VERSION "canboat-NMEA2000-curated"

NS_ :

BS_:

BU_: Vector__XXX
BO_ 2583631104 PGN_130837_maretronSwitchStatusTimer: 23 Vector__XXX
 SG_ Manufacturer_Code : 0|11@1+ (1.0,0) [0|2047] "" Vector__XXX
 SG_ Industry_Code : 13|3@1+ (1.0,0) [0|7] "" Vector__XXX
 SG_ Instance : 16|8@1+ (1.0,0) [0|255] "" Vector__XXX
 SG_ Indicator_Number : 24|8@1+ (1.0,0) [0|255] "" Vector__XXX
 SG_ Start_Date : 32|16@1+ (1.0,0) [0|65535] "" Vector__XXX
 SG_ Start_Time : 48|32@1+ (0.0001,0) [0.0|86401.0] "" Vector__XXX
 SG_ Accumulated_OFF_Period : 80|32@1+ (1.0,0) [0|4294967295] "" Vector__XXX
 SG_ Accumulated_ON_Period : 112|32@1+ (1.0,0) [0|4294967295] "" Vector__XXX
 SG_ Accumulated_ERROR_Period : 144|32@1+ (1.0,0) [0|4294967295] "" Vector__XXX
 SG_ Switch_Status : 176|2@1+ (1.0,0) [0|3] "" Vector__XXX

BO_ 2583631104 PGN_130837_simnetFuelFlowTurbineConfiguration: 8 Vector__XXX
 SG_ Manufacturer_Code : 0|11@1+ (1.0,0) [0|2047] "" Vector__XXX
 SG_ Industry_Code : 13|3@1+ (1.0,0) [0|7] "" Vector__XXX

BO_ 2583631104 PGN_130837_suzukiEngineSensorData: 8 Vector__XXX
 SG_ Manufacturer_Code : 0|11@1+ (1.0,0) [0|2047] "" Vector__XXX
 SG_ Industry_Code : 13|3@1+ (1.0,0) [0|7] "" Vector__XXX

BO_ 2583631360 PGN_130838_maretronBnwas: 223 Vector__XXX
 SG_ Manufacturer_Code : 0|11@1+ (1.0,0) [0|2047] "" Vector__XXX
 SG_ Industry_Code : 13|3@1+ (1.0,0) [0|7] "" Vector__XXX
 SG_ Data : 16|1768@1+ (1.0,0) [0|16635364987126134419907490844611231857889171561340108669757218330385068731224834608417815051548234195819468783937845710359164977421616154908223175941492902641772198991471137845920843845811776377869137773379678289214194183661112800944378464511794046030758602257005203964634516091405743061582849883160885255175229773660916874237270946647032424101972117051870087763059119895517977437771543686400460392041962138103436564399831189767740372774280024852942859855049773927338342604171805121253257539126169331943684033945189625789470637817855] "" Vector__XXX

BO_ 2583631360 PGN_130838_simnetFluidLevelWarning: 8 Vector__XXX
 SG_ Manufacturer_Code : 0|11@1+ (1.0,0) [0|2047] "" Vector__XXX
 SG_ Industry_Code : 13|3@1+ (1.0,0) [0|7] "" Vector__XXX

BO_ 2583631360 PGN_130838_suzukiFuelManagement: 8 Vector__XXX
 SG_ Manufacturer_Code : 0|11@1+ (1.0,0) [0|2047] "" Vector__XXX
 SG_ Industry_Code : 13|3@1+ (1.0,0) [0|7] "" Vector__XXX

BO_ 2583631616 PGN_130839_simnetPressureSensorConfiguration: 8 Vector__XXX
 SG_ Manufacturer_Code : 0|11@1+ (1.0,0) [0|2047] "" Vector__XXX
 SG_ Industry_Code : 13|3@1+ (1.0,0) [0|7] "" Vector__XXX

BO_ 2583631872 PGN_130840_maretronGenericSensor: 9 Vector__XXX
 SG_ Manufacturer_Code : 0|11@1+ (1.0,0) [0|2047] "" Vector__XXX
 SG_ Industry_Code : 13|3@1+ (1.0,0) [0|7] "" Vector__XXX
 SG_ Data_Instance : 16|8@1+ (1.0,0) [0|255] "" Vector__XXX
 SG_ Data_Format : 24|16@1+ (1.0,0) [0|65535] "" Vector__XXX
 SG_ Value : 40|32@1+ (1.0,0) [0|4294967295] "" Vector__XXX

BO_ 2382305280 PGN_130840_simnetDataSourceSelection: 17 Vector__XXX
 SG_ Manufacturer_Code : 0|11@1+ (1.0,0) [0|2047] "" Vector__XXX
 SG_ Industry_Code : 13|3@1+ (1.0,0) [0|7] "" Vector__XXX
 SG_ Data_Type : 24|8@1+ (1.0,0) [0|255] "" Vector__XXX
 SG_ Source_Class : 32|8@1+ (1.0,0) [0|255] "" Vector__XXX
 SG_ Source_Address : 40|8@1+ (1.0,0) [0|255] "" Vector__XXX
 SG_ Change_Counter : 56|8@1+ (1.0,0) [0|255] "" Vector__XXX
 SG_ Source : 64|64@1+ (1.0,0) [0|18446744073709551615] "" Vector__XXX

BO_ 2583632128 PGN_130841_maretronCanFrameForwarding: 223 Vector__XXX
 SG_ Manufacturer_Code : 0|11@1+ (1.0,0) [0|2047] "" Vector__XXX
 SG_ Industry_Code : 13|3@1+ (1.0,0) [0|7] "" Vector__XXX
 SG_ Data : 16|1768@1+ (1.0,0) [0|16635364987126134419907490844611231857889171561340108669757218330385068731224834608417815051548234195819468783937845710359164977421616154908223175941492902641772198991471137845920843845811776377869137773379678289214194183661112800944378464511794046030758602257005203964634516091405743061582849883160885255175229773660916874237270946647032424101972117051870087763059119895517977437771543686400460392041962138103436564399831189767740372774280024852942859855049773927338342604171805121253257539126169331943684033945189625789470637817855] "" Vector__XXX

BO_ 2583632384 PGN_130842_furunoSixDegreesOfFreedomMovement: 29 Vector__XXX
 SG_ Manufacturer_Code : 0|11@1+ (1.0,0) [0|2047] "" Vector__XXX
 SG_ Industry_Code : 13|3@1+ (1.0,0) [0|7] "" Vector__XXX
 SG_ A : 16|32@1- (1.0,0) [-2147483648|2147483647] "" Vector__XXX
 SG_ B : 48|32@1- (1.0,0) [-2147483648|2147483647] "" Vector__XXX
 SG_ C : 80|32@1- (1.0,0) [-2147483648|2147483647] "" Vector__XXX
 SG_ D : 112|8@1- (1.0,0) [-128|127] "" Vector__XXX
 SG_ Roll_Rate : 120|32@1- (1.7453292519943296e-05,0) [-37480.66029033894|37480.66027288565] "" Vector__XXX
 SG_ Pitch_Rate : 152|32@1- (1.7453292519943296e-05,0) [-37480.66029033894|37480.66027288565] "" Vector__XXX
 SG_ Yaw_Rate : 184|32@1- (1.7453292519943296e-05,0) [-37480.66029033894|37480.66027288565] "" Vector__XXX
 SG_ I : 216|16@1- (1.0,0) [-32768|32767] "" Vector__XXX

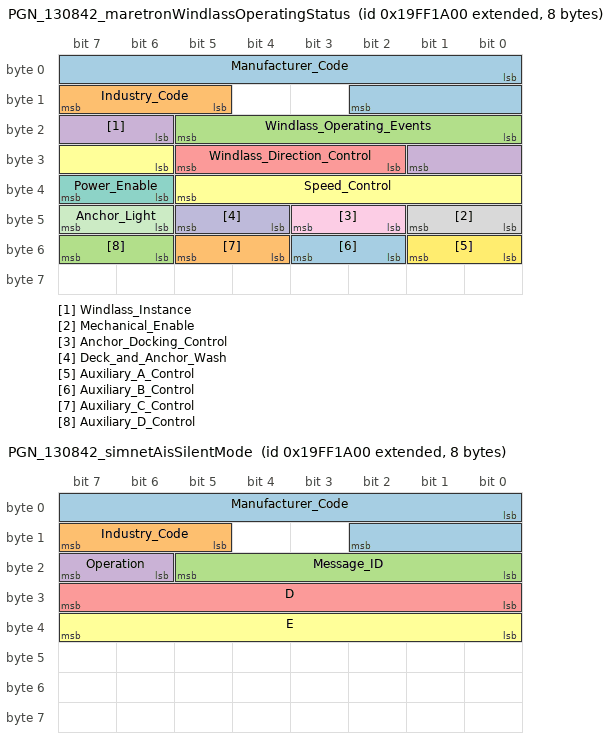
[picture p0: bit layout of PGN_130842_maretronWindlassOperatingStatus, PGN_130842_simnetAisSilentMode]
BO_ 2583632384 PGN_130842_maretronWindlassOperatingStatus: 8 Vector__XXX
 SG_ Manufacturer_Code : 0|11@1+ (1.0,0) [0|2047] "" Vector__XXX
 SG_ Industry_Code : 13|3@1+ (1.0,0) [0|7] "" Vector__XXX
 SG_ Windlass_Operating_Events : 16|6@1+ (1.0,0) [0|63] "" Vector__XXX
 SG_ Windlass_Instance : 22|4@1+ (1.0,0) [0|15] "" Vector__XXX
 SG_ Windlass_Direction_Control : 26|4@1+ (1.0,0) [0|15] "" Vector__XXX
 SG_ Speed_Control : 30|8@1+ (1.0,0) [0|255] "" Vector__XXX
 SG_ Power_Enable : 38|2@1+ (1.0,0) [0|3] "" Vector__XXX
 SG_ Mechanical_Enable : 40|2@1+ (1.0,0) [0|3] "" Vector__XXX
 SG_ Anchor_Docking_Control : 42|2@1+ (1.0,0) [0|3] "" Vector__XXX
 SG_ Deck_and_Anchor_Wash : 44|2@1+ (1.0,0) [0|3] "" Vector__XXX
 SG_ Anchor_Light : 46|2@1+ (1.0,0) [0|3] "" Vector__XXX
 SG_ Auxiliary_A_Control : 48|2@1+ (1.0,0) [0|3] "" Vector__XXX
 SG_ Auxiliary_B_Control : 50|2@1+ (1.0,0) [0|3] "" Vector__XXX
 SG_ Auxiliary_C_Control : 52|2@1+ (1.0,0) [0|3] "" Vector__XXX
 SG_ Auxiliary_D_Control : 54|2@1+ (1.0,0) [0|3] "" Vector__XXX

BO_ 2583632384 PGN_130842_simnetAisClassBStaticDataMsg24PartA: 29 Vector__XXX
 SG_ Manufacturer_Code : 0|11@1+ (1.0,0) [0|2047] "" Vector__XXX
 SG_ Industry_Code : 13|3@1+ (1.0,0) [0|7] "" Vector__XXX
 SG_ Message_ID : 16|6@1+ (1.0,0) [0|63] "" Vector__XXX
 SG_ Repeat_Indicator : 22|2@1+ (1.0,0) [0|3] "" Vector__XXX
 SG_ D : 24|8@1+ (1.0,0) [0|255] "" Vector__XXX
 SG_ E : 32|8@1+ (1.0,0) [0|255] "" Vector__XXX
 SG_ User_ID : 40|32@1+ (1.0,0) [2000000.0|999999999.0] "" Vector__XXX
 SG_ Name : 72|160@1+ (1.0,0) [0|1461501637330902918203684832716283019655932542975] "" Vector__XXX

BO_ 2583632384 PGN_130842_simnetAisClassBStaticDataMsg24PartB: 37 Vector__XXX
 SG_ Manufacturer_Code : 0|11@1+ (1.0,0) [0|2047] "" Vector__XXX
 SG_ Industry_Code : 13|3@1+ (1.0,0) [0|7] "" Vector__XXX
 SG_ Message_ID : 16|6@1+ (1.0,0) [0|63] "" Vector__XXX
 SG_ Repeat_Indicator : 22|2@1+ (1.0,0) [0|3] "" Vector__XXX
 SG_ D : 24|8@1+ (1.0,0) [0|255] "" Vector__XXX
 SG_ E : 32|8@1+ (1.0,0) [0|255] "" Vector__XXX
 SG_ User_ID : 40|32@1+ (1.0,0) [2000000.0|999999999.0] "" Vector__XXX
 SG_ Type_of_ship : 72|8@1+ (1.0,0) [0|255] "" Vector__XXX
 SG_ Vendor_ID : 80|56@1+ (1.0,0) [0|72057594037927935] "" Vector__XXX
 SG_ Callsign : 136|56@1+ (1.0,0) [0|72057594037927935] "" Vector__XXX
 SG_ Length : 192|16@1+ (0.1,0) [0.0|6553.5] "" Vector__XXX
 SG_ Beam : 208|16@1+ (0.1,0) [0.0|6553.5] "" Vector__XXX
 SG_ Position_reference_from_Starboard : 224|16@1+ (0.1,0) [0.0|6553.5] "" Vector__XXX
 SG_ Position_reference_from_Bow : 240|16@1+ (0.1,0) [0.0|6553.5] "" Vector__XXX
 SG_ Mothership_User_ID : 256|32@1+ (1.0,0) [2000000.0|999999999.0] "" Vector__XXX
 SG_ Spare : 288|6@1+ (1.0,0) [0|63] "" Vector__XXX

BO_ 2583632384 PGN_130842_simnetAisSilentMode: 8 Vector__XXX
 SG_ Manufacturer_Code : 0|11@1+ (1.0,0) [0|2047] "" Vector__XXX
 SG_ Industry_Code : 13|3@1+ (1.0,0) [0|7] "" Vector__XXX
 SG_ Message_ID : 16|6@1+ (1.0,0) [0|63] "" Vector__XXX
 SG_ Operation : 22|2@1+ (1.0,0) [0|3] "" Vector__XXX
 SG_ D : 24|8@1+ (1.0,0) [0|255] "" Vector__XXX
 SG_ E : 32|8@1+ (1.0,0) [0|255] "" Vector__XXX

BO_ 2583632640 PGN_130843_furunoHeelAngleRollInformation: 10 Vector__XXX
 SG_ Manufacturer_Code : 0|11@1+ (1.0,0) [0|2047] "" Vector__XXX
 SG_ Industry_Code : 13|3@1+ (1.0,0) [0|7] "" Vector__XXX
 SG_ Heel : 16|16@1- (0.0001,0) [-3.2768|3.2767] "" Vector__XXX
 SG_ Field_4 : 32|16@1- (0.0001,0) [-3.2768|3.2767] "" Vector__XXX
 SG_ Field_6 : 48|16@1- (0.0001,0) [-3.2768|3.2767] "" Vector__XXX
 SG_ Field_8 : 64|16@1- (0.0001,0) [-3.2768|3.2767] "" Vector__XXX

BO_ 2583632640 PGN_130843_maretronWindlassControlCommand: 223 Vector__XXX
 SG_ Manufacturer_Code : 0|11@1+ (1.0,0) [0|2047] "" Vector__XXX
 SG_ Industry_Code : 13|3@1+ (1.0,0) [0|7] "" Vector__XXX
 SG_ Data : 16|1768@1+ (1.0,0) [0|16635364987126134419907490844611231857889171561340108669757218330385068731224834608417815051548234195819468783937845710359164977421616154908223175941492902641772198991471137845920843845811776377869137773379678289214194183661112800944378464511794046030758602257005203964634516091405743061582849883160885255175229773660916874237270946647032424101972117051870087763059119895517977437771543686400460392041962138103436564399831189767740372774280024852942859855049773927338342604171805121253257539126169331943684033945189625789470637817855] "" Vector__XXX

BO_ 2583632640 PGN_130843_simnetSonarStatusFrequencyAndDspVoltage: 8 Vector__XXX
 SG_ Manufacturer_Code : 0|11@1+ (1.0,0) [0|2047] "" Vector__XXX
 SG_ Industry_Code : 13|3@1+ (1.0,0) [0|7] "" Vector__XXX

BO_ 2583632896 PGN_130844_carlingProprietary: 223 Vector__XXX
 SG_ Manufacturer_Code : 0|11@1+ (1.0,0) [0|2047] "" Vector__XXX
 SG_ Industry_Code : 13|3@1+ (1.0,0) [0|7] "" Vector__XXX
 SG_ Data : 16|1768@1+ (1.0,0) [0|16635364987126134419907490844611231857889171561340108669757218330385068731224834608417815051548234195819468783937845710359164977421616154908223175941492902641772198991471137845920843845811776377869137773379678289214194183661112800944378464511794046030758602257005203964634516091405743061582849883160885255175229773660916874237270946647032424101972117051870087763059119895517977437771543686400460392041962138103436564399831189767740372774280024852942859855049773927338342604171805121253257539126169331943684033945189625789470637817855] "" Vector__XXX

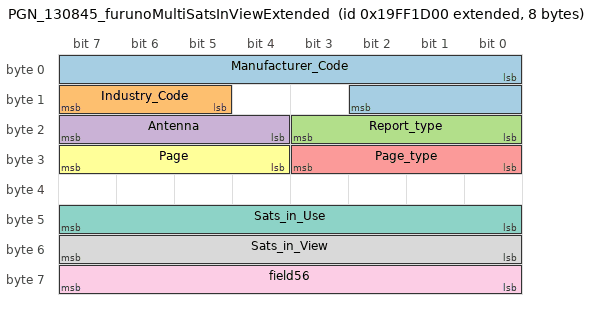
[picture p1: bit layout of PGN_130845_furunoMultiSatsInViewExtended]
BO_ 2583633152 PGN_130845_furunoMultiSatsInViewExtended: 8 Vector__XXX
 SG_ Manufacturer_Code : 0|11@1+ (1.0,0) [0|2047] "" Vector__XXX
 SG_ Industry_Code : 13|3@1+ (1.0,0) [0|7] "" Vector__XXX
 SG_ Report_type : 16|4@1+ (1.0,0) [0|15] "" Vector__XXX
 SG_ Antenna : 20|4@1+ (1.0,0) [0|15] "" Vector__XXX
 SG_ Page_type : 24|4@1+ (1.0,0) [0|15] "" Vector__XXX
 SG_ Page : 28|4@1+ (1.0,0) [0|15] "" Vector__XXX
 SG_ Sats_in_Use : 40|8@1+ (1.0,0) [0|255] "" Vector__XXX
 SG_ Sats_in_View : 48|8@1+ (1.0,0) [0|255] "" Vector__XXX
 SG_ field56 : 56|8@1+ (1.0,0) [0|255] "" Vector__XXX

BO_ 2583633152 PGN_130845_maretronDcEnergy: 223 Vector__XXX
 SG_ Manufacturer_Code : 0|11@1+ (1.0,0) [0|2047] "" Vector__XXX
 SG_ Industry_Code : 13|3@1+ (1.0,0) [0|7] "" Vector__XXX
 SG_ Data : 16|1768@1+ (1.0,0) [0|16635364987126134419907490844611231857889171561340108669757218330385068731224834608417815051548234195819468783937845710359164977421616154908223175941492902641772198991471137845920843845811776377869137773379678289214194183661112800944378464511794046030758602257005203964634516091405743061582849883160885255175229773660916874237270946647032424101972117051870087763059119895517977437771543686400460392041962138103436564399831189767740372774280024852942859855049773927338342604171805121253257539126169331943684033945189625789470637817855] "" Vector__XXX

BO_ 2583633152 PGN_130845_simnetKeyValue: 11 Vector__XXX
 SG_ Manufacturer_Code : 0|11@1+ (1.0,0) [0|2047] "" Vector__XXX
 SG_ Industry_Code : 13|3@1+ (1.0,0) [0|7] "" Vector__XXX
 SG_ Address : 16|8@1+ (1.0,0) [0|255] "" Vector__XXX
 SG_ Instance : 24|8@1+ (1.0,0) [0|255] "" Vector__XXX
 SG_ Network_Group : 32|8@1+ (1.0,0) [0|255] "" Vector__XXX
 SG_ Source : 40|8@1+ (1.0,0) [0|255] "" Vector__XXX
 SG_ Key : 48|24@1+ (1.0,0) [0|16777215] "" Vector__XXX
 SG_ Operation : 72|8@1+ (1.0,0) [0|255] "" Vector__XXX
 SG_ Value : 80|8@1+ (1.0,0) [0|255] "" Vector__XXX

CM_ BO_ 2583631104 "NMEA2000: PGN 130837 - Maretron: Switch Status Timer (type: Fast)";
CM_ BO_ 2583631104 "NMEA2000: PGN 130837 - Simnet: Fuel Flow Turbine Configuration (type: Fast)";
CM_ BO_ 2583631104 "NMEA2000: PGN 130837 - Suzuki: Engine Sensor Data (type: Fast)";
CM_ BO_ 2583631360 "NMEA2000: PGN 130838 - Maretron: BNWAS (type: Fast)";
CM_ BO_ 2583631360 "NMEA2000: PGN 130838 - Simnet: Fluid Level Warning (type: Fast)";
CM_ BO_ 2583631360 "NMEA2000: PGN 130838 - Suzuki: Fuel Management (type: Fast)";
CM_ BO_ 2583631616 "NMEA2000: PGN 130839 - Simnet: Pressure Sensor Configuration (type: Fast)";
CM_ BO_ 2583631872 "NMEA2000: PGN 130840 - Maretron: Generic Sensor (type: Fast)";
CM_ BO_ 2382305280 "NMEA2000: PGN 130840 - Simnet: Data Source Selection (type: Fast)";
CM_ BO_ 2583632128 "NMEA2000: PGN 130841 - Maretron: CAN Frame Forwarding (type: Fast)";
CM_ BO_ 2583632384 "NMEA2000: PGN 130842 - Furuno: Six Degrees Of Freedom Movement (type: Fast)";
CM_ BO_ 2583632384 "NMEA2000: PGN 130842 - Maretron: Windlass Operating Status (type: Fast)";
CM_ BO_ 2583632384 "NMEA2000: PGN 130842 - Simnet: AIS Class B static data (msg 24 Part A) (type: Fast)";
CM_ BO_ 2583632384 "NMEA2000: PGN 130842 - Simnet: AIS Class B static data (msg 24 Part B) (type: Fast)";
CM_ BO_ 2583632384 "NMEA2000: PGN 130842 - Simnet: AIS Silent Mode (type: Fast)";
CM_ BO_ 2583632640 "NMEA2000: PGN 130843 - Furuno: Heel Angle, Roll Information (type: Fast)";
CM_ BO_ 2583632640 "NMEA2000: PGN 130843 - Maretron: Windlass Control Command (type: Fast)";
CM_ BO_ 2583632640 "NMEA2000: PGN 130843 - Simnet: Sonar Status, Frequency and DSP Voltage (type: Fast)";
CM_ BO_ 2583632896 "NMEA2000: PGN 130844 - Carling: Proprietary (type: Fast)";
CM_ BO_ 2583633152 "NMEA2000: PGN 130845 - Furuno: Multi Sats In View Extended (type: Fast)";
CM_ BO_ 2583633152 "NMEA2000: PGN 130845 - Maretron: DC Energy (type: Fast)";
CM_ BO_ 2583633152 "NMEA2000: PGN 130845 - Simnet: Key Value (type: Fast)";
CM_ SG_ 2583631104 Manufacturer_Code "Maretron; canboat type: LOOKUP";
CM_ SG_ 2583631104 Industry_Code "Marine Industry; canboat type: LOOKUP";
CM_ SG_ 2583631104 Instance "canboat type: UINT8";
CM_ SG_ 2583631104 Indicator_Number "canboat type: UINT8";
CM_ SG_ 2583631104 Start_Date "canboat type: DATE";
CM_ SG_ 2583631104 Start_Time "Seconds since midnight; canboat type: TIME";
CM_ SG_ 2583631104 Accumulated_OFF_Period "canboat type: DURATION_UFIX32_S";
CM_ SG_ 2583631104 Accumulated_ON_Period "canboat type: DURATION_UFIX32_S";
CM_ SG_ 2583631104 Accumulated_ERROR_Period "canboat type: DURATION_UFIX32_S";
CM_ SG_ 2583631104 Switch_Status "canboat type: LOOKUP";
CM_ SG_ 2583631104 Manufacturer_Code "Simrad; canboat type: LOOKUP";
CM_ SG_ 2583631104 Industry_Code "Marine Industry; canboat type: LOOKUP";
CM_ SG_ 2583631104 Manufacturer_Code "Suzuki Motor Corporation; canboat type: LOOKUP";
CM_ SG_ 2583631104 Industry_Code "Marine Industry; canboat type: LOOKUP";
CM_ SG_ 2583631360 Manufacturer_Code "Maretron; canboat type: LOOKUP";
CM_ SG_ 2583631360 Industry_Code "Marine Industry; canboat type: LOOKUP";
CM_ SG_ 2583631360 Data "canboat type: BINARY";
CM_ SG_ 2583631360 Manufacturer_Code "Simrad; canboat type: LOOKUP";
CM_ SG_ 2583631360 Industry_Code "Marine Industry; canboat type: LOOKUP";
CM_ SG_ 2583631360 Manufacturer_Code "Suzuki Motor Corporation; canboat type: LOOKUP";
CM_ SG_ 2583631360 Industry_Code "Marine Industry; canboat type: LOOKUP";
CM_ SG_ 2583631616 Manufacturer_Code "Simrad; canboat type: LOOKUP";
CM_ SG_ 2583631616 Industry_Code "Marine Industry; canboat type: LOOKUP";
CM_ SG_ 2583631872 Manufacturer_Code "Maretron; canboat type: LOOKUP";
CM_ SG_ 2583631872 Industry_Code "Marine Industry; canboat type: LOOKUP";
CM_ SG_ 2583631872 Data_Instance "canboat type: UINT8";
CM_ SG_ 2583631872 Data_Format "canboat type: UINT16";
CM_ SG_ 2583631872 Value "canboat type: BINARY";
CM_ SG_ 2382305280 Manufacturer_Code "Simrad; canboat type: LOOKUP";
CM_ SG_ 2382305280 Industry_Code "Marine Industry; canboat type: LOOKUP";
CM_ SG_ 2382305280 Data_Type "canboat type: LOOKUP";
CM_ SG_ 2382305280 Source_Class "Class of source for this Data Type, constant per Data Type: observed as 1 for direct sensor/navigation sources and 100 for autopilot-provided sources; canboat type: UINT8";
CM_ SG_ 2382305280 Source_Address "canboat type: UINT8";
CM_ SG_ 2382305280 Change_Counter "canboat type: UINT8";
CM_ SG_ 2382305280 Source "canboat type: ISO_NAME";
CM_ SG_ 2583632128 Manufacturer_Code "Maretron; canboat type: LOOKUP";
CM_ SG_ 2583632128 Industry_Code "Marine Industry; canboat type: LOOKUP";
CM_ SG_ 2583632128 Data "canboat type: BINARY";
CM_ SG_ 2583632384 Manufacturer_Code "Furuno; canboat type: LOOKUP";
CM_ SG_ 2583632384 Industry_Code "Marine Industry; canboat type: LOOKUP";
CM_ SG_ 2583632384 A "canboat type: INT32";
CM_ SG_ 2583632384 B "canboat type: INT32";
CM_ SG_ 2583632384 C "canboat type: INT32";
CM_ SG_ 2583632384 D "canboat type: INT8";
CM_ SG_ 2583632384 Roll_Rate "canboat type: ROTATION_FIX32_MDEG_S";
CM_ SG_ 2583632384 Pitch_Rate "canboat type: ROTATION_FIX32_MDEG_S";
CM_ SG_ 2583632384 Yaw_Rate "canboat type: ROTATION_FIX32_MDEG_S";
CM_ SG_ 2583632384 I "canboat type: INT16";
CM_ SG_ 2583632384 Manufacturer_Code "Maretron; canboat type: LOOKUP";
CM_ SG_ 2583632384 Industry_Code "Marine Industry; canboat type: LOOKUP";
CM_ SG_ 2583632384 Windlass_Operating_Events "canboat type: UNSIGNED_INTEGER";
CM_ SG_ 2583632384 Windlass_Instance "canboat type: UNSIGNED_INTEGER";
CM_ SG_ 2583632384 Windlass_Direction_Control "canboat type: UNSIGNED_INTEGER";
CM_ SG_ 2583632384 Speed_Control "canboat type: UINT8";
CM_ SG_ 2583632384 Power_Enable "canboat type: LOOKUP";
CM_ SG_ 2583632384 Mechanical_Enable "canboat type: LOOKUP";
CM_ SG_ 2583632384 Anchor_Docking_Control "canboat type: LOOKUP";
CM_ SG_ 2583632384 Deck_and_Anchor_Wash "canboat type: LOOKUP";
CM_ SG_ 2583632384 Anchor_Light "canboat type: LOOKUP";
CM_ SG_ 2583632384 Auxiliary_A_Control "canboat type: LOOKUP";
CM_ SG_ 2583632384 Auxiliary_B_Control "canboat type: LOOKUP";
CM_ SG_ 2583632384 Auxiliary_C_Control "canboat type: LOOKUP";
CM_ SG_ 2583632384 Auxiliary_D_Control "canboat type: LOOKUP";
CM_ SG_ 2583632384 Manufacturer_Code "Simrad; canboat type: LOOKUP";
CM_ SG_ 2583632384 Industry_Code "Marine Industry; canboat type: LOOKUP";
CM_ SG_ 2583632384 Message_ID "Msg 24 Part A; canboat type: UNSIGNED_INTEGER";
CM_ SG_ 2583632384 Repeat_Indicator "canboat type: LOOKUP";
CM_ SG_ 2583632384 D "canboat type: UINT8";
CM_ SG_ 2583632384 E "canboat type: UINT8";
CM_ SG_ 2583632384 User_ID "canboat type: MMSI";
CM_ SG_ 2583632384 Name "canboat type: STRING_FIX";
CM_ SG_ 2583632384 Manufacturer_Code "Simrad; canboat type: LOOKUP";
CM_ SG_ 2583632384 Industry_Code "Marine Industry; canboat type: LOOKUP";
CM_ SG_ 2583632384 Message_ID "Msg 24 Part B; canboat type: UNSIGNED_INTEGER";
CM_ SG_ 2583632384 Repeat_Indicator "canboat type: LOOKUP";
CM_ SG_ 2583632384 D "canboat type: UINT8";
CM_ SG_ 2583632384 E "canboat type: UINT8";
CM_ SG_ 2583632384 User_ID "canboat type: MMSI";
CM_ SG_ 2583632384 Type_of_ship "canboat type: LOOKUP";
CM_ SG_ 2583632384 Vendor_ID "canboat type: STRING_FIX";
CM_ SG_ 2583632384 Callsign "canboat type: STRING_FIX";
CM_ SG_ 2583632384 Length "canboat type: LENGTH_UFIX16_DM";
CM_ SG_ 2583632384 Beam "canboat type: LENGTH_UFIX16_DM";
CM_ SG_ 2583632384 Position_reference_from_Starboard "canboat type: LENGTH_UFIX16_DM";
CM_ SG_ 2583632384 Position_reference_from_Bow "canboat type: LENGTH_UFIX16_DM";
CM_ SG_ 2583632384 Mothership_User_ID "canboat type: MMSI";
CM_ SG_ 2583632384 Spare "canboat type: SPARE";
CM_ SG_ 2583632384 Manufacturer_Code "Simrad; canboat type: LOOKUP";
CM_ SG_ 2583632384 Industry_Code "Marine Industry; canboat type: LOOKUP";
CM_ SG_ 2583632384 Message_ID "AIS Silent Mode; canboat type: UNSIGNED_INTEGER";
CM_ SG_ 2583632384 Operation "canboat type: LOOKUP";
CM_ SG_ 2583632384 D "canboat type: UINT8";
CM_ SG_ 2583632384 E "canboat type: UINT8";
CM_ SG_ 2583632640 Manufacturer_Code "Furuno; canboat type: LOOKUP";
CM_ SG_ 2583632640 Industry_Code "Marine Industry; canboat type: LOOKUP";
CM_ SG_ 2583632640 Heel "Live heel/roll; verified == PGN 127257 Roll; canboat type: ANGLE_FIX16";
CM_ SG_ 2583632640 Field_4 "canboat type: ANGLE_FIX16";
CM_ SG_ 2583632640 Field_6 "canboat type: ANGLE_FIX16";
CM_ SG_ 2583632640 Field_8 "canboat type: ANGLE_FIX16";
CM_ SG_ 2583632640 Manufacturer_Code "Maretron; canboat type: LOOKUP";
CM_ SG_ 2583632640 Industry_Code "Marine Industry; canboat type: LOOKUP";
CM_ SG_ 2583632640 Data "canboat type: BINARY";
CM_ SG_ 2583632640 Manufacturer_Code "Simrad; canboat type: LOOKUP";
CM_ SG_ 2583632640 Industry_Code "Marine Industry; canboat type: LOOKUP";
CM_ SG_ 2583632896 Manufacturer_Code "Carling Technologies Inc. (Moritz Aerospace); canboat type: LOOKUP";
CM_ SG_ 2583632896 Industry_Code "Marine Industry; canboat type: LOOKUP";
CM_ SG_ 2583632896 Data "canboat type: BINARY";
CM_ SG_ 2583633152 Manufacturer_Code "Furuno; canboat type: LOOKUP";
CM_ SG_ 2583633152 Industry_Code "Marine Industry; canboat type: LOOKUP";
CM_ SG_ 2583633152 Report_type "canboat type: UNSIGNED_INTEGER";
CM_ SG_ 2583633152 Antenna "canboat type: UNSIGNED_INTEGER";
CM_ SG_ 2583633152 Page_type "canboat type: UNSIGNED_INTEGER";
CM_ SG_ 2583633152 Page "canboat type: UNSIGNED_INTEGER";
CM_ SG_ 2583633152 Sats_in_Use "canboat type: UINT8";
CM_ SG_ 2583633152 Sats_in_View "canboat type: UINT8";
CM_ SG_ 2583633152 field56 "canboat type: NUMBER";
CM_ SG_ 2583633152 Manufacturer_Code "Maretron; canboat type: LOOKUP";
CM_ SG_ 2583633152 Industry_Code "Marine Industry; canboat type: LOOKUP";
CM_ SG_ 2583633152 Data "canboat type: BINARY";
CM_ SG_ 2583633152 Manufacturer_Code "Simrad; canboat type: LOOKUP";
CM_ SG_ 2583633152 Industry_Code "Marine Industry; canboat type: LOOKUP";
CM_ SG_ 2583633152 Address "NMEA 2000 address of commanded device; canboat type: UINT8";
CM_ SG_ 2583633152 Instance "Instance index when a Key has multiple sources/instances; 0xFF when not applicable. Caller-supplied and echoed back in replies.; canboat type: UINT8";
CM_ SG_ 2583633152 Network_Group "This can be either the Display Group, Units Group, Damping Group or Alarms Group, depending on which key is being set; canboat type: LOOKUP";
CM_ SG_ 2583633152 Source "Source/owner that provided the value; set by the responder when Operation = Reply, 0xFF in read/set requests. This is NOT an NMEA 2000 bus address.; canboat type: UINT8";
CM_ SG_ 2583633152 Key "Composite 24-bit little-endian key = command group (low byte) | parameter key (upper 16 bits) << 8. The two parts are NOT split into separate fields because the parameter key is only unique within a command group (e.g. key 1 is 'True wind high' in group 4 but 'Deep water' in group 8), so the value's data type can only be resolved from the group and key together. This key space is distinct from the PGN 130822 tDataType ids and from the B&G and Mercury key spaces.; canboat type: DYNAMIC_FIELD_KEY";
CM_ SG_ 2583633152 Operation "canboat type: LOOKUP";
CM_ SG_ 2583633152 Value "Always 4 bytes on the bus but actual width and datatype defined per key; canboat type: DYNAMIC_FIELD_VALUE";
VAL_ 2583631104 Manufacturer_Code 69 "ARKS Enterprises" 78 "FW Murphy/Enovation Controls" 80 "Twin Disc" 85 "Kohler Power Systems" 88 "Hemisphere GPS" 135 "Airmar" 137 "Maretron" 140 "Lowrance" 144 "Mercury Marine" 147 "Nautibus Electronic" 148 "Blue Water Data" 154 "Westerbeke" 157 "ISSPRO" 161 "Offshore Systems (UK)" 163 "Evinrude/BRP" 165 "CPAC Systems" 168 "Xantrex Technology" 169 "Marlin Technologies" 172 "Yanmar Marine" 174 "Volvo Penta" 176 "Carling Technologies Inc. (Moritz Aerospace)" 185 "Beede Instruments" 192 "Floscan Instrument" 193 "Nobeltec" 198 "Mystic Valley Communications" 199 "Actia" 201 "Disenos Y Technologia" 211 "Digital Switching Systems" 215 "Xintex/Atena" 224 "EMMI NETWORK" 228 "ZF" 229 "Garmin" 233 "Yacht Monitoring Solutions" 235 "Sailormade Marine Telemetry/Tetra Technology" 243 "Eride" 257 "Honda Motor" 272 "Groco" 273 "Actisense" 274 "Amphenol LTW Technology" 275 "Navico" 283 "Hamilton Jet" 285 "Sea Recovery" 286 "Coelmo SRL Italy" 295 "BEP Marine" 304 "Empir Bus" 305 "NovAtel" 306 "Sleipner Motor" 307 "MBW Technologies" 315 "ICOM" 328 "Qwerty" 329 "Dief" 341 "Boening Automationstechnologie" 345 "Korean Maritime University" 351 "Thrane and Thrane" 355 "Mastervolt" 356 "Fischer Panda Generators" 358 "Victron Energy" 370 "Rolls Royce Marine" 373 "Electronic Design" 374 "Northern Lights" 378 "Glendinning" 381 "B & G" 384 "Rose Point Navigation Systems" 385 "Johnson Outdoors Marine Electronics Inc Geonav" 394 "Capi 2" 396 "Beyond Measure" 400 "Livorsi Marine" 404 "ComNav" 409 "Chetco" 419 "Fusion Electronics" 421 "Standard Horizon" 422 "True Heading" 426 "Egersund Marine Electronics" 427 "em-trak Marine Electronics" 431 "Tohatsu Co, JP" 437 "Digital Yacht" 438 "Comar Systems Limited" 440 "Cummins" 443 "VDO (aka Continental-Corporation)" 451 "Parker Hannifin aka Village Marine Tech" 459 "Alltek Marine Electronics" 460 "SAN GIORGIO S.E.I.N" 466 "Veethree Electronics & Marine" 470 "SI-TEX Marine Electronics" 471 "Sea Cross Marine" 475 "GME aka Standard Communications" 476 "Humminbird Marine Electronics" 478 "Ocean Sat" 481 "Chetco Digital Instruments" 493 "Watcheye" 499 "Lcj Capteurs" 502 "Attwood Marine" 503 "Naviop S.R.L." 504 "Vesper Marine" 510 "Marinesoft" 513 "Simarine" 517 "NoLand Engineering" 518 "Transas USA" 529 "National Instruments Korea" 530 "National Marine Electronics Association" 532 "Onwa Marine" 540 "Webasto" 571 "Marinecraft (South Korea)" 573 "McMurdo Group aka Orolia" 578 "Advansea" 579 "KVH" 580 "San Jose Technology" 583 "Yacht Control" 586 "Suzuki Motor" 591 "US Coast Guard" 595 "Ship Module aka Customware" 600 "Aquatic AV" 605 "Aventics" 606 "Intellian" 612 "SamwonIT" 614 "Arlt Tecnologies" 637 "Bavaria Yachts" 641 "Diverse Yacht Services" 644 "Wema U.S.A dba KUS" 658 "Shenzhen Jiuzhou Himunication" 688 "Rockford" 699 "Harman International" 704 "JL Audio" 708 "Lars Thrane" 715 "Autonnic" 717 "Yacht Devices" 734 "REAP Systems" 735 "AEM Performance Electronics" 739 "LxNav" 741 "Littelfuse, Inc (formerly Carling Technologies)" 743 "DaeMyung" 744 "Woosung" 748 "ISOTTA IFRA srl" 773 "Clarion US" 776 "HMI Systems" 777 "Ocean Signal" 778 "Seakeeper" 781 "Poly Planar" 785 "Fischer Panda DE" 795 "Broyda Industries" 796 "Canadian Automotive" 797 "Tides Marine" 798 "Lumishore" 799 "Still Water Designs and Audio" 802 "BJ Technologies (Beneteau)" 803 "Gill Sensors" 811 "Blue Water Desalination" 815 "FLIR" 824 "Undheim Systems" 826 "Lewmar" 838 "TeamSurv" 844 "Fell Marine" 847 "Oceanvolt" 862 "Prospec" 868 "Data Panel" 890 "L3 Technologies" 894 "Rhodan Marine Systems" 896 "Nexfour Solutions" 905 "ASA Electronics" 909 "Marines Co (South Korea)" 911 "Nautic-on" 917 "Sentinel" 929 "JL Marine Systems" 930 "Ecotronix" 944 "Zontisa Marine" 951 "EXOR International" 962 "Timbolier Industries" 963 "TJC Micro" 968 "Cox Powertrain" 969 "Blue Seas" 981 "Kobelt Manufacturing" 992 "Blue Ocean IOT" 997 "Xenta Systems" 999 "Signal K" 1004 "Ultraflex" 1008 "Lintest SmartBoat" 1011 "Soundmax" 1020 "Team Italia Marine (Onyx Marine Automation s.r.l)" 1021 "Entratech" 1022 "ITC" 1029 "The Marine Guardian" 1047 "Sonic" 1051 "ProNav" 1053 "Vetus Maxwell INC." 1056 "Lithium Pros" 1059 "Boatrax" 1062 "Marol Co ltd" 1065 "CALYPSO Instruments" 1066 "Spot Zero Water" 1069 "Lithionics Battery" 1070 "Quick-teck Electronics" 1075 "Uniden America" 1083 "Nauticoncept" 1084 "Shadow-Caster LED lighting" 1085 "Wet Sounds" 1088 "E-T-A Circuit Breakers" 1092 "Scheiber" 1100 "Smart Yachts International Limited" 1109 "Dockmate" 1114 "Bobs Machine" 1118 "L3Harris ASV" 1119 "Balmar" 1120 "Elettromedia" 1127 "Electromaax" 1140 "Across Oceans Systems" 1145 "Kiwi Yachting" 1150 "BSB Artificial Intelligence" 1151 "Orca Technologies" 1154 "TBS Electronics" 1158 "Technoton Electroics" 1160 "MG Energy Systems" 1169 "Sea Machine Robotics" 1171 "Vista Manufacturing" 1183 "Zipwake" 1186 "Sailmon" 1192 "Airmoniq Pro Kft" 1194 "Sierra Marine" 1200 "Xinuo Information Technology (Xiamen)" 1218 "Septentrio" 1233 "NKE Marine Electronics" 1238 "SuperTrack Aps" 1239 "Honda Electronics" 1245 "Raritan Engineering" 1249 "Integrated Power Solutions AG" 1260 "Interactive Technologies" 1283 "LTG-Tech" 1299 "Energy Solutions (UK)" 1300 "WATT Fuel Cell" 1302 "Pro Mainer" 1305 "Dragonfly Energy" 1306 "Koden Electronics" 1311 "Humphree" 1316 "Hinkley Yachts" 1317 "Global Marine Management GmbH (GMM)" 1320 "Triskel Marine" 1330 "Warwick Control Technologies" 1331 "Dolphin Charger" 1337 "Barnacle Systems" 1348 "Radian IoT" 1353 "Ocean LED Marine" 1359 "BluNav" 1361 "OVA (Nantong Saiyang Electronics Co., Ltd)" 1368 "RAD Propulsion" 1369 "Electric Yacht" 1372 "Elco Motor Yachts" 1384 "Tecnoseal Foundry S.r.l" 1385 "Pro Charging Systems" 1389 "EVEX" 1398 "Gobius Sensor Technology" 1403 "Arco Marine" 1408 "Lenco Marine" 1413 "Naocontrol" 1417 "Revatek" 1438 "Aeolionics" 1439 "PredictWind" 1440 "Egis Mobile Electric" 1445 "Starboard Yacht Group" 1446 "Roswell Marine" 1451 "ePropulsion (Guangdong ePropulsion Technology Ltd.)" 1452 "Micro-Air" 1453 "Vital Battery" 1458 "Ride Controller" 1460 "Tocaro Blue" 1461 "Vanquish Yachts" 1471 "FT Technologies" 1478 "Alps Alpine" 1481 "E-Force Marine" 1482 "CMC Marine" 1483 "Nanjing Sandemarine Information Technology" 1850 "Teleflex Marine (SeaStar Solutions)" 1851 "Raymarine" 1852 "Navionics" 1853 "Japan Radio" 1854 "Northstar Technologies" 1855 "Furuno" 1856 "Trimble" 1857 "Simrad" 1858 "Litton" 1859 "Kvasar" 1860 "MMP" 1861 "Vector Cantech" 1862 "Yamaha Marine" 1863 "Faria Instruments" ;
VAL_ 2583631104 Industry_Code 0 "Global" 1 "Highway" 2 "Agriculture" 3 "Construction" 4 "Marine Industry" 5 "Industrial" ;
VAL_ 2583631104 Switch_Status 0 "Off" 1 "On" ;
VAL_ 2583631104 Manufacturer_Code 69 "ARKS Enterprises" 78 "FW Murphy/Enovation Controls" 80 "Twin Disc" 85 "Kohler Power Systems" 88 "Hemisphere GPS" 135 "Airmar" 137 "Maretron" 140 "Lowrance" 144 "Mercury Marine" 147 "Nautibus Electronic" 148 "Blue Water Data" 154 "Westerbeke" 157 "ISSPRO" 161 "Offshore Systems (UK)" 163 "Evinrude/BRP" 165 "CPAC Systems" 168 "Xantrex Technology" 169 "Marlin Technologies" 172 "Yanmar Marine" 174 "Volvo Penta" 176 "Carling Technologies Inc. (Moritz Aerospace)" 185 "Beede Instruments" 192 "Floscan Instrument" 193 "Nobeltec" 198 "Mystic Valley Communications" 199 "Actia" 201 "Disenos Y Technologia" 211 "Digital Switching Systems" 215 "Xintex/Atena" 224 "EMMI NETWORK" 228 "ZF" 229 "Garmin" 233 "Yacht Monitoring Solutions" 235 "Sailormade Marine Telemetry/Tetra Technology" 243 "Eride" 257 "Honda Motor" 272 "Groco" 273 "Actisense" 274 "Amphenol LTW Technology" 275 "Navico" 283 "Hamilton Jet" 285 "Sea Recovery" 286 "Coelmo SRL Italy" 295 "BEP Marine" 304 "Empir Bus" 305 "NovAtel" 306 "Sleipner Motor" 307 "MBW Technologies" 315 "ICOM" 328 "Qwerty" 329 "Dief" 341 "Boening Automationstechnologie" 345 "Korean Maritime University" 351 "Thrane and Thrane" 355 "Mastervolt" 356 "Fischer Panda Generators" 358 "Victron Energy" 370 "Rolls Royce Marine" 373 "Electronic Design" 374 "Northern Lights" 378 "Glendinning" 381 "B & G" 384 "Rose Point Navigation Systems" 385 "Johnson Outdoors Marine Electronics Inc Geonav" 394 "Capi 2" 396 "Beyond Measure" 400 "Livorsi Marine" 404 "ComNav" 409 "Chetco" 419 "Fusion Electronics" 421 "Standard Horizon" 422 "True Heading" 426 "Egersund Marine Electronics" 427 "em-trak Marine Electronics" 431 "Tohatsu Co, JP" 437 "Digital Yacht" 438 "Comar Systems Limited" 440 "Cummins" 443 "VDO (aka Continental-Corporation)" 451 "Parker Hannifin aka Village Marine Tech" 459 "Alltek Marine Electronics" 460 "SAN GIORGIO S.E.I.N" 466 "Veethree Electronics & Marine" 470 "SI-TEX Marine Electronics" 471 "Sea Cross Marine" 475 "GME aka Standard Communications" 476 "Humminbird Marine Electronics" 478 "Ocean Sat" 481 "Chetco Digital Instruments" 493 "Watcheye" 499 "Lcj Capteurs" 502 "Attwood Marine" 503 "Naviop S.R.L." 504 "Vesper Marine" 510 "Marinesoft" 513 "Simarine" 517 "NoLand Engineering" 518 "Transas USA" 529 "National Instruments Korea" 530 "National Marine Electronics Association" 532 "Onwa Marine" 540 "Webasto" 571 "Marinecraft (South Korea)" 573 "McMurdo Group aka Orolia" 578 "Advansea" 579 "KVH" 580 "San Jose Technology" 583 "Yacht Control" 586 "Suzuki Motor" 591 "US Coast Guard" 595 "Ship Module aka Customware" 600 "Aquatic AV" 605 "Aventics" 606 "Intellian" 612 "SamwonIT" 614 "Arlt Tecnologies" 637 "Bavaria Yachts" 641 "Diverse Yacht Services" 644 "Wema U.S.A dba KUS" 658 "Shenzhen Jiuzhou Himunication" 688 "Rockford" 699 "Harman International" 704 "JL Audio" 708 "Lars Thrane" 715 "Autonnic" 717 "Yacht Devices" 734 "REAP Systems" 735 "AEM Performance Electronics" 739 "LxNav" 741 "Littelfuse, Inc (formerly Carling Technologies)" 743 "DaeMyung" 744 "Woosung" 748 "ISOTTA IFRA srl" 773 "Clarion US" 776 "HMI Systems" 777 "Ocean Signal" 778 "Seakeeper" 781 "Poly Planar" 785 "Fischer Panda DE" 795 "Broyda Industries" 796 "Canadian Automotive" 797 "Tides Marine" 798 "Lumishore" 799 "Still Water Designs and Audio" 802 "BJ Technologies (Beneteau)" 803 "Gill Sensors" 811 "Blue Water Desalination" 815 "FLIR" 824 "Undheim Systems" 826 "Lewmar" 838 "TeamSurv" 844 "Fell Marine" 847 "Oceanvolt" 862 "Prospec" 868 "Data Panel" 890 "L3 Technologies" 894 "Rhodan Marine Systems" 896 "Nexfour Solutions" 905 "ASA Electronics" 909 "Marines Co (South Korea)" 911 "Nautic-on" 917 "Sentinel" 929 "JL Marine Systems" 930 "Ecotronix" 944 "Zontisa Marine" 951 "EXOR International" 962 "Timbolier Industries" 963 "TJC Micro" 968 "Cox Powertrain" 969 "Blue Seas" 981 "Kobelt Manufacturing" 992 "Blue Ocean IOT" 997 "Xenta Systems" 999 "Signal K" 1004 "Ultraflex" 1008 "Lintest SmartBoat" 1011 "Soundmax" 1020 "Team Italia Marine (Onyx Marine Automation s.r.l)" 1021 "Entratech" 1022 "ITC" 1029 "The Marine Guardian" 1047 "Sonic" 1051 "ProNav" 1053 "Vetus Maxwell INC." 1056 "Lithium Pros" 1059 "Boatrax" 1062 "Marol Co ltd" 1065 "CALYPSO Instruments" 1066 "Spot Zero Water" 1069 "Lithionics Battery" 1070 "Quick-teck Electronics" 1075 "Uniden America" 1083 "Nauticoncept" 1084 "Shadow-Caster LED lighting" 1085 "Wet Sounds" 1088 "E-T-A Circuit Breakers" 1092 "Scheiber" 1100 "Smart Yachts International Limited" 1109 "Dockmate" 1114 "Bobs Machine" 1118 "L3Harris ASV" 1119 "Balmar" 1120 "Elettromedia" 1127 "Electromaax" 1140 "Across Oceans Systems" 1145 "Kiwi Yachting" 1150 "BSB Artificial Intelligence" 1151 "Orca Technologies" 1154 "TBS Electronics" 1158 "Technoton Electroics" 1160 "MG Energy Systems" 1169 "Sea Machine Robotics" 1171 "Vista Manufacturing" 1183 "Zipwake" 1186 "Sailmon" 1192 "Airmoniq Pro Kft" 1194 "Sierra Marine" 1200 "Xinuo Information Technology (Xiamen)" 1218 "Septentrio" 1233 "NKE Marine Electronics" 1238 "SuperTrack Aps" 1239 "Honda Electronics" 1245 "Raritan Engineering" 1249 "Integrated Power Solutions AG" 1260 "Interactive Technologies" 1283 "LTG-Tech" 1299 "Energy Solutions (UK)" 1300 "WATT Fuel Cell" 1302 "Pro Mainer" 1305 "Dragonfly Energy" 1306 "Koden Electronics" 1311 "Humphree" 1316 "Hinkley Yachts" 1317 "Global Marine Management GmbH (GMM)" 1320 "Triskel Marine" 1330 "Warwick Control Technologies" 1331 "Dolphin Charger" 1337 "Barnacle Systems" 1348 "Radian IoT" 1353 "Ocean LED Marine" 1359 "BluNav" 1361 "OVA (Nantong Saiyang Electronics Co., Ltd)" 1368 "RAD Propulsion" 1369 "Electric Yacht" 1372 "Elco Motor Yachts" 1384 "Tecnoseal Foundry S.r.l" 1385 "Pro Charging Systems" 1389 "EVEX" 1398 "Gobius Sensor Technology" 1403 "Arco Marine" 1408 "Lenco Marine" 1413 "Naocontrol" 1417 "Revatek" 1438 "Aeolionics" 1439 "PredictWind" 1440 "Egis Mobile Electric" 1445 "Starboard Yacht Group" 1446 "Roswell Marine" 1451 "ePropulsion (Guangdong ePropulsion Technology Ltd.)" 1452 "Micro-Air" 1453 "Vital Battery" 1458 "Ride Controller" 1460 "Tocaro Blue" 1461 "Vanquish Yachts" 1471 "FT Technologies" 1478 "Alps Alpine" 1481 "E-Force Marine" 1482 "CMC Marine" 1483 "Nanjing Sandemarine Information Technology" 1850 "Teleflex Marine (SeaStar Solutions)" 1851 "Raymarine" 1852 "Navionics" 1853 "Japan Radio" 1854 "Northstar Technologies" 1855 "Furuno" 1856 "Trimble" 1857 "Simrad" 1858 "Litton" 1859 "Kvasar" 1860 "MMP" 1861 "Vector Cantech" 1862 "Yamaha Marine" 1863 "Faria Instruments" ;
VAL_ 2583631104 Industry_Code 0 "Global" 1 "Highway" 2 "Agriculture" 3 "Construction" 4 "Marine Industry" 5 "Industrial" ;
VAL_ 2583631104 Manufacturer_Code 69 "ARKS Enterprises" 78 "FW Murphy/Enovation Controls" 80 "Twin Disc" 85 "Kohler Power Systems" 88 "Hemisphere GPS" 135 "Airmar" 137 "Maretron" 140 "Lowrance" 144 "Mercury Marine" 147 "Nautibus Electronic" 148 "Blue Water Data" 154 "Westerbeke" 157 "ISSPRO" 161 "Offshore Systems (UK)" 163 "Evinrude/BRP" 165 "CPAC Systems" 168 "Xantrex Technology" 169 "Marlin Technologies" 172 "Yanmar Marine" 174 "Volvo Penta" 176 "Carling Technologies Inc. (Moritz Aerospace)" 185 "Beede Instruments" 192 "Floscan Instrument" 193 "Nobeltec" 198 "Mystic Valley Communications" 199 "Actia" 201 "Disenos Y Technologia" 211 "Digital Switching Systems" 215 "Xintex/Atena" 224 "EMMI NETWORK" 228 "ZF" 229 "Garmin" 233 "Yacht Monitoring Solutions" 235 "Sailormade Marine Telemetry/Tetra Technology" 243 "Eride" 257 "Honda Motor" 272 "Groco" 273 "Actisense" 274 "Amphenol LTW Technology" 275 "Navico" 283 "Hamilton Jet" 285 "Sea Recovery" 286 "Coelmo SRL Italy" 295 "BEP Marine" 304 "Empir Bus" 305 "NovAtel" 306 "Sleipner Motor" 307 "MBW Technologies" 315 "ICOM" 328 "Qwerty" 329 "Dief" 341 "Boening Automationstechnologie" 345 "Korean Maritime University" 351 "Thrane and Thrane" 355 "Mastervolt" 356 "Fischer Panda Generators" 358 "Victron Energy" 370 "Rolls Royce Marine" 373 "Electronic Design" 374 "Northern Lights" 378 "Glendinning" 381 "B & G" 384 "Rose Point Navigation Systems" 385 "Johnson Outdoors Marine Electronics Inc Geonav" 394 "Capi 2" 396 "Beyond Measure" 400 "Livorsi Marine" 404 "ComNav" 409 "Chetco" 419 "Fusion Electronics" 421 "Standard Horizon" 422 "True Heading" 426 "Egersund Marine Electronics" 427 "em-trak Marine Electronics" 431 "Tohatsu Co, JP" 437 "Digital Yacht" 438 "Comar Systems Limited" 440 "Cummins" 443 "VDO (aka Continental-Corporation)" 451 "Parker Hannifin aka Village Marine Tech" 459 "Alltek Marine Electronics" 460 "SAN GIORGIO S.E.I.N" 466 "Veethree Electronics & Marine" 470 "SI-TEX Marine Electronics" 471 "Sea Cross Marine" 475 "GME aka Standard Communications" 476 "Humminbird Marine Electronics" 478 "Ocean Sat" 481 "Chetco Digital Instruments" 493 "Watcheye" 499 "Lcj Capteurs" 502 "Attwood Marine" 503 "Naviop S.R.L." 504 "Vesper Marine" 510 "Marinesoft" 513 "Simarine" 517 "NoLand Engineering" 518 "Transas USA" 529 "National Instruments Korea" 530 "National Marine Electronics Association" 532 "Onwa Marine" 540 "Webasto" 571 "Marinecraft (South Korea)" 573 "McMurdo Group aka Orolia" 578 "Advansea" 579 "KVH" 580 "San Jose Technology" 583 "Yacht Control" 586 "Suzuki Motor" 591 "US Coast Guard" 595 "Ship Module aka Customware" 600 "Aquatic AV" 605 "Aventics" 606 "Intellian" 612 "SamwonIT" 614 "Arlt Tecnologies" 637 "Bavaria Yachts" 641 "Diverse Yacht Services" 644 "Wema U.S.A dba KUS" 658 "Shenzhen Jiuzhou Himunication" 688 "Rockford" 699 "Harman International" 704 "JL Audio" 708 "Lars Thrane" 715 "Autonnic" 717 "Yacht Devices" 734 "REAP Systems" 735 "AEM Performance Electronics" 739 "LxNav" 741 "Littelfuse, Inc (formerly Carling Technologies)" 743 "DaeMyung" 744 "Woosung" 748 "ISOTTA IFRA srl" 773 "Clarion US" 776 "HMI Systems" 777 "Ocean Signal" 778 "Seakeeper" 781 "Poly Planar" 785 "Fischer Panda DE" 795 "Broyda Industries" 796 "Canadian Automotive" 797 "Tides Marine" 798 "Lumishore" 799 "Still Water Designs and Audio" 802 "BJ Technologies (Beneteau)" 803 "Gill Sensors" 811 "Blue Water Desalination" 815 "FLIR" 824 "Undheim Systems" 826 "Lewmar" 838 "TeamSurv" 844 "Fell Marine" 847 "Oceanvolt" 862 "Prospec" 868 "Data Panel" 890 "L3 Technologies" 894 "Rhodan Marine Systems" 896 "Nexfour Solutions" 905 "ASA Electronics" 909 "Marines Co (South Korea)" 911 "Nautic-on" 917 "Sentinel" 929 "JL Marine Systems" 930 "Ecotronix" 944 "Zontisa Marine" 951 "EXOR International" 962 "Timbolier Industries" 963 "TJC Micro" 968 "Cox Powertrain" 969 "Blue Seas" 981 "Kobelt Manufacturing" 992 "Blue Ocean IOT" 997 "Xenta Systems" 999 "Signal K" 1004 "Ultraflex" 1008 "Lintest SmartBoat" 1011 "Soundmax" 1020 "Team Italia Marine (Onyx Marine Automation s.r.l)" 1021 "Entratech" 1022 "ITC" 1029 "The Marine Guardian" 1047 "Sonic" 1051 "ProNav" 1053 "Vetus Maxwell INC." 1056 "Lithium Pros" 1059 "Boatrax" 1062 "Marol Co ltd" 1065 "CALYPSO Instruments" 1066 "Spot Zero Water" 1069 "Lithionics Battery" 1070 "Quick-teck Electronics" 1075 "Uniden America" 1083 "Nauticoncept" 1084 "Shadow-Caster LED lighting" 1085 "Wet Sounds" 1088 "E-T-A Circuit Breakers" 1092 "Scheiber" 1100 "Smart Yachts International Limited" 1109 "Dockmate" 1114 "Bobs Machine" 1118 "L3Harris ASV" 1119 "Balmar" 1120 "Elettromedia" 1127 "Electromaax" 1140 "Across Oceans Systems" 1145 "Kiwi Yachting" 1150 "BSB Artificial Intelligence" 1151 "Orca Technologies" 1154 "TBS Electronics" 1158 "Technoton Electroics" 1160 "MG Energy Systems" 1169 "Sea Machine Robotics" 1171 "Vista Manufacturing" 1183 "Zipwake" 1186 "Sailmon" 1192 "Airmoniq Pro Kft" 1194 "Sierra Marine" 1200 "Xinuo Information Technology (Xiamen)" 1218 "Septentrio" 1233 "NKE Marine Electronics" 1238 "SuperTrack Aps" 1239 "Honda Electronics" 1245 "Raritan Engineering" 1249 "Integrated Power Solutions AG" 1260 "Interactive Technologies" 1283 "LTG-Tech" 1299 "Energy Solutions (UK)" 1300 "WATT Fuel Cell" 1302 "Pro Mainer" 1305 "Dragonfly Energy" 1306 "Koden Electronics" 1311 "Humphree" 1316 "Hinkley Yachts" 1317 "Global Marine Management GmbH (GMM)" 1320 "Triskel Marine" 1330 "Warwick Control Technologies" 1331 "Dolphin Charger" 1337 "Barnacle Systems" 1348 "Radian IoT" 1353 "Ocean LED Marine" 1359 "BluNav" 1361 "OVA (Nantong Saiyang Electronics Co., Ltd)" 1368 "RAD Propulsion" 1369 "Electric Yacht" 1372 "Elco Motor Yachts" 1384 "Tecnoseal Foundry S.r.l" 1385 "Pro Charging Systems" 1389 "EVEX" 1398 "Gobius Sensor Technology" 1403 "Arco Marine" 1408 "Lenco Marine" 1413 "Naocontrol" 1417 "Revatek" 1438 "Aeolionics" 1439 "PredictWind" 1440 "Egis Mobile Electric" 1445 "Starboard Yacht Group" 1446 "Roswell Marine" 1451 "ePropulsion (Guangdong ePropulsion Technology Ltd.)" 1452 "Micro-Air" 1453 "Vital Battery" 1458 "Ride Controller" 1460 "Tocaro Blue" 1461 "Vanquish Yachts" 1471 "FT Technologies" 1478 "Alps Alpine" 1481 "E-Force Marine" 1482 "CMC Marine" 1483 "Nanjing Sandemarine Information Technology" 1850 "Teleflex Marine (SeaStar Solutions)" 1851 "Raymarine" 1852 "Navionics" 1853 "Japan Radio" 1854 "Northstar Technologies" 1855 "Furuno" 1856 "Trimble" 1857 "Simrad" 1858 "Litton" 1859 "Kvasar" 1860 "MMP" 1861 "Vector Cantech" 1862 "Yamaha Marine" 1863 "Faria Instruments" ;
VAL_ 2583631104 Industry_Code 0 "Global" 1 "Highway" 2 "Agriculture" 3 "Construction" 4 "Marine Industry" 5 "Industrial" ;
VAL_ 2583631360 Manufacturer_Code 69 "ARKS Enterprises" 78 "FW Murphy/Enovation Controls" 80 "Twin Disc" 85 "Kohler Power Systems" 88 "Hemisphere GPS" 135 "Airmar" 137 "Maretron" 140 "Lowrance" 144 "Mercury Marine" 147 "Nautibus Electronic" 148 "Blue Water Data" 154 "Westerbeke" 157 "ISSPRO" 161 "Offshore Systems (UK)" 163 "Evinrude/BRP" 165 "CPAC Systems" 168 "Xantrex Technology" 169 "Marlin Technologies" 172 "Yanmar Marine" 174 "Volvo Penta" 176 "Carling Technologies Inc. (Moritz Aerospace)" 185 "Beede Instruments" 192 "Floscan Instrument" 193 "Nobeltec" 198 "Mystic Valley Communications" 199 "Actia" 201 "Disenos Y Technologia" 211 "Digital Switching Systems" 215 "Xintex/Atena" 224 "EMMI NETWORK" 228 "ZF" 229 "Garmin" 233 "Yacht Monitoring Solutions" 235 "Sailormade Marine Telemetry/Tetra Technology" 243 "Eride" 257 "Honda Motor" 272 "Groco" 273 "Actisense" 274 "Amphenol LTW Technology" 275 "Navico" 283 "Hamilton Jet" 285 "Sea Recovery" 286 "Coelmo SRL Italy" 295 "BEP Marine" 304 "Empir Bus" 305 "NovAtel" 306 "Sleipner Motor" 307 "MBW Technologies" 315 "ICOM" 328 "Qwerty" 329 "Dief" 341 "Boening Automationstechnologie" 345 "Korean Maritime University" 351 "Thrane and Thrane" 355 "Mastervolt" 356 "Fischer Panda Generators" 358 "Victron Energy" 370 "Rolls Royce Marine" 373 "Electronic Design" 374 "Northern Lights" 378 "Glendinning" 381 "B & G" 384 "Rose Point Navigation Systems" 385 "Johnson Outdoors Marine Electronics Inc Geonav" 394 "Capi 2" 396 "Beyond Measure" 400 "Livorsi Marine" 404 "ComNav" 409 "Chetco" 419 "Fusion Electronics" 421 "Standard Horizon" 422 "True Heading" 426 "Egersund Marine Electronics" 427 "em-trak Marine Electronics" 431 "Tohatsu Co, JP" 437 "Digital Yacht" 438 "Comar Systems Limited" 440 "Cummins" 443 "VDO (aka Continental-Corporation)" 451 "Parker Hannifin aka Village Marine Tech" 459 "Alltek Marine Electronics" 460 "SAN GIORGIO S.E.I.N" 466 "Veethree Electronics & Marine" 470 "SI-TEX Marine Electronics" 471 "Sea Cross Marine" 475 "GME aka Standard Communications" 476 "Humminbird Marine Electronics" 478 "Ocean Sat" 481 "Chetco Digital Instruments" 493 "Watcheye" 499 "Lcj Capteurs" 502 "Attwood Marine" 503 "Naviop S.R.L." 504 "Vesper Marine" 510 "Marinesoft" 513 "Simarine" 517 "NoLand Engineering" 518 "Transas USA" 529 "National Instruments Korea" 530 "National Marine Electronics Association" 532 "Onwa Marine" 540 "Webasto" 571 "Marinecraft (South Korea)" 573 "McMurdo Group aka Orolia" 578 "Advansea" 579 "KVH" 580 "San Jose Technology" 583 "Yacht Control" 586 "Suzuki Motor" 591 "US Coast Guard" 595 "Ship Module aka Customware" 600 "Aquatic AV" 605 "Aventics" 606 "Intellian" 612 "SamwonIT" 614 "Arlt Tecnologies" 637 "Bavaria Yachts" 641 "Diverse Yacht Services" 644 "Wema U.S.A dba KUS" 658 "Shenzhen Jiuzhou Himunication" 688 "Rockford" 699 "Harman International" 704 "JL Audio" 708 "Lars Thrane" 715 "Autonnic" 717 "Yacht Devices" 734 "REAP Systems" 735 "AEM Performance Electronics" 739 "LxNav" 741 "Littelfuse, Inc (formerly Carling Technologies)" 743 "DaeMyung" 744 "Woosung" 748 "ISOTTA IFRA srl" 773 "Clarion US" 776 "HMI Systems" 777 "Ocean Signal" 778 "Seakeeper" 781 "Poly Planar" 785 "Fischer Panda DE" 795 "Broyda Industries" 796 "Canadian Automotive" 797 "Tides Marine" 798 "Lumishore" 799 "Still Water Designs and Audio" 802 "BJ Technologies (Beneteau)" 803 "Gill Sensors" 811 "Blue Water Desalination" 815 "FLIR" 824 "Undheim Systems" 826 "Lewmar" 838 "TeamSurv" 844 "Fell Marine" 847 "Oceanvolt" 862 "Prospec" 868 "Data Panel" 890 "L3 Technologies" 894 "Rhodan Marine Systems" 896 "Nexfour Solutions" 905 "ASA Electronics" 909 "Marines Co (South Korea)" 911 "Nautic-on" 917 "Sentinel" 929 "JL Marine Systems" 930 "Ecotronix" 944 "Zontisa Marine" 951 "EXOR International" 962 "Timbolier Industries" 963 "TJC Micro" 968 "Cox Powertrain" 969 "Blue Seas" 981 "Kobelt Manufacturing" 992 "Blue Ocean IOT" 997 "Xenta Systems" 999 "Signal K" 1004 "Ultraflex" 1008 "Lintest SmartBoat" 1011 "Soundmax" 1020 "Team Italia Marine (Onyx Marine Automation s.r.l)" 1021 "Entratech" 1022 "ITC" 1029 "The Marine Guardian" 1047 "Sonic" 1051 "ProNav" 1053 "Vetus Maxwell INC." 1056 "Lithium Pros" 1059 "Boatrax" 1062 "Marol Co ltd" 1065 "CALYPSO Instruments" 1066 "Spot Zero Water" 1069 "Lithionics Battery" 1070 "Quick-teck Electronics" 1075 "Uniden America" 1083 "Nauticoncept" 1084 "Shadow-Caster LED lighting" 1085 "Wet Sounds" 1088 "E-T-A Circuit Breakers" 1092 "Scheiber" 1100 "Smart Yachts International Limited" 1109 "Dockmate" 1114 "Bobs Machine" 1118 "L3Harris ASV" 1119 "Balmar" 1120 "Elettromedia" 1127 "Electromaax" 1140 "Across Oceans Systems" 1145 "Kiwi Yachting" 1150 "BSB Artificial Intelligence" 1151 "Orca Technologies" 1154 "TBS Electronics" 1158 "Technoton Electroics" 1160 "MG Energy Systems" 1169 "Sea Machine Robotics" 1171 "Vista Manufacturing" 1183 "Zipwake" 1186 "Sailmon" 1192 "Airmoniq Pro Kft" 1194 "Sierra Marine" 1200 "Xinuo Information Technology (Xiamen)" 1218 "Septentrio" 1233 "NKE Marine Electronics" 1238 "SuperTrack Aps" 1239 "Honda Electronics" 1245 "Raritan Engineering" 1249 "Integrated Power Solutions AG" 1260 "Interactive Technologies" 1283 "LTG-Tech" 1299 "Energy Solutions (UK)" 1300 "WATT Fuel Cell" 1302 "Pro Mainer" 1305 "Dragonfly Energy" 1306 "Koden Electronics" 1311 "Humphree" 1316 "Hinkley Yachts" 1317 "Global Marine Management GmbH (GMM)" 1320 "Triskel Marine" 1330 "Warwick Control Technologies" 1331 "Dolphin Charger" 1337 "Barnacle Systems" 1348 "Radian IoT" 1353 "Ocean LED Marine" 1359 "BluNav" 1361 "OVA (Nantong Saiyang Electronics Co., Ltd)" 1368 "RAD Propulsion" 1369 "Electric Yacht" 1372 "Elco Motor Yachts" 1384 "Tecnoseal Foundry S.r.l" 1385 "Pro Charging Systems" 1389 "EVEX" 1398 "Gobius Sensor Technology" 1403 "Arco Marine" 1408 "Lenco Marine" 1413 "Naocontrol" 1417 "Revatek" 1438 "Aeolionics" 1439 "PredictWind" 1440 "Egis Mobile Electric" 1445 "Starboard Yacht Group" 1446 "Roswell Marine" 1451 "ePropulsion (Guangdong ePropulsion Technology Ltd.)" 1452 "Micro-Air" 1453 "Vital Battery" 1458 "Ride Controller" 1460 "Tocaro Blue" 1461 "Vanquish Yachts" 1471 "FT Technologies" 1478 "Alps Alpine" 1481 "E-Force Marine" 1482 "CMC Marine" 1483 "Nanjing Sandemarine Information Technology" 1850 "Teleflex Marine (SeaStar Solutions)" 1851 "Raymarine" 1852 "Navionics" 1853 "Japan Radio" 1854 "Northstar Technologies" 1855 "Furuno" 1856 "Trimble" 1857 "Simrad" 1858 "Litton" 1859 "Kvasar" 1860 "MMP" 1861 "Vector Cantech" 1862 "Yamaha Marine" 1863 "Faria Instruments" ;
VAL_ 2583631360 Industry_Code 0 "Global" 1 "Highway" 2 "Agriculture" 3 "Construction" 4 "Marine Industry" 5 "Industrial" ;
VAL_ 2583631360 Manufacturer_Code 69 "ARKS Enterprises" 78 "FW Murphy/Enovation Controls" 80 "Twin Disc" 85 "Kohler Power Systems" 88 "Hemisphere GPS" 135 "Airmar" 137 "Maretron" 140 "Lowrance" 144 "Mercury Marine" 147 "Nautibus Electronic" 148 "Blue Water Data" 154 "Westerbeke" 157 "ISSPRO" 161 "Offshore Systems (UK)" 163 "Evinrude/BRP" 165 "CPAC Systems" 168 "Xantrex Technology" 169 "Marlin Technologies" 172 "Yanmar Marine" 174 "Volvo Penta" 176 "Carling Technologies Inc. (Moritz Aerospace)" 185 "Beede Instruments" 192 "Floscan Instrument" 193 "Nobeltec" 198 "Mystic Valley Communications" 199 "Actia" 201 "Disenos Y Technologia" 211 "Digital Switching Systems" 215 "Xintex/Atena" 224 "EMMI NETWORK" 228 "ZF" 229 "Garmin" 233 "Yacht Monitoring Solutions" 235 "Sailormade Marine Telemetry/Tetra Technology" 243 "Eride" 257 "Honda Motor" 272 "Groco" 273 "Actisense" 274 "Amphenol LTW Technology" 275 "Navico" 283 "Hamilton Jet" 285 "Sea Recovery" 286 "Coelmo SRL Italy" 295 "BEP Marine" 304 "Empir Bus" 305 "NovAtel" 306 "Sleipner Motor" 307 "MBW Technologies" 315 "ICOM" 328 "Qwerty" 329 "Dief" 341 "Boening Automationstechnologie" 345 "Korean Maritime University" 351 "Thrane and Thrane" 355 "Mastervolt" 356 "Fischer Panda Generators" 358 "Victron Energy" 370 "Rolls Royce Marine" 373 "Electronic Design" 374 "Northern Lights" 378 "Glendinning" 381 "B & G" 384 "Rose Point Navigation Systems" 385 "Johnson Outdoors Marine Electronics Inc Geonav" 394 "Capi 2" 396 "Beyond Measure" 400 "Livorsi Marine" 404 "ComNav" 409 "Chetco" 419 "Fusion Electronics" 421 "Standard Horizon" 422 "True Heading" 426 "Egersund Marine Electronics" 427 "em-trak Marine Electronics" 431 "Tohatsu Co, JP" 437 "Digital Yacht" 438 "Comar Systems Limited" 440 "Cummins" 443 "VDO (aka Continental-Corporation)" 451 "Parker Hannifin aka Village Marine Tech" 459 "Alltek Marine Electronics" 460 "SAN GIORGIO S.E.I.N" 466 "Veethree Electronics & Marine" 470 "SI-TEX Marine Electronics" 471 "Sea Cross Marine" 475 "GME aka Standard Communications" 476 "Humminbird Marine Electronics" 478 "Ocean Sat" 481 "Chetco Digital Instruments" 493 "Watcheye" 499 "Lcj Capteurs" 502 "Attwood Marine" 503 "Naviop S.R.L." 504 "Vesper Marine" 510 "Marinesoft" 513 "Simarine" 517 "NoLand Engineering" 518 "Transas USA" 529 "National Instruments Korea" 530 "National Marine Electronics Association" 532 "Onwa Marine" 540 "Webasto" 571 "Marinecraft (South Korea)" 573 "McMurdo Group aka Orolia" 578 "Advansea" 579 "KVH" 580 "San Jose Technology" 583 "Yacht Control" 586 "Suzuki Motor" 591 "US Coast Guard" 595 "Ship Module aka Customware" 600 "Aquatic AV" 605 "Aventics" 606 "Intellian" 612 "SamwonIT" 614 "Arlt Tecnologies" 637 "Bavaria Yachts" 641 "Diverse Yacht Services" 644 "Wema U.S.A dba KUS" 658 "Shenzhen Jiuzhou Himunication" 688 "Rockford" 699 "Harman International" 704 "JL Audio" 708 "Lars Thrane" 715 "Autonnic" 717 "Yacht Devices" 734 "REAP Systems" 735 "AEM Performance Electronics" 739 "LxNav" 741 "Littelfuse, Inc (formerly Carling Technologies)" 743 "DaeMyung" 744 "Woosung" 748 "ISOTTA IFRA srl" 773 "Clarion US" 776 "HMI Systems" 777 "Ocean Signal" 778 "Seakeeper" 781 "Poly Planar" 785 "Fischer Panda DE" 795 "Broyda Industries" 796 "Canadian Automotive" 797 "Tides Marine" 798 "Lumishore" 799 "Still Water Designs and Audio" 802 "BJ Technologies (Beneteau)" 803 "Gill Sensors" 811 "Blue Water Desalination" 815 "FLIR" 824 "Undheim Systems" 826 "Lewmar" 838 "TeamSurv" 844 "Fell Marine" 847 "Oceanvolt" 862 "Prospec" 868 "Data Panel" 890 "L3 Technologies" 894 "Rhodan Marine Systems" 896 "Nexfour Solutions" 905 "ASA Electronics" 909 "Marines Co (South Korea)" 911 "Nautic-on" 917 "Sentinel" 929 "JL Marine Systems" 930 "Ecotronix" 944 "Zontisa Marine" 951 "EXOR International" 962 "Timbolier Industries" 963 "TJC Micro" 968 "Cox Powertrain" 969 "Blue Seas" 981 "Kobelt Manufacturing" 992 "Blue Ocean IOT" 997 "Xenta Systems" 999 "Signal K" 1004 "Ultraflex" 1008 "Lintest SmartBoat" 1011 "Soundmax" 1020 "Team Italia Marine (Onyx Marine Automation s.r.l)" 1021 "Entratech" 1022 "ITC" 1029 "The Marine Guardian" 1047 "Sonic" 1051 "ProNav" 1053 "Vetus Maxwell INC." 1056 "Lithium Pros" 1059 "Boatrax" 1062 "Marol Co ltd" 1065 "CALYPSO Instruments" 1066 "Spot Zero Water" 1069 "Lithionics Battery" 1070 "Quick-teck Electronics" 1075 "Uniden America" 1083 "Nauticoncept" 1084 "Shadow-Caster LED lighting" 1085 "Wet Sounds" 1088 "E-T-A Circuit Breakers" 1092 "Scheiber" 1100 "Smart Yachts International Limited" 1109 "Dockmate" 1114 "Bobs Machine" 1118 "L3Harris ASV" 1119 "Balmar" 1120 "Elettromedia" 1127 "Electromaax" 1140 "Across Oceans Systems" 1145 "Kiwi Yachting" 1150 "BSB Artificial Intelligence" 1151 "Orca Technologies" 1154 "TBS Electronics" 1158 "Technoton Electroics" 1160 "MG Energy Systems" 1169 "Sea Machine Robotics" 1171 "Vista Manufacturing" 1183 "Zipwake" 1186 "Sailmon" 1192 "Airmoniq Pro Kft" 1194 "Sierra Marine" 1200 "Xinuo Information Technology (Xiamen)" 1218 "Septentrio" 1233 "NKE Marine Electronics" 1238 "SuperTrack Aps" 1239 "Honda Electronics" 1245 "Raritan Engineering" 1249 "Integrated Power Solutions AG" 1260 "Interactive Technologies" 1283 "LTG-Tech" 1299 "Energy Solutions (UK)" 1300 "WATT Fuel Cell" 1302 "Pro Mainer" 1305 "Dragonfly Energy" 1306 "Koden Electronics" 1311 "Humphree" 1316 "Hinkley Yachts" 1317 "Global Marine Management GmbH (GMM)" 1320 "Triskel Marine" 1330 "Warwick Control Technologies" 1331 "Dolphin Charger" 1337 "Barnacle Systems" 1348 "Radian IoT" 1353 "Ocean LED Marine" 1359 "BluNav" 1361 "OVA (Nantong Saiyang Electronics Co., Ltd)" 1368 "RAD Propulsion" 1369 "Electric Yacht" 1372 "Elco Motor Yachts" 1384 "Tecnoseal Foundry S.r.l" 1385 "Pro Charging Systems" 1389 "EVEX" 1398 "Gobius Sensor Technology" 1403 "Arco Marine" 1408 "Lenco Marine" 1413 "Naocontrol" 1417 "Revatek" 1438 "Aeolionics" 1439 "PredictWind" 1440 "Egis Mobile Electric" 1445 "Starboard Yacht Group" 1446 "Roswell Marine" 1451 "ePropulsion (Guangdong ePropulsion Technology Ltd.)" 1452 "Micro-Air" 1453 "Vital Battery" 1458 "Ride Controller" 1460 "Tocaro Blue" 1461 "Vanquish Yachts" 1471 "FT Technologies" 1478 "Alps Alpine" 1481 "E-Force Marine" 1482 "CMC Marine" 1483 "Nanjing Sandemarine Information Technology" 1850 "Teleflex Marine (SeaStar Solutions)" 1851 "Raymarine" 1852 "Navionics" 1853 "Japan Radio" 1854 "Northstar Technologies" 1855 "Furuno" 1856 "Trimble" 1857 "Simrad" 1858 "Litton" 1859 "Kvasar" 1860 "MMP" 1861 "Vector Cantech" 1862 "Yamaha Marine" 1863 "Faria Instruments" ;
VAL_ 2583631360 Industry_Code 0 "Global" 1 "Highway" 2 "Agriculture" 3 "Construction" 4 "Marine Industry" 5 "Industrial" ;
VAL_ 2583631360 Manufacturer_Code 69 "ARKS Enterprises" 78 "FW Murphy/Enovation Controls" 80 "Twin Disc" 85 "Kohler Power Systems" 88 "Hemisphere GPS" 135 "Airmar" 137 "Maretron" 140 "Lowrance" 144 "Mercury Marine" 147 "Nautibus Electronic" 148 "Blue Water Data" 154 "Westerbeke" 157 "ISSPRO" 161 "Offshore Systems (UK)" 163 "Evinrude/BRP" 165 "CPAC Systems" 168 "Xantrex Technology" 169 "Marlin Technologies" 172 "Yanmar Marine" 174 "Volvo Penta" 176 "Carling Technologies Inc. (Moritz Aerospace)" 185 "Beede Instruments" 192 "Floscan Instrument" 193 "Nobeltec" 198 "Mystic Valley Communications" 199 "Actia" 201 "Disenos Y Technologia" 211 "Digital Switching Systems" 215 "Xintex/Atena" 224 "EMMI NETWORK" 228 "ZF" 229 "Garmin" 233 "Yacht Monitoring Solutions" 235 "Sailormade Marine Telemetry/Tetra Technology" 243 "Eride" 257 "Honda Motor" 272 "Groco" 273 "Actisense" 274 "Amphenol LTW Technology" 275 "Navico" 283 "Hamilton Jet" 285 "Sea Recovery" 286 "Coelmo SRL Italy" 295 "BEP Marine" 304 "Empir Bus" 305 "NovAtel" 306 "Sleipner Motor" 307 "MBW Technologies" 315 "ICOM" 328 "Qwerty" 329 "Dief" 341 "Boening Automationstechnologie" 345 "Korean Maritime University" 351 "Thrane and Thrane" 355 "Mastervolt" 356 "Fischer Panda Generators" 358 "Victron Energy" 370 "Rolls Royce Marine" 373 "Electronic Design" 374 "Northern Lights" 378 "Glendinning" 381 "B & G" 384 "Rose Point Navigation Systems" 385 "Johnson Outdoors Marine Electronics Inc Geonav" 394 "Capi 2" 396 "Beyond Measure" 400 "Livorsi Marine" 404 "ComNav" 409 "Chetco" 419 "Fusion Electronics" 421 "Standard Horizon" 422 "True Heading" 426 "Egersund Marine Electronics" 427 "em-trak Marine Electronics" 431 "Tohatsu Co, JP" 437 "Digital Yacht" 438 "Comar Systems Limited" 440 "Cummins" 443 "VDO (aka Continental-Corporation)" 451 "Parker Hannifin aka Village Marine Tech" 459 "Alltek Marine Electronics" 460 "SAN GIORGIO S.E.I.N" 466 "Veethree Electronics & Marine" 470 "SI-TEX Marine Electronics" 471 "Sea Cross Marine" 475 "GME aka Standard Communications" 476 "Humminbird Marine Electronics" 478 "Ocean Sat" 481 "Chetco Digital Instruments" 493 "Watcheye" 499 "Lcj Capteurs" 502 "Attwood Marine" 503 "Naviop S.R.L." 504 "Vesper Marine" 510 "Marinesoft" 513 "Simarine" 517 "NoLand Engineering" 518 "Transas USA" 529 "National Instruments Korea" 530 "National Marine Electronics Association" 532 "Onwa Marine" 540 "Webasto" 571 "Marinecraft (South Korea)" 573 "McMurdo Group aka Orolia" 578 "Advansea" 579 "KVH" 580 "San Jose Technology" 583 "Yacht Control" 586 "Suzuki Motor" 591 "US Coast Guard" 595 "Ship Module aka Customware" 600 "Aquatic AV" 605 "Aventics" 606 "Intellian" 612 "SamwonIT" 614 "Arlt Tecnologies" 637 "Bavaria Yachts" 641 "Diverse Yacht Services" 644 "Wema U.S.A dba KUS" 658 "Shenzhen Jiuzhou Himunication" 688 "Rockford" 699 "Harman International" 704 "JL Audio" 708 "Lars Thrane" 715 "Autonnic" 717 "Yacht Devices" 734 "REAP Systems" 735 "AEM Performance Electronics" 739 "LxNav" 741 "Littelfuse, Inc (formerly Carling Technologies)" 743 "DaeMyung" 744 "Woosung" 748 "ISOTTA IFRA srl" 773 "Clarion US" 776 "HMI Systems" 777 "Ocean Signal" 778 "Seakeeper" 781 "Poly Planar" 785 "Fischer Panda DE" 795 "Broyda Industries" 796 "Canadian Automotive" 797 "Tides Marine" 798 "Lumishore" 799 "Still Water Designs and Audio" 802 "BJ Technologies (Beneteau)" 803 "Gill Sensors" 811 "Blue Water Desalination" 815 "FLIR" 824 "Undheim Systems" 826 "Lewmar" 838 "TeamSurv" 844 "Fell Marine" 847 "Oceanvolt" 862 "Prospec" 868 "Data Panel" 890 "L3 Technologies" 894 "Rhodan Marine Systems" 896 "Nexfour Solutions" 905 "ASA Electronics" 909 "Marines Co (South Korea)" 911 "Nautic-on" 917 "Sentinel" 929 "JL Marine Systems" 930 "Ecotronix" 944 "Zontisa Marine" 951 "EXOR International" 962 "Timbolier Industries" 963 "TJC Micro" 968 "Cox Powertrain" 969 "Blue Seas" 981 "Kobelt Manufacturing" 992 "Blue Ocean IOT" 997 "Xenta Systems" 999 "Signal K" 1004 "Ultraflex" 1008 "Lintest SmartBoat" 1011 "Soundmax" 1020 "Team Italia Marine (Onyx Marine Automation s.r.l)" 1021 "Entratech" 1022 "ITC" 1029 "The Marine Guardian" 1047 "Sonic" 1051 "ProNav" 1053 "Vetus Maxwell INC." 1056 "Lithium Pros" 1059 "Boatrax" 1062 "Marol Co ltd" 1065 "CALYPSO Instruments" 1066 "Spot Zero Water" 1069 "Lithionics Battery" 1070 "Quick-teck Electronics" 1075 "Uniden America" 1083 "Nauticoncept" 1084 "Shadow-Caster LED lighting" 1085 "Wet Sounds" 1088 "E-T-A Circuit Breakers" 1092 "Scheiber" 1100 "Smart Yachts International Limited" 1109 "Dockmate" 1114 "Bobs Machine" 1118 "L3Harris ASV" 1119 "Balmar" 1120 "Elettromedia" 1127 "Electromaax" 1140 "Across Oceans Systems" 1145 "Kiwi Yachting" 1150 "BSB Artificial Intelligence" 1151 "Orca Technologies" 1154 "TBS Electronics" 1158 "Technoton Electroics" 1160 "MG Energy Systems" 1169 "Sea Machine Robotics" 1171 "Vista Manufacturing" 1183 "Zipwake" 1186 "Sailmon" 1192 "Airmoniq Pro Kft" 1194 "Sierra Marine" 1200 "Xinuo Information Technology (Xiamen)" 1218 "Septentrio" 1233 "NKE Marine Electronics" 1238 "SuperTrack Aps" 1239 "Honda Electronics" 1245 "Raritan Engineering" 1249 "Integrated Power Solutions AG" 1260 "Interactive Technologies" 1283 "LTG-Tech" 1299 "Energy Solutions (UK)" 1300 "WATT Fuel Cell" 1302 "Pro Mainer" 1305 "Dragonfly Energy" 1306 "Koden Electronics" 1311 "Humphree" 1316 "Hinkley Yachts" 1317 "Global Marine Management GmbH (GMM)" 1320 "Triskel Marine" 1330 "Warwick Control Technologies" 1331 "Dolphin Charger" 1337 "Barnacle Systems" 1348 "Radian IoT" 1353 "Ocean LED Marine" 1359 "BluNav" 1361 "OVA (Nantong Saiyang Electronics Co., Ltd)" 1368 "RAD Propulsion" 1369 "Electric Yacht" 1372 "Elco Motor Yachts" 1384 "Tecnoseal Foundry S.r.l" 1385 "Pro Charging Systems" 1389 "EVEX" 1398 "Gobius Sensor Technology" 1403 "Arco Marine" 1408 "Lenco Marine" 1413 "Naocontrol" 1417 "Revatek" 1438 "Aeolionics" 1439 "PredictWind" 1440 "Egis Mobile Electric" 1445 "Starboard Yacht Group" 1446 "Roswell Marine" 1451 "ePropulsion (Guangdong ePropulsion Technology Ltd.)" 1452 "Micro-Air" 1453 "Vital Battery" 1458 "Ride Controller" 1460 "Tocaro Blue" 1461 "Vanquish Yachts" 1471 "FT Technologies" 1478 "Alps Alpine" 1481 "E-Force Marine" 1482 "CMC Marine" 1483 "Nanjing Sandemarine Information Technology" 1850 "Teleflex Marine (SeaStar Solutions)" 1851 "Raymarine" 1852 "Navionics" 1853 "Japan Radio" 1854 "Northstar Technologies" 1855 "Furuno" 1856 "Trimble" 1857 "Simrad" 1858 "Litton" 1859 "Kvasar" 1860 "MMP" 1861 "Vector Cantech" 1862 "Yamaha Marine" 1863 "Faria Instruments" ;
VAL_ 2583631360 Industry_Code 0 "Global" 1 "Highway" 2 "Agriculture" 3 "Construction" 4 "Marine Industry" 5 "Industrial" ;
VAL_ 2583631616 Manufacturer_Code 69 "ARKS Enterprises" 78 "FW Murphy/Enovation Controls" 80 "Twin Disc" 85 "Kohler Power Systems" 88 "Hemisphere GPS" 135 "Airmar" 137 "Maretron" 140 "Lowrance" 144 "Mercury Marine" 147 "Nautibus Electronic" 148 "Blue Water Data" 154 "Westerbeke" 157 "ISSPRO" 161 "Offshore Systems (UK)" 163 "Evinrude/BRP" 165 "CPAC Systems" 168 "Xantrex Technology" 169 "Marlin Technologies" 172 "Yanmar Marine" 174 "Volvo Penta" 176 "Carling Technologies Inc. (Moritz Aerospace)" 185 "Beede Instruments" 192 "Floscan Instrument" 193 "Nobeltec" 198 "Mystic Valley Communications" 199 "Actia" 201 "Disenos Y Technologia" 211 "Digital Switching Systems" 215 "Xintex/Atena" 224 "EMMI NETWORK" 228 "ZF" 229 "Garmin" 233 "Yacht Monitoring Solutions" 235 "Sailormade Marine Telemetry/Tetra Technology" 243 "Eride" 257 "Honda Motor" 272 "Groco" 273 "Actisense" 274 "Amphenol LTW Technology" 275 "Navico" 283 "Hamilton Jet" 285 "Sea Recovery" 286 "Coelmo SRL Italy" 295 "BEP Marine" 304 "Empir Bus" 305 "NovAtel" 306 "Sleipner Motor" 307 "MBW Technologies" 315 "ICOM" 328 "Qwerty" 329 "Dief" 341 "Boening Automationstechnologie" 345 "Korean Maritime University" 351 "Thrane and Thrane" 355 "Mastervolt" 356 "Fischer Panda Generators" 358 "Victron Energy" 370 "Rolls Royce Marine" 373 "Electronic Design" 374 "Northern Lights" 378 "Glendinning" 381 "B & G" 384 "Rose Point Navigation Systems" 385 "Johnson Outdoors Marine Electronics Inc Geonav" 394 "Capi 2" 396 "Beyond Measure" 400 "Livorsi Marine" 404 "ComNav" 409 "Chetco" 419 "Fusion Electronics" 421 "Standard Horizon" 422 "True Heading" 426 "Egersund Marine Electronics" 427 "em-trak Marine Electronics" 431 "Tohatsu Co, JP" 437 "Digital Yacht" 438 "Comar Systems Limited" 440 "Cummins" 443 "VDO (aka Continental-Corporation)" 451 "Parker Hannifin aka Village Marine Tech" 459 "Alltek Marine Electronics" 460 "SAN GIORGIO S.E.I.N" 466 "Veethree Electronics & Marine" 470 "SI-TEX Marine Electronics" 471 "Sea Cross Marine" 475 "GME aka Standard Communications" 476 "Humminbird Marine Electronics" 478 "Ocean Sat" 481 "Chetco Digital Instruments" 493 "Watcheye" 499 "Lcj Capteurs" 502 "Attwood Marine" 503 "Naviop S.R.L." 504 "Vesper Marine" 510 "Marinesoft" 513 "Simarine" 517 "NoLand Engineering" 518 "Transas USA" 529 "National Instruments Korea" 530 "National Marine Electronics Association" 532 "Onwa Marine" 540 "Webasto" 571 "Marinecraft (South Korea)" 573 "McMurdo Group aka Orolia" 578 "Advansea" 579 "KVH" 580 "San Jose Technology" 583 "Yacht Control" 586 "Suzuki Motor" 591 "US Coast Guard" 595 "Ship Module aka Customware" 600 "Aquatic AV" 605 "Aventics" 606 "Intellian" 612 "SamwonIT" 614 "Arlt Tecnologies" 637 "Bavaria Yachts" 641 "Diverse Yacht Services" 644 "Wema U.S.A dba KUS" 658 "Shenzhen Jiuzhou Himunication" 688 "Rockford" 699 "Harman International" 704 "JL Audio" 708 "Lars Thrane" 715 "Autonnic" 717 "Yacht Devices" 734 "REAP Systems" 735 "AEM Performance Electronics" 739 "LxNav" 741 "Littelfuse, Inc (formerly Carling Technologies)" 743 "DaeMyung" 744 "Woosung" 748 "ISOTTA IFRA srl" 773 "Clarion US" 776 "HMI Systems" 777 "Ocean Signal" 778 "Seakeeper" 781 "Poly Planar" 785 "Fischer Panda DE" 795 "Broyda Industries" 796 "Canadian Automotive" 797 "Tides Marine" 798 "Lumishore" 799 "Still Water Designs and Audio" 802 "BJ Technologies (Beneteau)" 803 "Gill Sensors" 811 "Blue Water Desalination" 815 "FLIR" 824 "Undheim Systems" 826 "Lewmar" 838 "TeamSurv" 844 "Fell Marine" 847 "Oceanvolt" 862 "Prospec" 868 "Data Panel" 890 "L3 Technologies" 894 "Rhodan Marine Systems" 896 "Nexfour Solutions" 905 "ASA Electronics" 909 "Marines Co (South Korea)" 911 "Nautic-on" 917 "Sentinel" 929 "JL Marine Systems" 930 "Ecotronix" 944 "Zontisa Marine" 951 "EXOR International" 962 "Timbolier Industries" 963 "TJC Micro" 968 "Cox Powertrain" 969 "Blue Seas" 981 "Kobelt Manufacturing" 992 "Blue Ocean IOT" 997 "Xenta Systems" 999 "Signal K" 1004 "Ultraflex" 1008 "Lintest SmartBoat" 1011 "Soundmax" 1020 "Team Italia Marine (Onyx Marine Automation s.r.l)" 1021 "Entratech" 1022 "ITC" 1029 "The Marine Guardian" 1047 "Sonic" 1051 "ProNav" 1053 "Vetus Maxwell INC." 1056 "Lithium Pros" 1059 "Boatrax" 1062 "Marol Co ltd" 1065 "CALYPSO Instruments" 1066 "Spot Zero Water" 1069 "Lithionics Battery" 1070 "Quick-teck Electronics" 1075 "Uniden America" 1083 "Nauticoncept" 1084 "Shadow-Caster LED lighting" 1085 "Wet Sounds" 1088 "E-T-A Circuit Breakers" 1092 "Scheiber" 1100 "Smart Yachts International Limited" 1109 "Dockmate" 1114 "Bobs Machine" 1118 "L3Harris ASV" 1119 "Balmar" 1120 "Elettromedia" 1127 "Electromaax" 1140 "Across Oceans Systems" 1145 "Kiwi Yachting" 1150 "BSB Artificial Intelligence" 1151 "Orca Technologies" 1154 "TBS Electronics" 1158 "Technoton Electroics" 1160 "MG Energy Systems" 1169 "Sea Machine Robotics" 1171 "Vista Manufacturing" 1183 "Zipwake" 1186 "Sailmon" 1192 "Airmoniq Pro Kft" 1194 "Sierra Marine" 1200 "Xinuo Information Technology (Xiamen)" 1218 "Septentrio" 1233 "NKE Marine Electronics" 1238 "SuperTrack Aps" 1239 "Honda Electronics" 1245 "Raritan Engineering" 1249 "Integrated Power Solutions AG" 1260 "Interactive Technologies" 1283 "LTG-Tech" 1299 "Energy Solutions (UK)" 1300 "WATT Fuel Cell" 1302 "Pro Mainer" 1305 "Dragonfly Energy" 1306 "Koden Electronics" 1311 "Humphree" 1316 "Hinkley Yachts" 1317 "Global Marine Management GmbH (GMM)" 1320 "Triskel Marine" 1330 "Warwick Control Technologies" 1331 "Dolphin Charger" 1337 "Barnacle Systems" 1348 "Radian IoT" 1353 "Ocean LED Marine" 1359 "BluNav" 1361 "OVA (Nantong Saiyang Electronics Co., Ltd)" 1368 "RAD Propulsion" 1369 "Electric Yacht" 1372 "Elco Motor Yachts" 1384 "Tecnoseal Foundry S.r.l" 1385 "Pro Charging Systems" 1389 "EVEX" 1398 "Gobius Sensor Technology" 1403 "Arco Marine" 1408 "Lenco Marine" 1413 "Naocontrol" 1417 "Revatek" 1438 "Aeolionics" 1439 "PredictWind" 1440 "Egis Mobile Electric" 1445 "Starboard Yacht Group" 1446 "Roswell Marine" 1451 "ePropulsion (Guangdong ePropulsion Technology Ltd.)" 1452 "Micro-Air" 1453 "Vital Battery" 1458 "Ride Controller" 1460 "Tocaro Blue" 1461 "Vanquish Yachts" 1471 "FT Technologies" 1478 "Alps Alpine" 1481 "E-Force Marine" 1482 "CMC Marine" 1483 "Nanjing Sandemarine Information Technology" 1850 "Teleflex Marine (SeaStar Solutions)" 1851 "Raymarine" 1852 "Navionics" 1853 "Japan Radio" 1854 "Northstar Technologies" 1855 "Furuno" 1856 "Trimble" 1857 "Simrad" 1858 "Litton" 1859 "Kvasar" 1860 "MMP" 1861 "Vector Cantech" 1862 "Yamaha Marine" 1863 "Faria Instruments" ;
VAL_ 2583631616 Industry_Code 0 "Global" 1 "Highway" 2 "Agriculture" 3 "Construction" 4 "Marine Industry" 5 "Industrial" ;
VAL_ 2583631872 Manufacturer_Code 69 "ARKS Enterprises" 78 "FW Murphy/Enovation Controls" 80 "Twin Disc" 85 "Kohler Power Systems" 88 "Hemisphere GPS" 135 "Airmar" 137 "Maretron" 140 "Lowrance" 144 "Mercury Marine" 147 "Nautibus Electronic" 148 "Blue Water Data" 154 "Westerbeke" 157 "ISSPRO" 161 "Offshore Systems (UK)" 163 "Evinrude/BRP" 165 "CPAC Systems" 168 "Xantrex Technology" 169 "Marlin Technologies" 172 "Yanmar Marine" 174 "Volvo Penta" 176 "Carling Technologies Inc. (Moritz Aerospace)" 185 "Beede Instruments" 192 "Floscan Instrument" 193 "Nobeltec" 198 "Mystic Valley Communications" 199 "Actia" 201 "Disenos Y Technologia" 211 "Digital Switching Systems" 215 "Xintex/Atena" 224 "EMMI NETWORK" 228 "ZF" 229 "Garmin" 233 "Yacht Monitoring Solutions" 235 "Sailormade Marine Telemetry/Tetra Technology" 243 "Eride" 257 "Honda Motor" 272 "Groco" 273 "Actisense" 274 "Amphenol LTW Technology" 275 "Navico" 283 "Hamilton Jet" 285 "Sea Recovery" 286 "Coelmo SRL Italy" 295 "BEP Marine" 304 "Empir Bus" 305 "NovAtel" 306 "Sleipner Motor" 307 "MBW Technologies" 315 "ICOM" 328 "Qwerty" 329 "Dief" 341 "Boening Automationstechnologie" 345 "Korean Maritime University" 351 "Thrane and Thrane" 355 "Mastervolt" 356 "Fischer Panda Generators" 358 "Victron Energy" 370 "Rolls Royce Marine" 373 "Electronic Design" 374 "Northern Lights" 378 "Glendinning" 381 "B & G" 384 "Rose Point Navigation Systems" 385 "Johnson Outdoors Marine Electronics Inc Geonav" 394 "Capi 2" 396 "Beyond Measure" 400 "Livorsi Marine" 404 "ComNav" 409 "Chetco" 419 "Fusion Electronics" 421 "Standard Horizon" 422 "True Heading" 426 "Egersund Marine Electronics" 427 "em-trak Marine Electronics" 431 "Tohatsu Co, JP" 437 "Digital Yacht" 438 "Comar Systems Limited" 440 "Cummins" 443 "VDO (aka Continental-Corporation)" 451 "Parker Hannifin aka Village Marine Tech" 459 "Alltek Marine Electronics" 460 "SAN GIORGIO S.E.I.N" 466 "Veethree Electronics & Marine" 470 "SI-TEX Marine Electronics" 471 "Sea Cross Marine" 475 "GME aka Standard Communications" 476 "Humminbird Marine Electronics" 478 "Ocean Sat" 481 "Chetco Digital Instruments" 493 "Watcheye" 499 "Lcj Capteurs" 502 "Attwood Marine" 503 "Naviop S.R.L." 504 "Vesper Marine" 510 "Marinesoft" 513 "Simarine" 517 "NoLand Engineering" 518 "Transas USA" 529 "National Instruments Korea" 530 "National Marine Electronics Association" 532 "Onwa Marine" 540 "Webasto" 571 "Marinecraft (South Korea)" 573 "McMurdo Group aka Orolia" 578 "Advansea" 579 "KVH" 580 "San Jose Technology" 583 "Yacht Control" 586 "Suzuki Motor" 591 "US Coast Guard" 595 "Ship Module aka Customware" 600 "Aquatic AV" 605 "Aventics" 606 "Intellian" 612 "SamwonIT" 614 "Arlt Tecnologies" 637 "Bavaria Yachts" 641 "Diverse Yacht Services" 644 "Wema U.S.A dba KUS" 658 "Shenzhen Jiuzhou Himunication" 688 "Rockford" 699 "Harman International" 704 "JL Audio" 708 "Lars Thrane" 715 "Autonnic" 717 "Yacht Devices" 734 "REAP Systems" 735 "AEM Performance Electronics" 739 "LxNav" 741 "Littelfuse, Inc (formerly Carling Technologies)" 743 "DaeMyung" 744 "Woosung" 748 "ISOTTA IFRA srl" 773 "Clarion US" 776 "HMI Systems" 777 "Ocean Signal" 778 "Seakeeper" 781 "Poly Planar" 785 "Fischer Panda DE" 795 "Broyda Industries" 796 "Canadian Automotive" 797 "Tides Marine" 798 "Lumishore" 799 "Still Water Designs and Audio" 802 "BJ Technologies (Beneteau)" 803 "Gill Sensors" 811 "Blue Water Desalination" 815 "FLIR" 824 "Undheim Systems" 826 "Lewmar" 838 "TeamSurv" 844 "Fell Marine" 847 "Oceanvolt" 862 "Prospec" 868 "Data Panel" 890 "L3 Technologies" 894 "Rhodan Marine Systems" 896 "Nexfour Solutions" 905 "ASA Electronics" 909 "Marines Co (South Korea)" 911 "Nautic-on" 917 "Sentinel" 929 "JL Marine Systems" 930 "Ecotronix" 944 "Zontisa Marine" 951 "EXOR International" 962 "Timbolier Industries" 963 "TJC Micro" 968 "Cox Powertrain" 969 "Blue Seas" 981 "Kobelt Manufacturing" 992 "Blue Ocean IOT" 997 "Xenta Systems" 999 "Signal K" 1004 "Ultraflex" 1008 "Lintest SmartBoat" 1011 "Soundmax" 1020 "Team Italia Marine (Onyx Marine Automation s.r.l)" 1021 "Entratech" 1022 "ITC" 1029 "The Marine Guardian" 1047 "Sonic" 1051 "ProNav" 1053 "Vetus Maxwell INC." 1056 "Lithium Pros" 1059 "Boatrax" 1062 "Marol Co ltd" 1065 "CALYPSO Instruments" 1066 "Spot Zero Water" 1069 "Lithionics Battery" 1070 "Quick-teck Electronics" 1075 "Uniden America" 1083 "Nauticoncept" 1084 "Shadow-Caster LED lighting" 1085 "Wet Sounds" 1088 "E-T-A Circuit Breakers" 1092 "Scheiber" 1100 "Smart Yachts International Limited" 1109 "Dockmate" 1114 "Bobs Machine" 1118 "L3Harris ASV" 1119 "Balmar" 1120 "Elettromedia" 1127 "Electromaax" 1140 "Across Oceans Systems" 1145 "Kiwi Yachting" 1150 "BSB Artificial Intelligence" 1151 "Orca Technologies" 1154 "TBS Electronics" 1158 "Technoton Electroics" 1160 "MG Energy Systems" 1169 "Sea Machine Robotics" 1171 "Vista Manufacturing" 1183 "Zipwake" 1186 "Sailmon" 1192 "Airmoniq Pro Kft" 1194 "Sierra Marine" 1200 "Xinuo Information Technology (Xiamen)" 1218 "Septentrio" 1233 "NKE Marine Electronics" 1238 "SuperTrack Aps" 1239 "Honda Electronics" 1245 "Raritan Engineering" 1249 "Integrated Power Solutions AG" 1260 "Interactive Technologies" 1283 "LTG-Tech" 1299 "Energy Solutions (UK)" 1300 "WATT Fuel Cell" 1302 "Pro Mainer" 1305 "Dragonfly Energy" 1306 "Koden Electronics" 1311 "Humphree" 1316 "Hinkley Yachts" 1317 "Global Marine Management GmbH (GMM)" 1320 "Triskel Marine" 1330 "Warwick Control Technologies" 1331 "Dolphin Charger" 1337 "Barnacle Systems" 1348 "Radian IoT" 1353 "Ocean LED Marine" 1359 "BluNav" 1361 "OVA (Nantong Saiyang Electronics Co., Ltd)" 1368 "RAD Propulsion" 1369 "Electric Yacht" 1372 "Elco Motor Yachts" 1384 "Tecnoseal Foundry S.r.l" 1385 "Pro Charging Systems" 1389 "EVEX" 1398 "Gobius Sensor Technology" 1403 "Arco Marine" 1408 "Lenco Marine" 1413 "Naocontrol" 1417 "Revatek" 1438 "Aeolionics" 1439 "PredictWind" 1440 "Egis Mobile Electric" 1445 "Starboard Yacht Group" 1446 "Roswell Marine" 1451 "ePropulsion (Guangdong ePropulsion Technology Ltd.)" 1452 "Micro-Air" 1453 "Vital Battery" 1458 "Ride Controller" 1460 "Tocaro Blue" 1461 "Vanquish Yachts" 1471 "FT Technologies" 1478 "Alps Alpine" 1481 "E-Force Marine" 1482 "CMC Marine" 1483 "Nanjing Sandemarine Information Technology" 1850 "Teleflex Marine (SeaStar Solutions)" 1851 "Raymarine" 1852 "Navionics" 1853 "Japan Radio" 1854 "Northstar Technologies" 1855 "Furuno" 1856 "Trimble" 1857 "Simrad" 1858 "Litton" 1859 "Kvasar" 1860 "MMP" 1861 "Vector Cantech" 1862 "Yamaha Marine" 1863 "Faria Instruments" ;
VAL_ 2583631872 Industry_Code 0 "Global" 1 "Highway" 2 "Agriculture" 3 "Construction" 4 "Marine Industry" 5 "Industrial" ;
VAL_ 2382305280 Manufacturer_Code 69 "ARKS Enterprises" 78 "FW Murphy/Enovation Controls" 80 "Twin Disc" 85 "Kohler Power Systems" 88 "Hemisphere GPS" 135 "Airmar" 137 "Maretron" 140 "Lowrance" 144 "Mercury Marine" 147 "Nautibus Electronic" 148 "Blue Water Data" 154 "Westerbeke" 157 "ISSPRO" 161 "Offshore Systems (UK)" 163 "Evinrude/BRP" 165 "CPAC Systems" 168 "Xantrex Technology" 169 "Marlin Technologies" 172 "Yanmar Marine" 174 "Volvo Penta" 176 "Carling Technologies Inc. (Moritz Aerospace)" 185 "Beede Instruments" 192 "Floscan Instrument" 193 "Nobeltec" 198 "Mystic Valley Communications" 199 "Actia" 201 "Disenos Y Technologia" 211 "Digital Switching Systems" 215 "Xintex/Atena" 224 "EMMI NETWORK" 228 "ZF" 229 "Garmin" 233 "Yacht Monitoring Solutions" 235 "Sailormade Marine Telemetry/Tetra Technology" 243 "Eride" 257 "Honda Motor" 272 "Groco" 273 "Actisense" 274 "Amphenol LTW Technology" 275 "Navico" 283 "Hamilton Jet" 285 "Sea Recovery" 286 "Coelmo SRL Italy" 295 "BEP Marine" 304 "Empir Bus" 305 "NovAtel" 306 "Sleipner Motor" 307 "MBW Technologies" 315 "ICOM" 328 "Qwerty" 329 "Dief" 341 "Boening Automationstechnologie" 345 "Korean Maritime University" 351 "Thrane and Thrane" 355 "Mastervolt" 356 "Fischer Panda Generators" 358 "Victron Energy" 370 "Rolls Royce Marine" 373 "Electronic Design" 374 "Northern Lights" 378 "Glendinning" 381 "B & G" 384 "Rose Point Navigation Systems" 385 "Johnson Outdoors Marine Electronics Inc Geonav" 394 "Capi 2" 396 "Beyond Measure" 400 "Livorsi Marine" 404 "ComNav" 409 "Chetco" 419 "Fusion Electronics" 421 "Standard Horizon" 422 "True Heading" 426 "Egersund Marine Electronics" 427 "em-trak Marine Electronics" 431 "Tohatsu Co, JP" 437 "Digital Yacht" 438 "Comar Systems Limited" 440 "Cummins" 443 "VDO (aka Continental-Corporation)" 451 "Parker Hannifin aka Village Marine Tech" 459 "Alltek Marine Electronics" 460 "SAN GIORGIO S.E.I.N" 466 "Veethree Electronics & Marine" 470 "SI-TEX Marine Electronics" 471 "Sea Cross Marine" 475 "GME aka Standard Communications" 476 "Humminbird Marine Electronics" 478 "Ocean Sat" 481 "Chetco Digital Instruments" 493 "Watcheye" 499 "Lcj Capteurs" 502 "Attwood Marine" 503 "Naviop S.R.L." 504 "Vesper Marine" 510 "Marinesoft" 513 "Simarine" 517 "NoLand Engineering" 518 "Transas USA" 529 "National Instruments Korea" 530 "National Marine Electronics Association" 532 "Onwa Marine" 540 "Webasto" 571 "Marinecraft (South Korea)" 573 "McMurdo Group aka Orolia" 578 "Advansea" 579 "KVH" 580 "San Jose Technology" 583 "Yacht Control" 586 "Suzuki Motor" 591 "US Coast Guard" 595 "Ship Module aka Customware" 600 "Aquatic AV" 605 "Aventics" 606 "Intellian" 612 "SamwonIT" 614 "Arlt Tecnologies" 637 "Bavaria Yachts" 641 "Diverse Yacht Services" 644 "Wema U.S.A dba KUS" 658 "Shenzhen Jiuzhou Himunication" 688 "Rockford" 699 "Harman International" 704 "JL Audio" 708 "Lars Thrane" 715 "Autonnic" 717 "Yacht Devices" 734 "REAP Systems" 735 "AEM Performance Electronics" 739 "LxNav" 741 "Littelfuse, Inc (formerly Carling Technologies)" 743 "DaeMyung" 744 "Woosung" 748 "ISOTTA IFRA srl" 773 "Clarion US" 776 "HMI Systems" 777 "Ocean Signal" 778 "Seakeeper" 781 "Poly Planar" 785 "Fischer Panda DE" 795 "Broyda Industries" 796 "Canadian Automotive" 797 "Tides Marine" 798 "Lumishore" 799 "Still Water Designs and Audio" 802 "BJ Technologies (Beneteau)" 803 "Gill Sensors" 811 "Blue Water Desalination" 815 "FLIR" 824 "Undheim Systems" 826 "Lewmar" 838 "TeamSurv" 844 "Fell Marine" 847 "Oceanvolt" 862 "Prospec" 868 "Data Panel" 890 "L3 Technologies" 894 "Rhodan Marine Systems" 896 "Nexfour Solutions" 905 "ASA Electronics" 909 "Marines Co (South Korea)" 911 "Nautic-on" 917 "Sentinel" 929 "JL Marine Systems" 930 "Ecotronix" 944 "Zontisa Marine" 951 "EXOR International" 962 "Timbolier Industries" 963 "TJC Micro" 968 "Cox Powertrain" 969 "Blue Seas" 981 "Kobelt Manufacturing" 992 "Blue Ocean IOT" 997 "Xenta Systems" 999 "Signal K" 1004 "Ultraflex" 1008 "Lintest SmartBoat" 1011 "Soundmax" 1020 "Team Italia Marine (Onyx Marine Automation s.r.l)" 1021 "Entratech" 1022 "ITC" 1029 "The Marine Guardian" 1047 "Sonic" 1051 "ProNav" 1053 "Vetus Maxwell INC." 1056 "Lithium Pros" 1059 "Boatrax" 1062 "Marol Co ltd" 1065 "CALYPSO Instruments" 1066 "Spot Zero Water" 1069 "Lithionics Battery" 1070 "Quick-teck Electronics" 1075 "Uniden America" 1083 "Nauticoncept" 1084 "Shadow-Caster LED lighting" 1085 "Wet Sounds" 1088 "E-T-A Circuit Breakers" 1092 "Scheiber" 1100 "Smart Yachts International Limited" 1109 "Dockmate" 1114 "Bobs Machine" 1118 "L3Harris ASV" 1119 "Balmar" 1120 "Elettromedia" 1127 "Electromaax" 1140 "Across Oceans Systems" 1145 "Kiwi Yachting" 1150 "BSB Artificial Intelligence" 1151 "Orca Technologies" 1154 "TBS Electronics" 1158 "Technoton Electroics" 1160 "MG Energy Systems" 1169 "Sea Machine Robotics" 1171 "Vista Manufacturing" 1183 "Zipwake" 1186 "Sailmon" 1192 "Airmoniq Pro Kft" 1194 "Sierra Marine" 1200 "Xinuo Information Technology (Xiamen)" 1218 "Septentrio" 1233 "NKE Marine Electronics" 1238 "SuperTrack Aps" 1239 "Honda Electronics" 1245 "Raritan Engineering" 1249 "Integrated Power Solutions AG" 1260 "Interactive Technologies" 1283 "LTG-Tech" 1299 "Energy Solutions (UK)" 1300 "WATT Fuel Cell" 1302 "Pro Mainer" 1305 "Dragonfly Energy" 1306 "Koden Electronics" 1311 "Humphree" 1316 "Hinkley Yachts" 1317 "Global Marine Management GmbH (GMM)" 1320 "Triskel Marine" 1330 "Warwick Control Technologies" 1331 "Dolphin Charger" 1337 "Barnacle Systems" 1348 "Radian IoT" 1353 "Ocean LED Marine" 1359 "BluNav" 1361 "OVA (Nantong Saiyang Electronics Co., Ltd)" 1368 "RAD Propulsion" 1369 "Electric Yacht" 1372 "Elco Motor Yachts" 1384 "Tecnoseal Foundry S.r.l" 1385 "Pro Charging Systems" 1389 "EVEX" 1398 "Gobius Sensor Technology" 1403 "Arco Marine" 1408 "Lenco Marine" 1413 "Naocontrol" 1417 "Revatek" 1438 "Aeolionics" 1439 "PredictWind" 1440 "Egis Mobile Electric" 1445 "Starboard Yacht Group" 1446 "Roswell Marine" 1451 "ePropulsion (Guangdong ePropulsion Technology Ltd.)" 1452 "Micro-Air" 1453 "Vital Battery" 1458 "Ride Controller" 1460 "Tocaro Blue" 1461 "Vanquish Yachts" 1471 "FT Technologies" 1478 "Alps Alpine" 1481 "E-Force Marine" 1482 "CMC Marine" 1483 "Nanjing Sandemarine Information Technology" 1850 "Teleflex Marine (SeaStar Solutions)" 1851 "Raymarine" 1852 "Navionics" 1853 "Japan Radio" 1854 "Northstar Technologies" 1855 "Furuno" 1856 "Trimble" 1857 "Simrad" 1858 "Litton" 1859 "Kvasar" 1860 "MMP" 1861 "Vector Cantech" 1862 "Yamaha Marine" 1863 "Faria Instruments" ;
VAL_ 2382305280 Industry_Code 0 "Global" 1 "Highway" 2 "Agriculture" 3 "Construction" 4 "Marine Industry" 5 "Industrial" ;
VAL_ 2382305280 Data_Type 0 "Heading" 1 "Navigation" 2 "Position" 3 "Apparent Wind" 4 "True Wind" 5 "Speed Through Water" 6 "Sea Temperature" 7 "Distance Log" 8 "Depth" 9 "Rudder Feedback" 19 "Monitor Compass" 20 "Position Backup" 21 "Boat Speed Backup" 22 "Air Temperature" 28 "Barometric Pressure" 30 "Heel Angle" 34 "Sailing Navigation" 35 "Trim Angle" 36 "Sailing" 37 "Aft Depth" 38 "Speed Log" 39 "RTCM Signal" 40 "RTCM Corrections" 54 "Autopilot" 59 "Autopilot Function Backup" 104 "Autopilot Control" ;
VAL_ 2583632128 Manufacturer_Code 69 "ARKS Enterprises" 78 "FW Murphy/Enovation Controls" 80 "Twin Disc" 85 "Kohler Power Systems" 88 "Hemisphere GPS" 135 "Airmar" 137 "Maretron" 140 "Lowrance" 144 "Mercury Marine" 147 "Nautibus Electronic" 148 "Blue Water Data" 154 "Westerbeke" 157 "ISSPRO" 161 "Offshore Systems (UK)" 163 "Evinrude/BRP" 165 "CPAC Systems" 168 "Xantrex Technology" 169 "Marlin Technologies" 172 "Yanmar Marine" 174 "Volvo Penta" 176 "Carling Technologies Inc. (Moritz Aerospace)" 185 "Beede Instruments" 192 "Floscan Instrument" 193 "Nobeltec" 198 "Mystic Valley Communications" 199 "Actia" 201 "Disenos Y Technologia" 211 "Digital Switching Systems" 215 "Xintex/Atena" 224 "EMMI NETWORK" 228 "ZF" 229 "Garmin" 233 "Yacht Monitoring Solutions" 235 "Sailormade Marine Telemetry/Tetra Technology" 243 "Eride" 257 "Honda Motor" 272 "Groco" 273 "Actisense" 274 "Amphenol LTW Technology" 275 "Navico" 283 "Hamilton Jet" 285 "Sea Recovery" 286 "Coelmo SRL Italy" 295 "BEP Marine" 304 "Empir Bus" 305 "NovAtel" 306 "Sleipner Motor" 307 "MBW Technologies" 315 "ICOM" 328 "Qwerty" 329 "Dief" 341 "Boening Automationstechnologie" 345 "Korean Maritime University" 351 "Thrane and Thrane" 355 "Mastervolt" 356 "Fischer Panda Generators" 358 "Victron Energy" 370 "Rolls Royce Marine" 373 "Electronic Design" 374 "Northern Lights" 378 "Glendinning" 381 "B & G" 384 "Rose Point Navigation Systems" 385 "Johnson Outdoors Marine Electronics Inc Geonav" 394 "Capi 2" 396 "Beyond Measure" 400 "Livorsi Marine" 404 "ComNav" 409 "Chetco" 419 "Fusion Electronics" 421 "Standard Horizon" 422 "True Heading" 426 "Egersund Marine Electronics" 427 "em-trak Marine Electronics" 431 "Tohatsu Co, JP" 437 "Digital Yacht" 438 "Comar Systems Limited" 440 "Cummins" 443 "VDO (aka Continental-Corporation)" 451 "Parker Hannifin aka Village Marine Tech" 459 "Alltek Marine Electronics" 460 "SAN GIORGIO S.E.I.N" 466 "Veethree Electronics & Marine" 470 "SI-TEX Marine Electronics" 471 "Sea Cross Marine" 475 "GME aka Standard Communications" 476 "Humminbird Marine Electronics" 478 "Ocean Sat" 481 "Chetco Digital Instruments" 493 "Watcheye" 499 "Lcj Capteurs" 502 "Attwood Marine" 503 "Naviop S.R.L." 504 "Vesper Marine" 510 "Marinesoft" 513 "Simarine" 517 "NoLand Engineering" 518 "Transas USA" 529 "National Instruments Korea" 530 "National Marine Electronics Association" 532 "Onwa Marine" 540 "Webasto" 571 "Marinecraft (South Korea)" 573 "McMurdo Group aka Orolia" 578 "Advansea" 579 "KVH" 580 "San Jose Technology" 583 "Yacht Control" 586 "Suzuki Motor" 591 "US Coast Guard" 595 "Ship Module aka Customware" 600 "Aquatic AV" 605 "Aventics" 606 "Intellian" 612 "SamwonIT" 614 "Arlt Tecnologies" 637 "Bavaria Yachts" 641 "Diverse Yacht Services" 644 "Wema U.S.A dba KUS" 658 "Shenzhen Jiuzhou Himunication" 688 "Rockford" 699 "Harman International" 704 "JL Audio" 708 "Lars Thrane" 715 "Autonnic" 717 "Yacht Devices" 734 "REAP Systems" 735 "AEM Performance Electronics" 739 "LxNav" 741 "Littelfuse, Inc (formerly Carling Technologies)" 743 "DaeMyung" 744 "Woosung" 748 "ISOTTA IFRA srl" 773 "Clarion US" 776 "HMI Systems" 777 "Ocean Signal" 778 "Seakeeper" 781 "Poly Planar" 785 "Fischer Panda DE" 795 "Broyda Industries" 796 "Canadian Automotive" 797 "Tides Marine" 798 "Lumishore" 799 "Still Water Designs and Audio" 802 "BJ Technologies (Beneteau)" 803 "Gill Sensors" 811 "Blue Water Desalination" 815 "FLIR" 824 "Undheim Systems" 826 "Lewmar" 838 "TeamSurv" 844 "Fell Marine" 847 "Oceanvolt" 862 "Prospec" 868 "Data Panel" 890 "L3 Technologies" 894 "Rhodan Marine Systems" 896 "Nexfour Solutions" 905 "ASA Electronics" 909 "Marines Co (South Korea)" 911 "Nautic-on" 917 "Sentinel" 929 "JL Marine Systems" 930 "Ecotronix" 944 "Zontisa Marine" 951 "EXOR International" 962 "Timbolier Industries" 963 "TJC Micro" 968 "Cox Powertrain" 969 "Blue Seas" 981 "Kobelt Manufacturing" 992 "Blue Ocean IOT" 997 "Xenta Systems" 999 "Signal K" 1004 "Ultraflex" 1008 "Lintest SmartBoat" 1011 "Soundmax" 1020 "Team Italia Marine (Onyx Marine Automation s.r.l)" 1021 "Entratech" 1022 "ITC" 1029 "The Marine Guardian" 1047 "Sonic" 1051 "ProNav" 1053 "Vetus Maxwell INC." 1056 "Lithium Pros" 1059 "Boatrax" 1062 "Marol Co ltd" 1065 "CALYPSO Instruments" 1066 "Spot Zero Water" 1069 "Lithionics Battery" 1070 "Quick-teck Electronics" 1075 "Uniden America" 1083 "Nauticoncept" 1084 "Shadow-Caster LED lighting" 1085 "Wet Sounds" 1088 "E-T-A Circuit Breakers" 1092 "Scheiber" 1100 "Smart Yachts International Limited" 1109 "Dockmate" 1114 "Bobs Machine" 1118 "L3Harris ASV" 1119 "Balmar" 1120 "Elettromedia" 1127 "Electromaax" 1140 "Across Oceans Systems" 1145 "Kiwi Yachting" 1150 "BSB Artificial Intelligence" 1151 "Orca Technologies" 1154 "TBS Electronics" 1158 "Technoton Electroics" 1160 "MG Energy Systems" 1169 "Sea Machine Robotics" 1171 "Vista Manufacturing" 1183 "Zipwake" 1186 "Sailmon" 1192 "Airmoniq Pro Kft" 1194 "Sierra Marine" 1200 "Xinuo Information Technology (Xiamen)" 1218 "Septentrio" 1233 "NKE Marine Electronics" 1238 "SuperTrack Aps" 1239 "Honda Electronics" 1245 "Raritan Engineering" 1249 "Integrated Power Solutions AG" 1260 "Interactive Technologies" 1283 "LTG-Tech" 1299 "Energy Solutions (UK)" 1300 "WATT Fuel Cell" 1302 "Pro Mainer" 1305 "Dragonfly Energy" 1306 "Koden Electronics" 1311 "Humphree" 1316 "Hinkley Yachts" 1317 "Global Marine Management GmbH (GMM)" 1320 "Triskel Marine" 1330 "Warwick Control Technologies" 1331 "Dolphin Charger" 1337 "Barnacle Systems" 1348 "Radian IoT" 1353 "Ocean LED Marine" 1359 "BluNav" 1361 "OVA (Nantong Saiyang Electronics Co., Ltd)" 1368 "RAD Propulsion" 1369 "Electric Yacht" 1372 "Elco Motor Yachts" 1384 "Tecnoseal Foundry S.r.l" 1385 "Pro Charging Systems" 1389 "EVEX" 1398 "Gobius Sensor Technology" 1403 "Arco Marine" 1408 "Lenco Marine" 1413 "Naocontrol" 1417 "Revatek" 1438 "Aeolionics" 1439 "PredictWind" 1440 "Egis Mobile Electric" 1445 "Starboard Yacht Group" 1446 "Roswell Marine" 1451 "ePropulsion (Guangdong ePropulsion Technology Ltd.)" 1452 "Micro-Air" 1453 "Vital Battery" 1458 "Ride Controller" 1460 "Tocaro Blue" 1461 "Vanquish Yachts" 1471 "FT Technologies" 1478 "Alps Alpine" 1481 "E-Force Marine" 1482 "CMC Marine" 1483 "Nanjing Sandemarine Information Technology" 1850 "Teleflex Marine (SeaStar Solutions)" 1851 "Raymarine" 1852 "Navionics" 1853 "Japan Radio" 1854 "Northstar Technologies" 1855 "Furuno" 1856 "Trimble" 1857 "Simrad" 1858 "Litton" 1859 "Kvasar" 1860 "MMP" 1861 "Vector Cantech" 1862 "Yamaha Marine" 1863 "Faria Instruments" ;
VAL_ 2583632128 Industry_Code 0 "Global" 1 "Highway" 2 "Agriculture" 3 "Construction" 4 "Marine Industry" 5 "Industrial" ;
VAL_ 2583632384 Manufacturer_Code 69 "ARKS Enterprises" 78 "FW Murphy/Enovation Controls" 80 "Twin Disc" 85 "Kohler Power Systems" 88 "Hemisphere GPS" 135 "Airmar" 137 "Maretron" 140 "Lowrance" 144 "Mercury Marine" 147 "Nautibus Electronic" 148 "Blue Water Data" 154 "Westerbeke" 157 "ISSPRO" 161 "Offshore Systems (UK)" 163 "Evinrude/BRP" 165 "CPAC Systems" 168 "Xantrex Technology" 169 "Marlin Technologies" 172 "Yanmar Marine" 174 "Volvo Penta" 176 "Carling Technologies Inc. (Moritz Aerospace)" 185 "Beede Instruments" 192 "Floscan Instrument" 193 "Nobeltec" 198 "Mystic Valley Communications" 199 "Actia" 201 "Disenos Y Technologia" 211 "Digital Switching Systems" 215 "Xintex/Atena" 224 "EMMI NETWORK" 228 "ZF" 229 "Garmin" 233 "Yacht Monitoring Solutions" 235 "Sailormade Marine Telemetry/Tetra Technology" 243 "Eride" 257 "Honda Motor" 272 "Groco" 273 "Actisense" 274 "Amphenol LTW Technology" 275 "Navico" 283 "Hamilton Jet" 285 "Sea Recovery" 286 "Coelmo SRL Italy" 295 "BEP Marine" 304 "Empir Bus" 305 "NovAtel" 306 "Sleipner Motor" 307 "MBW Technologies" 315 "ICOM" 328 "Qwerty" 329 "Dief" 341 "Boening Automationstechnologie" 345 "Korean Maritime University" 351 "Thrane and Thrane" 355 "Mastervolt" 356 "Fischer Panda Generators" 358 "Victron Energy" 370 "Rolls Royce Marine" 373 "Electronic Design" 374 "Northern Lights" 378 "Glendinning" 381 "B & G" 384 "Rose Point Navigation Systems" 385 "Johnson Outdoors Marine Electronics Inc Geonav" 394 "Capi 2" 396 "Beyond Measure" 400 "Livorsi Marine" 404 "ComNav" 409 "Chetco" 419 "Fusion Electronics" 421 "Standard Horizon" 422 "True Heading" 426 "Egersund Marine Electronics" 427 "em-trak Marine Electronics" 431 "Tohatsu Co, JP" 437 "Digital Yacht" 438 "Comar Systems Limited" 440 "Cummins" 443 "VDO (aka Continental-Corporation)" 451 "Parker Hannifin aka Village Marine Tech" 459 "Alltek Marine Electronics" 460 "SAN GIORGIO S.E.I.N" 466 "Veethree Electronics & Marine" 470 "SI-TEX Marine Electronics" 471 "Sea Cross Marine" 475 "GME aka Standard Communications" 476 "Humminbird Marine Electronics" 478 "Ocean Sat" 481 "Chetco Digital Instruments" 493 "Watcheye" 499 "Lcj Capteurs" 502 "Attwood Marine" 503 "Naviop S.R.L." 504 "Vesper Marine" 510 "Marinesoft" 513 "Simarine" 517 "NoLand Engineering" 518 "Transas USA" 529 "National Instruments Korea" 530 "National Marine Electronics Association" 532 "Onwa Marine" 540 "Webasto" 571 "Marinecraft (South Korea)" 573 "McMurdo Group aka Orolia" 578 "Advansea" 579 "KVH" 580 "San Jose Technology" 583 "Yacht Control" 586 "Suzuki Motor" 591 "US Coast Guard" 595 "Ship Module aka Customware" 600 "Aquatic AV" 605 "Aventics" 606 "Intellian" 612 "SamwonIT" 614 "Arlt Tecnologies" 637 "Bavaria Yachts" 641 "Diverse Yacht Services" 644 "Wema U.S.A dba KUS" 658 "Shenzhen Jiuzhou Himunication" 688 "Rockford" 699 "Harman International" 704 "JL Audio" 708 "Lars Thrane" 715 "Autonnic" 717 "Yacht Devices" 734 "REAP Systems" 735 "AEM Performance Electronics" 739 "LxNav" 741 "Littelfuse, Inc (formerly Carling Technologies)" 743 "DaeMyung" 744 "Woosung" 748 "ISOTTA IFRA srl" 773 "Clarion US" 776 "HMI Systems" 777 "Ocean Signal" 778 "Seakeeper" 781 "Poly Planar" 785 "Fischer Panda DE" 795 "Broyda Industries" 796 "Canadian Automotive" 797 "Tides Marine" 798 "Lumishore" 799 "Still Water Designs and Audio" 802 "BJ Technologies (Beneteau)" 803 "Gill Sensors" 811 "Blue Water Desalination" 815 "FLIR" 824 "Undheim Systems" 826 "Lewmar" 838 "TeamSurv" 844 "Fell Marine" 847 "Oceanvolt" 862 "Prospec" 868 "Data Panel" 890 "L3 Technologies" 894 "Rhodan Marine Systems" 896 "Nexfour Solutions" 905 "ASA Electronics" 909 "Marines Co (South Korea)" 911 "Nautic-on" 917 "Sentinel" 929 "JL Marine Systems" 930 "Ecotronix" 944 "Zontisa Marine" 951 "EXOR International" 962 "Timbolier Industries" 963 "TJC Micro" 968 "Cox Powertrain" 969 "Blue Seas" 981 "Kobelt Manufacturing" 992 "Blue Ocean IOT" 997 "Xenta Systems" 999 "Signal K" 1004 "Ultraflex" 1008 "Lintest SmartBoat" 1011 "Soundmax" 1020 "Team Italia Marine (Onyx Marine Automation s.r.l)" 1021 "Entratech" 1022 "ITC" 1029 "The Marine Guardian" 1047 "Sonic" 1051 "ProNav" 1053 "Vetus Maxwell INC." 1056 "Lithium Pros" 1059 "Boatrax" 1062 "Marol Co ltd" 1065 "CALYPSO Instruments" 1066 "Spot Zero Water" 1069 "Lithionics Battery" 1070 "Quick-teck Electronics" 1075 "Uniden America" 1083 "Nauticoncept" 1084 "Shadow-Caster LED lighting" 1085 "Wet Sounds" 1088 "E-T-A Circuit Breakers" 1092 "Scheiber" 1100 "Smart Yachts International Limited" 1109 "Dockmate" 1114 "Bobs Machine" 1118 "L3Harris ASV" 1119 "Balmar" 1120 "Elettromedia" 1127 "Electromaax" 1140 "Across Oceans Systems" 1145 "Kiwi Yachting" 1150 "BSB Artificial Intelligence" 1151 "Orca Technologies" 1154 "TBS Electronics" 1158 "Technoton Electroics" 1160 "MG Energy Systems" 1169 "Sea Machine Robotics" 1171 "Vista Manufacturing" 1183 "Zipwake" 1186 "Sailmon" 1192 "Airmoniq Pro Kft" 1194 "Sierra Marine" 1200 "Xinuo Information Technology (Xiamen)" 1218 "Septentrio" 1233 "NKE Marine Electronics" 1238 "SuperTrack Aps" 1239 "Honda Electronics" 1245 "Raritan Engineering" 1249 "Integrated Power Solutions AG" 1260 "Interactive Technologies" 1283 "LTG-Tech" 1299 "Energy Solutions (UK)" 1300 "WATT Fuel Cell" 1302 "Pro Mainer" 1305 "Dragonfly Energy" 1306 "Koden Electronics" 1311 "Humphree" 1316 "Hinkley Yachts" 1317 "Global Marine Management GmbH (GMM)" 1320 "Triskel Marine" 1330 "Warwick Control Technologies" 1331 "Dolphin Charger" 1337 "Barnacle Systems" 1348 "Radian IoT" 1353 "Ocean LED Marine" 1359 "BluNav" 1361 "OVA (Nantong Saiyang Electronics Co., Ltd)" 1368 "RAD Propulsion" 1369 "Electric Yacht" 1372 "Elco Motor Yachts" 1384 "Tecnoseal Foundry S.r.l" 1385 "Pro Charging Systems" 1389 "EVEX" 1398 "Gobius Sensor Technology" 1403 "Arco Marine" 1408 "Lenco Marine" 1413 "Naocontrol" 1417 "Revatek" 1438 "Aeolionics" 1439 "PredictWind" 1440 "Egis Mobile Electric" 1445 "Starboard Yacht Group" 1446 "Roswell Marine" 1451 "ePropulsion (Guangdong ePropulsion Technology Ltd.)" 1452 "Micro-Air" 1453 "Vital Battery" 1458 "Ride Controller" 1460 "Tocaro Blue" 1461 "Vanquish Yachts" 1471 "FT Technologies" 1478 "Alps Alpine" 1481 "E-Force Marine" 1482 "CMC Marine" 1483 "Nanjing Sandemarine Information Technology" 1850 "Teleflex Marine (SeaStar Solutions)" 1851 "Raymarine" 1852 "Navionics" 1853 "Japan Radio" 1854 "Northstar Technologies" 1855 "Furuno" 1856 "Trimble" 1857 "Simrad" 1858 "Litton" 1859 "Kvasar" 1860 "MMP" 1861 "Vector Cantech" 1862 "Yamaha Marine" 1863 "Faria Instruments" ;
VAL_ 2583632384 Industry_Code 0 "Global" 1 "Highway" 2 "Agriculture" 3 "Construction" 4 "Marine Industry" 5 "Industrial" ;
VAL_ 2583632384 Manufacturer_Code 69 "ARKS Enterprises" 78 "FW Murphy/Enovation Controls" 80 "Twin Disc" 85 "Kohler Power Systems" 88 "Hemisphere GPS" 135 "Airmar" 137 "Maretron" 140 "Lowrance" 144 "Mercury Marine" 147 "Nautibus Electronic" 148 "Blue Water Data" 154 "Westerbeke" 157 "ISSPRO" 161 "Offshore Systems (UK)" 163 "Evinrude/BRP" 165 "CPAC Systems" 168 "Xantrex Technology" 169 "Marlin Technologies" 172 "Yanmar Marine" 174 "Volvo Penta" 176 "Carling Technologies Inc. (Moritz Aerospace)" 185 "Beede Instruments" 192 "Floscan Instrument" 193 "Nobeltec" 198 "Mystic Valley Communications" 199 "Actia" 201 "Disenos Y Technologia" 211 "Digital Switching Systems" 215 "Xintex/Atena" 224 "EMMI NETWORK" 228 "ZF" 229 "Garmin" 233 "Yacht Monitoring Solutions" 235 "Sailormade Marine Telemetry/Tetra Technology" 243 "Eride" 257 "Honda Motor" 272 "Groco" 273 "Actisense" 274 "Amphenol LTW Technology" 275 "Navico" 283 "Hamilton Jet" 285 "Sea Recovery" 286 "Coelmo SRL Italy" 295 "BEP Marine" 304 "Empir Bus" 305 "NovAtel" 306 "Sleipner Motor" 307 "MBW Technologies" 315 "ICOM" 328 "Qwerty" 329 "Dief" 341 "Boening Automationstechnologie" 345 "Korean Maritime University" 351 "Thrane and Thrane" 355 "Mastervolt" 356 "Fischer Panda Generators" 358 "Victron Energy" 370 "Rolls Royce Marine" 373 "Electronic Design" 374 "Northern Lights" 378 "Glendinning" 381 "B & G" 384 "Rose Point Navigation Systems" 385 "Johnson Outdoors Marine Electronics Inc Geonav" 394 "Capi 2" 396 "Beyond Measure" 400 "Livorsi Marine" 404 "ComNav" 409 "Chetco" 419 "Fusion Electronics" 421 "Standard Horizon" 422 "True Heading" 426 "Egersund Marine Electronics" 427 "em-trak Marine Electronics" 431 "Tohatsu Co, JP" 437 "Digital Yacht" 438 "Comar Systems Limited" 440 "Cummins" 443 "VDO (aka Continental-Corporation)" 451 "Parker Hannifin aka Village Marine Tech" 459 "Alltek Marine Electronics" 460 "SAN GIORGIO S.E.I.N" 466 "Veethree Electronics & Marine" 470 "SI-TEX Marine Electronics" 471 "Sea Cross Marine" 475 "GME aka Standard Communications" 476 "Humminbird Marine Electronics" 478 "Ocean Sat" 481 "Chetco Digital Instruments" 493 "Watcheye" 499 "Lcj Capteurs" 502 "Attwood Marine" 503 "Naviop S.R.L." 504 "Vesper Marine" 510 "Marinesoft" 513 "Simarine" 517 "NoLand Engineering" 518 "Transas USA" 529 "National Instruments Korea" 530 "National Marine Electronics Association" 532 "Onwa Marine" 540 "Webasto" 571 "Marinecraft (South Korea)" 573 "McMurdo Group aka Orolia" 578 "Advansea" 579 "KVH" 580 "San Jose Technology" 583 "Yacht Control" 586 "Suzuki Motor" 591 "US Coast Guard" 595 "Ship Module aka Customware" 600 "Aquatic AV" 605 "Aventics" 606 "Intellian" 612 "SamwonIT" 614 "Arlt Tecnologies" 637 "Bavaria Yachts" 641 "Diverse Yacht Services" 644 "Wema U.S.A dba KUS" 658 "Shenzhen Jiuzhou Himunication" 688 "Rockford" 699 "Harman International" 704 "JL Audio" 708 "Lars Thrane" 715 "Autonnic" 717 "Yacht Devices" 734 "REAP Systems" 735 "AEM Performance Electronics" 739 "LxNav" 741 "Littelfuse, Inc (formerly Carling Technologies)" 743 "DaeMyung" 744 "Woosung" 748 "ISOTTA IFRA srl" 773 "Clarion US" 776 "HMI Systems" 777 "Ocean Signal" 778 "Seakeeper" 781 "Poly Planar" 785 "Fischer Panda DE" 795 "Broyda Industries" 796 "Canadian Automotive" 797 "Tides Marine" 798 "Lumishore" 799 "Still Water Designs and Audio" 802 "BJ Technologies (Beneteau)" 803 "Gill Sensors" 811 "Blue Water Desalination" 815 "FLIR" 824 "Undheim Systems" 826 "Lewmar" 838 "TeamSurv" 844 "Fell Marine" 847 "Oceanvolt" 862 "Prospec" 868 "Data Panel" 890 "L3 Technologies" 894 "Rhodan Marine Systems" 896 "Nexfour Solutions" 905 "ASA Electronics" 909 "Marines Co (South Korea)" 911 "Nautic-on" 917 "Sentinel" 929 "JL Marine Systems" 930 "Ecotronix" 944 "Zontisa Marine" 951 "EXOR International" 962 "Timbolier Industries" 963 "TJC Micro" 968 "Cox Powertrain" 969 "Blue Seas" 981 "Kobelt Manufacturing" 992 "Blue Ocean IOT" 997 "Xenta Systems" 999 "Signal K" 1004 "Ultraflex" 1008 "Lintest SmartBoat" 1011 "Soundmax" 1020 "Team Italia Marine (Onyx Marine Automation s.r.l)" 1021 "Entratech" 1022 "ITC" 1029 "The Marine Guardian" 1047 "Sonic" 1051 "ProNav" 1053 "Vetus Maxwell INC." 1056 "Lithium Pros" 1059 "Boatrax" 1062 "Marol Co ltd" 1065 "CALYPSO Instruments" 1066 "Spot Zero Water" 1069 "Lithionics Battery" 1070 "Quick-teck Electronics" 1075 "Uniden America" 1083 "Nauticoncept" 1084 "Shadow-Caster LED lighting" 1085 "Wet Sounds" 1088 "E-T-A Circuit Breakers" 1092 "Scheiber" 1100 "Smart Yachts International Limited" 1109 "Dockmate" 1114 "Bobs Machine" 1118 "L3Harris ASV" 1119 "Balmar" 1120 "Elettromedia" 1127 "Electromaax" 1140 "Across Oceans Systems" 1145 "Kiwi Yachting" 1150 "BSB Artificial Intelligence" 1151 "Orca Technologies" 1154 "TBS Electronics" 1158 "Technoton Electroics" 1160 "MG Energy Systems" 1169 "Sea Machine Robotics" 1171 "Vista Manufacturing" 1183 "Zipwake" 1186 "Sailmon" 1192 "Airmoniq Pro Kft" 1194 "Sierra Marine" 1200 "Xinuo Information Technology (Xiamen)" 1218 "Septentrio" 1233 "NKE Marine Electronics" 1238 "SuperTrack Aps" 1239 "Honda Electronics" 1245 "Raritan Engineering" 1249 "Integrated Power Solutions AG" 1260 "Interactive Technologies" 1283 "LTG-Tech" 1299 "Energy Solutions (UK)" 1300 "WATT Fuel Cell" 1302 "Pro Mainer" 1305 "Dragonfly Energy" 1306 "Koden Electronics" 1311 "Humphree" 1316 "Hinkley Yachts" 1317 "Global Marine Management GmbH (GMM)" 1320 "Triskel Marine" 1330 "Warwick Control Technologies" 1331 "Dolphin Charger" 1337 "Barnacle Systems" 1348 "Radian IoT" 1353 "Ocean LED Marine" 1359 "BluNav" 1361 "OVA (Nantong Saiyang Electronics Co., Ltd)" 1368 "RAD Propulsion" 1369 "Electric Yacht" 1372 "Elco Motor Yachts" 1384 "Tecnoseal Foundry S.r.l" 1385 "Pro Charging Systems" 1389 "EVEX" 1398 "Gobius Sensor Technology" 1403 "Arco Marine" 1408 "Lenco Marine" 1413 "Naocontrol" 1417 "Revatek" 1438 "Aeolionics" 1439 "PredictWind" 1440 "Egis Mobile Electric" 1445 "Starboard Yacht Group" 1446 "Roswell Marine" 1451 "ePropulsion (Guangdong ePropulsion Technology Ltd.)" 1452 "Micro-Air" 1453 "Vital Battery" 1458 "Ride Controller" 1460 "Tocaro Blue" 1461 "Vanquish Yachts" 1471 "FT Technologies" 1478 "Alps Alpine" 1481 "E-Force Marine" 1482 "CMC Marine" 1483 "Nanjing Sandemarine Information Technology" 1850 "Teleflex Marine (SeaStar Solutions)" 1851 "Raymarine" 1852 "Navionics" 1853 "Japan Radio" 1854 "Northstar Technologies" 1855 "Furuno" 1856 "Trimble" 1857 "Simrad" 1858 "Litton" 1859 "Kvasar" 1860 "MMP" 1861 "Vector Cantech" 1862 "Yamaha Marine" 1863 "Faria Instruments" ;
VAL_ 2583632384 Industry_Code 0 "Global" 1 "Highway" 2 "Agriculture" 3 "Construction" 4 "Marine Industry" 5 "Industrial" ;
VAL_ 2583632384 Power_Enable 0 "Off" 1 "On" ;
VAL_ 2583632384 Mechanical_Enable 0 "Off" 1 "On" ;
VAL_ 2583632384 Anchor_Docking_Control 0 "Off" 1 "On" ;
VAL_ 2583632384 Deck_and_Anchor_Wash 0 "Off" 1 "On" ;
VAL_ 2583632384 Anchor_Light 0 "Off" 1 "On" ;
VAL_ 2583632384 Auxiliary_A_Control 0 "Off" 1 "On" ;
VAL_ 2583632384 Auxiliary_B_Control 0 "Off" 1 "On" ;
VAL_ 2583632384 Auxiliary_C_Control 0 "Off" 1 "On" ;
VAL_ 2583632384 Auxiliary_D_Control 0 "Off" 1 "On" ;
VAL_ 2583632384 Manufacturer_Code 69 "ARKS Enterprises" 78 "FW Murphy/Enovation Controls" 80 "Twin Disc" 85 "Kohler Power Systems" 88 "Hemisphere GPS" 135 "Airmar" 137 "Maretron" 140 "Lowrance" 144 "Mercury Marine" 147 "Nautibus Electronic" 148 "Blue Water Data" 154 "Westerbeke" 157 "ISSPRO" 161 "Offshore Systems (UK)" 163 "Evinrude/BRP" 165 "CPAC Systems" 168 "Xantrex Technology" 169 "Marlin Technologies" 172 "Yanmar Marine" 174 "Volvo Penta" 176 "Carling Technologies Inc. (Moritz Aerospace)" 185 "Beede Instruments" 192 "Floscan Instrument" 193 "Nobeltec" 198 "Mystic Valley Communications" 199 "Actia" 201 "Disenos Y Technologia" 211 "Digital Switching Systems" 215 "Xintex/Atena" 224 "EMMI NETWORK" 228 "ZF" 229 "Garmin" 233 "Yacht Monitoring Solutions" 235 "Sailormade Marine Telemetry/Tetra Technology" 243 "Eride" 257 "Honda Motor" 272 "Groco" 273 "Actisense" 274 "Amphenol LTW Technology" 275 "Navico" 283 "Hamilton Jet" 285 "Sea Recovery" 286 "Coelmo SRL Italy" 295 "BEP Marine" 304 "Empir Bus" 305 "NovAtel" 306 "Sleipner Motor" 307 "MBW Technologies" 315 "ICOM" 328 "Qwerty" 329 "Dief" 341 "Boening Automationstechnologie" 345 "Korean Maritime University" 351 "Thrane and Thrane" 355 "Mastervolt" 356 "Fischer Panda Generators" 358 "Victron Energy" 370 "Rolls Royce Marine" 373 "Electronic Design" 374 "Northern Lights" 378 "Glendinning" 381 "B & G" 384 "Rose Point Navigation Systems" 385 "Johnson Outdoors Marine Electronics Inc Geonav" 394 "Capi 2" 396 "Beyond Measure" 400 "Livorsi Marine" 404 "ComNav" 409 "Chetco" 419 "Fusion Electronics" 421 "Standard Horizon" 422 "True Heading" 426 "Egersund Marine Electronics" 427 "em-trak Marine Electronics" 431 "Tohatsu Co, JP" 437 "Digital Yacht" 438 "Comar Systems Limited" 440 "Cummins" 443 "VDO (aka Continental-Corporation)" 451 "Parker Hannifin aka Village Marine Tech" 459 "Alltek Marine Electronics" 460 "SAN GIORGIO S.E.I.N" 466 "Veethree Electronics & Marine" 470 "SI-TEX Marine Electronics" 471 "Sea Cross Marine" 475 "GME aka Standard Communications" 476 "Humminbird Marine Electronics" 478 "Ocean Sat" 481 "Chetco Digital Instruments" 493 "Watcheye" 499 "Lcj Capteurs" 502 "Attwood Marine" 503 "Naviop S.R.L." 504 "Vesper Marine" 510 "Marinesoft" 513 "Simarine" 517 "NoLand Engineering" 518 "Transas USA" 529 "National Instruments Korea" 530 "National Marine Electronics Association" 532 "Onwa Marine" 540 "Webasto" 571 "Marinecraft (South Korea)" 573 "McMurdo Group aka Orolia" 578 "Advansea" 579 "KVH" 580 "San Jose Technology" 583 "Yacht Control" 586 "Suzuki Motor" 591 "US Coast Guard" 595 "Ship Module aka Customware" 600 "Aquatic AV" 605 "Aventics" 606 "Intellian" 612 "SamwonIT" 614 "Arlt Tecnologies" 637 "Bavaria Yachts" 641 "Diverse Yacht Services" 644 "Wema U.S.A dba KUS" 658 "Shenzhen Jiuzhou Himunication" 688 "Rockford" 699 "Harman International" 704 "JL Audio" 708 "Lars Thrane" 715 "Autonnic" 717 "Yacht Devices" 734 "REAP Systems" 735 "AEM Performance Electronics" 739 "LxNav" 741 "Littelfuse, Inc (formerly Carling Technologies)" 743 "DaeMyung" 744 "Woosung" 748 "ISOTTA IFRA srl" 773 "Clarion US" 776 "HMI Systems" 777 "Ocean Signal" 778 "Seakeeper" 781 "Poly Planar" 785 "Fischer Panda DE" 795 "Broyda Industries" 796 "Canadian Automotive" 797 "Tides Marine" 798 "Lumishore" 799 "Still Water Designs and Audio" 802 "BJ Technologies (Beneteau)" 803 "Gill Sensors" 811 "Blue Water Desalination" 815 "FLIR" 824 "Undheim Systems" 826 "Lewmar" 838 "TeamSurv" 844 "Fell Marine" 847 "Oceanvolt" 862 "Prospec" 868 "Data Panel" 890 "L3 Technologies" 894 "Rhodan Marine Systems" 896 "Nexfour Solutions" 905 "ASA Electronics" 909 "Marines Co (South Korea)" 911 "Nautic-on" 917 "Sentinel" 929 "JL Marine Systems" 930 "Ecotronix" 944 "Zontisa Marine" 951 "EXOR International" 962 "Timbolier Industries" 963 "TJC Micro" 968 "Cox Powertrain" 969 "Blue Seas" 981 "Kobelt Manufacturing" 992 "Blue Ocean IOT" 997 "Xenta Systems" 999 "Signal K" 1004 "Ultraflex" 1008 "Lintest SmartBoat" 1011 "Soundmax" 1020 "Team Italia Marine (Onyx Marine Automation s.r.l)" 1021 "Entratech" 1022 "ITC" 1029 "The Marine Guardian" 1047 "Sonic" 1051 "ProNav" 1053 "Vetus Maxwell INC." 1056 "Lithium Pros" 1059 "Boatrax" 1062 "Marol Co ltd" 1065 "CALYPSO Instruments" 1066 "Spot Zero Water" 1069 "Lithionics Battery" 1070 "Quick-teck Electronics" 1075 "Uniden America" 1083 "Nauticoncept" 1084 "Shadow-Caster LED lighting" 1085 "Wet Sounds" 1088 "E-T-A Circuit Breakers" 1092 "Scheiber" 1100 "Smart Yachts International Limited" 1109 "Dockmate" 1114 "Bobs Machine" 1118 "L3Harris ASV" 1119 "Balmar" 1120 "Elettromedia" 1127 "Electromaax" 1140 "Across Oceans Systems" 1145 "Kiwi Yachting" 1150 "BSB Artificial Intelligence" 1151 "Orca Technologies" 1154 "TBS Electronics" 1158 "Technoton Electroics" 1160 "MG Energy Systems" 1169 "Sea Machine Robotics" 1171 "Vista Manufacturing" 1183 "Zipwake" 1186 "Sailmon" 1192 "Airmoniq Pro Kft" 1194 "Sierra Marine" 1200 "Xinuo Information Technology (Xiamen)" 1218 "Septentrio" 1233 "NKE Marine Electronics" 1238 "SuperTrack Aps" 1239 "Honda Electronics" 1245 "Raritan Engineering" 1249 "Integrated Power Solutions AG" 1260 "Interactive Technologies" 1283 "LTG-Tech" 1299 "Energy Solutions (UK)" 1300 "WATT Fuel Cell" 1302 "Pro Mainer" 1305 "Dragonfly Energy" 1306 "Koden Electronics" 1311 "Humphree" 1316 "Hinkley Yachts" 1317 "Global Marine Management GmbH (GMM)" 1320 "Triskel Marine" 1330 "Warwick Control Technologies" 1331 "Dolphin Charger" 1337 "Barnacle Systems" 1348 "Radian IoT" 1353 "Ocean LED Marine" 1359 "BluNav" 1361 "OVA (Nantong Saiyang Electronics Co., Ltd)" 1368 "RAD Propulsion" 1369 "Electric Yacht" 1372 "Elco Motor Yachts" 1384 "Tecnoseal Foundry S.r.l" 1385 "Pro Charging Systems" 1389 "EVEX" 1398 "Gobius Sensor Technology" 1403 "Arco Marine" 1408 "Lenco Marine" 1413 "Naocontrol" 1417 "Revatek" 1438 "Aeolionics" 1439 "PredictWind" 1440 "Egis Mobile Electric" 1445 "Starboard Yacht Group" 1446 "Roswell Marine" 1451 "ePropulsion (Guangdong ePropulsion Technology Ltd.)" 1452 "Micro-Air" 1453 "Vital Battery" 1458 "Ride Controller" 1460 "Tocaro Blue" 1461 "Vanquish Yachts" 1471 "FT Technologies" 1478 "Alps Alpine" 1481 "E-Force Marine" 1482 "CMC Marine" 1483 "Nanjing Sandemarine Information Technology" 1850 "Teleflex Marine (SeaStar Solutions)" 1851 "Raymarine" 1852 "Navionics" 1853 "Japan Radio" 1854 "Northstar Technologies" 1855 "Furuno" 1856 "Trimble" 1857 "Simrad" 1858 "Litton" 1859 "Kvasar" 1860 "MMP" 1861 "Vector Cantech" 1862 "Yamaha Marine" 1863 "Faria Instruments" ;
VAL_ 2583632384 Industry_Code 0 "Global" 1 "Highway" 2 "Agriculture" 3 "Construction" 4 "Marine Industry" 5 "Industrial" ;
VAL_ 2583632384 Repeat_Indicator 0 "Initial" 1 "First retransmission" 2 "Second retransmission" 3 "Final retransmission" ;
VAL_ 2583632384 Manufacturer_Code 69 "ARKS Enterprises" 78 "FW Murphy/Enovation Controls" 80 "Twin Disc" 85 "Kohler Power Systems" 88 "Hemisphere GPS" 135 "Airmar" 137 "Maretron" 140 "Lowrance" 144 "Mercury Marine" 147 "Nautibus Electronic" 148 "Blue Water Data" 154 "Westerbeke" 157 "ISSPRO" 161 "Offshore Systems (UK)" 163 "Evinrude/BRP" 165 "CPAC Systems" 168 "Xantrex Technology" 169 "Marlin Technologies" 172 "Yanmar Marine" 174 "Volvo Penta" 176 "Carling Technologies Inc. (Moritz Aerospace)" 185 "Beede Instruments" 192 "Floscan Instrument" 193 "Nobeltec" 198 "Mystic Valley Communications" 199 "Actia" 201 "Disenos Y Technologia" 211 "Digital Switching Systems" 215 "Xintex/Atena" 224 "EMMI NETWORK" 228 "ZF" 229 "Garmin" 233 "Yacht Monitoring Solutions" 235 "Sailormade Marine Telemetry/Tetra Technology" 243 "Eride" 257 "Honda Motor" 272 "Groco" 273 "Actisense" 274 "Amphenol LTW Technology" 275 "Navico" 283 "Hamilton Jet" 285 "Sea Recovery" 286 "Coelmo SRL Italy" 295 "BEP Marine" 304 "Empir Bus" 305 "NovAtel" 306 "Sleipner Motor" 307 "MBW Technologies" 315 "ICOM" 328 "Qwerty" 329 "Dief" 341 "Boening Automationstechnologie" 345 "Korean Maritime University" 351 "Thrane and Thrane" 355 "Mastervolt" 356 "Fischer Panda Generators" 358 "Victron Energy" 370 "Rolls Royce Marine" 373 "Electronic Design" 374 "Northern Lights" 378 "Glendinning" 381 "B & G" 384 "Rose Point Navigation Systems" 385 "Johnson Outdoors Marine Electronics Inc Geonav" 394 "Capi 2" 396 "Beyond Measure" 400 "Livorsi Marine" 404 "ComNav" 409 "Chetco" 419 "Fusion Electronics" 421 "Standard Horizon" 422 "True Heading" 426 "Egersund Marine Electronics" 427 "em-trak Marine Electronics" 431 "Tohatsu Co, JP" 437 "Digital Yacht" 438 "Comar Systems Limited" 440 "Cummins" 443 "VDO (aka Continental-Corporation)" 451 "Parker Hannifin aka Village Marine Tech" 459 "Alltek Marine Electronics" 460 "SAN GIORGIO S.E.I.N" 466 "Veethree Electronics & Marine" 470 "SI-TEX Marine Electronics" 471 "Sea Cross Marine" 475 "GME aka Standard Communications" 476 "Humminbird Marine Electronics" 478 "Ocean Sat" 481 "Chetco Digital Instruments" 493 "Watcheye" 499 "Lcj Capteurs" 502 "Attwood Marine" 503 "Naviop S.R.L." 504 "Vesper Marine" 510 "Marinesoft" 513 "Simarine" 517 "NoLand Engineering" 518 "Transas USA" 529 "National Instruments Korea" 530 "National Marine Electronics Association" 532 "Onwa Marine" 540 "Webasto" 571 "Marinecraft (South Korea)" 573 "McMurdo Group aka Orolia" 578 "Advansea" 579 "KVH" 580 "San Jose Technology" 583 "Yacht Control" 586 "Suzuki Motor" 591 "US Coast Guard" 595 "Ship Module aka Customware" 600 "Aquatic AV" 605 "Aventics" 606 "Intellian" 612 "SamwonIT" 614 "Arlt Tecnologies" 637 "Bavaria Yachts" 641 "Diverse Yacht Services" 644 "Wema U.S.A dba KUS" 658 "Shenzhen Jiuzhou Himunication" 688 "Rockford" 699 "Harman International" 704 "JL Audio" 708 "Lars Thrane" 715 "Autonnic" 717 "Yacht Devices" 734 "REAP Systems" 735 "AEM Performance Electronics" 739 "LxNav" 741 "Littelfuse, Inc (formerly Carling Technologies)" 743 "DaeMyung" 744 "Woosung" 748 "ISOTTA IFRA srl" 773 "Clarion US" 776 "HMI Systems" 777 "Ocean Signal" 778 "Seakeeper" 781 "Poly Planar" 785 "Fischer Panda DE" 795 "Broyda Industries" 796 "Canadian Automotive" 797 "Tides Marine" 798 "Lumishore" 799 "Still Water Designs and Audio" 802 "BJ Technologies (Beneteau)" 803 "Gill Sensors" 811 "Blue Water Desalination" 815 "FLIR" 824 "Undheim Systems" 826 "Lewmar" 838 "TeamSurv" 844 "Fell Marine" 847 "Oceanvolt" 862 "Prospec" 868 "Data Panel" 890 "L3 Technologies" 894 "Rhodan Marine Systems" 896 "Nexfour Solutions" 905 "ASA Electronics" 909 "Marines Co (South Korea)" 911 "Nautic-on" 917 "Sentinel" 929 "JL Marine Systems" 930 "Ecotronix" 944 "Zontisa Marine" 951 "EXOR International" 962 "Timbolier Industries" 963 "TJC Micro" 968 "Cox Powertrain" 969 "Blue Seas" 981 "Kobelt Manufacturing" 992 "Blue Ocean IOT" 997 "Xenta Systems" 999 "Signal K" 1004 "Ultraflex" 1008 "Lintest SmartBoat" 1011 "Soundmax" 1020 "Team Italia Marine (Onyx Marine Automation s.r.l)" 1021 "Entratech" 1022 "ITC" 1029 "The Marine Guardian" 1047 "Sonic" 1051 "ProNav" 1053 "Vetus Maxwell INC." 1056 "Lithium Pros" 1059 "Boatrax" 1062 "Marol Co ltd" 1065 "CALYPSO Instruments" 1066 "Spot Zero Water" 1069 "Lithionics Battery" 1070 "Quick-teck Electronics" 1075 "Uniden America" 1083 "Nauticoncept" 1084 "Shadow-Caster LED lighting" 1085 "Wet Sounds" 1088 "E-T-A Circuit Breakers" 1092 "Scheiber" 1100 "Smart Yachts International Limited" 1109 "Dockmate" 1114 "Bobs Machine" 1118 "L3Harris ASV" 1119 "Balmar" 1120 "Elettromedia" 1127 "Electromaax" 1140 "Across Oceans Systems" 1145 "Kiwi Yachting" 1150 "BSB Artificial Intelligence" 1151 "Orca Technologies" 1154 "TBS Electronics" 1158 "Technoton Electroics" 1160 "MG Energy Systems" 1169 "Sea Machine Robotics" 1171 "Vista Manufacturing" 1183 "Zipwake" 1186 "Sailmon" 1192 "Airmoniq Pro Kft" 1194 "Sierra Marine" 1200 "Xinuo Information Technology (Xiamen)" 1218 "Septentrio" 1233 "NKE Marine Electronics" 1238 "SuperTrack Aps" 1239 "Honda Electronics" 1245 "Raritan Engineering" 1249 "Integrated Power Solutions AG" 1260 "Interactive Technologies" 1283 "LTG-Tech" 1299 "Energy Solutions (UK)" 1300 "WATT Fuel Cell" 1302 "Pro Mainer" 1305 "Dragonfly Energy" 1306 "Koden Electronics" 1311 "Humphree" 1316 "Hinkley Yachts" 1317 "Global Marine Management GmbH (GMM)" 1320 "Triskel Marine" 1330 "Warwick Control Technologies" 1331 "Dolphin Charger" 1337 "Barnacle Systems" 1348 "Radian IoT" 1353 "Ocean LED Marine" 1359 "BluNav" 1361 "OVA (Nantong Saiyang Electronics Co., Ltd)" 1368 "RAD Propulsion" 1369 "Electric Yacht" 1372 "Elco Motor Yachts" 1384 "Tecnoseal Foundry S.r.l" 1385 "Pro Charging Systems" 1389 "EVEX" 1398 "Gobius Sensor Technology" 1403 "Arco Marine" 1408 "Lenco Marine" 1413 "Naocontrol" 1417 "Revatek" 1438 "Aeolionics" 1439 "PredictWind" 1440 "Egis Mobile Electric" 1445 "Starboard Yacht Group" 1446 "Roswell Marine" 1451 "ePropulsion (Guangdong ePropulsion Technology Ltd.)" 1452 "Micro-Air" 1453 "Vital Battery" 1458 "Ride Controller" 1460 "Tocaro Blue" 1461 "Vanquish Yachts" 1471 "FT Technologies" 1478 "Alps Alpine" 1481 "E-Force Marine" 1482 "CMC Marine" 1483 "Nanjing Sandemarine Information Technology" 1850 "Teleflex Marine (SeaStar Solutions)" 1851 "Raymarine" 1852 "Navionics" 1853 "Japan Radio" 1854 "Northstar Technologies" 1855 "Furuno" 1856 "Trimble" 1857 "Simrad" 1858 "Litton" 1859 "Kvasar" 1860 "MMP" 1861 "Vector Cantech" 1862 "Yamaha Marine" 1863 "Faria Instruments" ;
VAL_ 2583632384 Industry_Code 0 "Global" 1 "Highway" 2 "Agriculture" 3 "Construction" 4 "Marine Industry" 5 "Industrial" ;
VAL_ 2583632384 Repeat_Indicator 0 "Initial" 1 "First retransmission" 2 "Second retransmission" 3 "Final retransmission" ;
VAL_ 2583632384 Type_of_ship 0 "Unavailable" 20 "Wing In Ground" 21 "Wing In Ground (hazard cat X)" 22 "Wing In Ground (hazard cat Y)" 23 "Wing In Ground (hazard cat Z)" 24 "Wing In Ground (hazard cat OS)" 29 "Wing In Ground (no additional information)" 30 "Fishing" 31 "Towing" 32 "Towing exceeds 200m or wider than 25m" 33 "Engaged in dredging or underwater operations" 34 "Engaged in diving operations" 35 "Engaged in military operations" 36 "Sailing" 37 "Pleasure" 40 "High speed craft" 41 "High speed craft (hazard cat X)" 42 "High speed craft (hazard cat Y)" 43 "High speed craft (hazard cat Z)" 44 "High speed craft (hazard cat OS)" 49 "High speed craft (no additional information)" 50 "Pilot vessel" 51 "SAR" 52 "Tug" 53 "Port tender" 54 "Anti-pollution" 55 "Law enforcement" 56 "Spare" 57 "Spare #2" 58 "Medical" 59 "Ships and aircraft of States not parties to an armed conflict" 60 "Passenger ship" 61 "Passenger ship (hazard cat X)" 62 "Passenger ship (hazard cat Y)" 63 "Passenger ship (hazard cat Z)" 64 "Passenger ship (hazard cat OS)" 69 "Passenger ship (no additional information)" 70 "Cargo ship" 71 "Cargo ship (hazard cat X)" 72 "Cargo ship (hazard cat Y)" 73 "Cargo ship (hazard cat Z)" 74 "Cargo ship (hazard cat OS)" 79 "Cargo ship (no additional information)" 80 "Tanker" 81 "Tanker (hazard cat X)" 82 "Tanker (hazard cat Y)" 83 "Tanker (hazard cat Z)" 84 "Tanker (hazard cat OS)" 89 "Tanker (no additional information)" 90 "Other" 91 "Other (hazard cat X)" 92 "Other (hazard cat Y)" 93 "Other (hazard cat Z)" 94 "Other (hazard cat OS)" 99 "Other (no additional information)" ;
VAL_ 2583632384 Manufacturer_Code 69 "ARKS Enterprises" 78 "FW Murphy/Enovation Controls" 80 "Twin Disc" 85 "Kohler Power Systems" 88 "Hemisphere GPS" 135 "Airmar" 137 "Maretron" 140 "Lowrance" 144 "Mercury Marine" 147 "Nautibus Electronic" 148 "Blue Water Data" 154 "Westerbeke" 157 "ISSPRO" 161 "Offshore Systems (UK)" 163 "Evinrude/BRP" 165 "CPAC Systems" 168 "Xantrex Technology" 169 "Marlin Technologies" 172 "Yanmar Marine" 174 "Volvo Penta" 176 "Carling Technologies Inc. (Moritz Aerospace)" 185 "Beede Instruments" 192 "Floscan Instrument" 193 "Nobeltec" 198 "Mystic Valley Communications" 199 "Actia" 201 "Disenos Y Technologia" 211 "Digital Switching Systems" 215 "Xintex/Atena" 224 "EMMI NETWORK" 228 "ZF" 229 "Garmin" 233 "Yacht Monitoring Solutions" 235 "Sailormade Marine Telemetry/Tetra Technology" 243 "Eride" 257 "Honda Motor" 272 "Groco" 273 "Actisense" 274 "Amphenol LTW Technology" 275 "Navico" 283 "Hamilton Jet" 285 "Sea Recovery" 286 "Coelmo SRL Italy" 295 "BEP Marine" 304 "Empir Bus" 305 "NovAtel" 306 "Sleipner Motor" 307 "MBW Technologies" 315 "ICOM" 328 "Qwerty" 329 "Dief" 341 "Boening Automationstechnologie" 345 "Korean Maritime University" 351 "Thrane and Thrane" 355 "Mastervolt" 356 "Fischer Panda Generators" 358 "Victron Energy" 370 "Rolls Royce Marine" 373 "Electronic Design" 374 "Northern Lights" 378 "Glendinning" 381 "B & G" 384 "Rose Point Navigation Systems" 385 "Johnson Outdoors Marine Electronics Inc Geonav" 394 "Capi 2" 396 "Beyond Measure" 400 "Livorsi Marine" 404 "ComNav" 409 "Chetco" 419 "Fusion Electronics" 421 "Standard Horizon" 422 "True Heading" 426 "Egersund Marine Electronics" 427 "em-trak Marine Electronics" 431 "Tohatsu Co, JP" 437 "Digital Yacht" 438 "Comar Systems Limited" 440 "Cummins" 443 "VDO (aka Continental-Corporation)" 451 "Parker Hannifin aka Village Marine Tech" 459 "Alltek Marine Electronics" 460 "SAN GIORGIO S.E.I.N" 466 "Veethree Electronics & Marine" 470 "SI-TEX Marine Electronics" 471 "Sea Cross Marine" 475 "GME aka Standard Communications" 476 "Humminbird Marine Electronics" 478 "Ocean Sat" 481 "Chetco Digital Instruments" 493 "Watcheye" 499 "Lcj Capteurs" 502 "Attwood Marine" 503 "Naviop S.R.L." 504 "Vesper Marine" 510 "Marinesoft" 513 "Simarine" 517 "NoLand Engineering" 518 "Transas USA" 529 "National Instruments Korea" 530 "National Marine Electronics Association" 532 "Onwa Marine" 540 "Webasto" 571 "Marinecraft (South Korea)" 573 "McMurdo Group aka Orolia" 578 "Advansea" 579 "KVH" 580 "San Jose Technology" 583 "Yacht Control" 586 "Suzuki Motor" 591 "US Coast Guard" 595 "Ship Module aka Customware" 600 "Aquatic AV" 605 "Aventics" 606 "Intellian" 612 "SamwonIT" 614 "Arlt Tecnologies" 637 "Bavaria Yachts" 641 "Diverse Yacht Services" 644 "Wema U.S.A dba KUS" 658 "Shenzhen Jiuzhou Himunication" 688 "Rockford" 699 "Harman International" 704 "JL Audio" 708 "Lars Thrane" 715 "Autonnic" 717 "Yacht Devices" 734 "REAP Systems" 735 "AEM Performance Electronics" 739 "LxNav" 741 "Littelfuse, Inc (formerly Carling Technologies)" 743 "DaeMyung" 744 "Woosung" 748 "ISOTTA IFRA srl" 773 "Clarion US" 776 "HMI Systems" 777 "Ocean Signal" 778 "Seakeeper" 781 "Poly Planar" 785 "Fischer Panda DE" 795 "Broyda Industries" 796 "Canadian Automotive" 797 "Tides Marine" 798 "Lumishore" 799 "Still Water Designs and Audio" 802 "BJ Technologies (Beneteau)" 803 "Gill Sensors" 811 "Blue Water Desalination" 815 "FLIR" 824 "Undheim Systems" 826 "Lewmar" 838 "TeamSurv" 844 "Fell Marine" 847 "Oceanvolt" 862 "Prospec" 868 "Data Panel" 890 "L3 Technologies" 894 "Rhodan Marine Systems" 896 "Nexfour Solutions" 905 "ASA Electronics" 909 "Marines Co (South Korea)" 911 "Nautic-on" 917 "Sentinel" 929 "JL Marine Systems" 930 "Ecotronix" 944 "Zontisa Marine" 951 "EXOR International" 962 "Timbolier Industries" 963 "TJC Micro" 968 "Cox Powertrain" 969 "Blue Seas" 981 "Kobelt Manufacturing" 992 "Blue Ocean IOT" 997 "Xenta Systems" 999 "Signal K" 1004 "Ultraflex" 1008 "Lintest SmartBoat" 1011 "Soundmax" 1020 "Team Italia Marine (Onyx Marine Automation s.r.l)" 1021 "Entratech" 1022 "ITC" 1029 "The Marine Guardian" 1047 "Sonic" 1051 "ProNav" 1053 "Vetus Maxwell INC." 1056 "Lithium Pros" 1059 "Boatrax" 1062 "Marol Co ltd" 1065 "CALYPSO Instruments" 1066 "Spot Zero Water" 1069 "Lithionics Battery" 1070 "Quick-teck Electronics" 1075 "Uniden America" 1083 "Nauticoncept" 1084 "Shadow-Caster LED lighting" 1085 "Wet Sounds" 1088 "E-T-A Circuit Breakers" 1092 "Scheiber" 1100 "Smart Yachts International Limited" 1109 "Dockmate" 1114 "Bobs Machine" 1118 "L3Harris ASV" 1119 "Balmar" 1120 "Elettromedia" 1127 "Electromaax" 1140 "Across Oceans Systems" 1145 "Kiwi Yachting" 1150 "BSB Artificial Intelligence" 1151 "Orca Technologies" 1154 "TBS Electronics" 1158 "Technoton Electroics" 1160 "MG Energy Systems" 1169 "Sea Machine Robotics" 1171 "Vista Manufacturing" 1183 "Zipwake" 1186 "Sailmon" 1192 "Airmoniq Pro Kft" 1194 "Sierra Marine" 1200 "Xinuo Information Technology (Xiamen)" 1218 "Septentrio" 1233 "NKE Marine Electronics" 1238 "SuperTrack Aps" 1239 "Honda Electronics" 1245 "Raritan Engineering" 1249 "Integrated Power Solutions AG" 1260 "Interactive Technologies" 1283 "LTG-Tech" 1299 "Energy Solutions (UK)" 1300 "WATT Fuel Cell" 1302 "Pro Mainer" 1305 "Dragonfly Energy" 1306 "Koden Electronics" 1311 "Humphree" 1316 "Hinkley Yachts" 1317 "Global Marine Management GmbH (GMM)" 1320 "Triskel Marine" 1330 "Warwick Control Technologies" 1331 "Dolphin Charger" 1337 "Barnacle Systems" 1348 "Radian IoT" 1353 "Ocean LED Marine" 1359 "BluNav" 1361 "OVA (Nantong Saiyang Electronics Co., Ltd)" 1368 "RAD Propulsion" 1369 "Electric Yacht" 1372 "Elco Motor Yachts" 1384 "Tecnoseal Foundry S.r.l" 1385 "Pro Charging Systems" 1389 "EVEX" 1398 "Gobius Sensor Technology" 1403 "Arco Marine" 1408 "Lenco Marine" 1413 "Naocontrol" 1417 "Revatek" 1438 "Aeolionics" 1439 "PredictWind" 1440 "Egis Mobile Electric" 1445 "Starboard Yacht Group" 1446 "Roswell Marine" 1451 "ePropulsion (Guangdong ePropulsion Technology Ltd.)" 1452 "Micro-Air" 1453 "Vital Battery" 1458 "Ride Controller" 1460 "Tocaro Blue" 1461 "Vanquish Yachts" 1471 "FT Technologies" 1478 "Alps Alpine" 1481 "E-Force Marine" 1482 "CMC Marine" 1483 "Nanjing Sandemarine Information Technology" 1850 "Teleflex Marine (SeaStar Solutions)" 1851 "Raymarine" 1852 "Navionics" 1853 "Japan Radio" 1854 "Northstar Technologies" 1855 "Furuno" 1856 "Trimble" 1857 "Simrad" 1858 "Litton" 1859 "Kvasar" 1860 "MMP" 1861 "Vector Cantech" 1862 "Yamaha Marine" 1863 "Faria Instruments" ;
VAL_ 2583632384 Industry_Code 0 "Global" 1 "Highway" 2 "Agriculture" 3 "Construction" 4 "Marine Industry" 5 "Industrial" ;
VAL_ 2583632384 Operation 0 "Read" 1 "Set" 2 "Reply" ;
VAL_ 2583632640 Manufacturer_Code 69 "ARKS Enterprises" 78 "FW Murphy/Enovation Controls" 80 "Twin Disc" 85 "Kohler Power Systems" 88 "Hemisphere GPS" 135 "Airmar" 137 "Maretron" 140 "Lowrance" 144 "Mercury Marine" 147 "Nautibus Electronic" 148 "Blue Water Data" 154 "Westerbeke" 157 "ISSPRO" 161 "Offshore Systems (UK)" 163 "Evinrude/BRP" 165 "CPAC Systems" 168 "Xantrex Technology" 169 "Marlin Technologies" 172 "Yanmar Marine" 174 "Volvo Penta" 176 "Carling Technologies Inc. (Moritz Aerospace)" 185 "Beede Instruments" 192 "Floscan Instrument" 193 "Nobeltec" 198 "Mystic Valley Communications" 199 "Actia" 201 "Disenos Y Technologia" 211 "Digital Switching Systems" 215 "Xintex/Atena" 224 "EMMI NETWORK" 228 "ZF" 229 "Garmin" 233 "Yacht Monitoring Solutions" 235 "Sailormade Marine Telemetry/Tetra Technology" 243 "Eride" 257 "Honda Motor" 272 "Groco" 273 "Actisense" 274 "Amphenol LTW Technology" 275 "Navico" 283 "Hamilton Jet" 285 "Sea Recovery" 286 "Coelmo SRL Italy" 295 "BEP Marine" 304 "Empir Bus" 305 "NovAtel" 306 "Sleipner Motor" 307 "MBW Technologies" 315 "ICOM" 328 "Qwerty" 329 "Dief" 341 "Boening Automationstechnologie" 345 "Korean Maritime University" 351 "Thrane and Thrane" 355 "Mastervolt" 356 "Fischer Panda Generators" 358 "Victron Energy" 370 "Rolls Royce Marine" 373 "Electronic Design" 374 "Northern Lights" 378 "Glendinning" 381 "B & G" 384 "Rose Point Navigation Systems" 385 "Johnson Outdoors Marine Electronics Inc Geonav" 394 "Capi 2" 396 "Beyond Measure" 400 "Livorsi Marine" 404 "ComNav" 409 "Chetco" 419 "Fusion Electronics" 421 "Standard Horizon" 422 "True Heading" 426 "Egersund Marine Electronics" 427 "em-trak Marine Electronics" 431 "Tohatsu Co, JP" 437 "Digital Yacht" 438 "Comar Systems Limited" 440 "Cummins" 443 "VDO (aka Continental-Corporation)" 451 "Parker Hannifin aka Village Marine Tech" 459 "Alltek Marine Electronics" 460 "SAN GIORGIO S.E.I.N" 466 "Veethree Electronics & Marine" 470 "SI-TEX Marine Electronics" 471 "Sea Cross Marine" 475 "GME aka Standard Communications" 476 "Humminbird Marine Electronics" 478 "Ocean Sat" 481 "Chetco Digital Instruments" 493 "Watcheye" 499 "Lcj Capteurs" 502 "Attwood Marine" 503 "Naviop S.R.L." 504 "Vesper Marine" 510 "Marinesoft" 513 "Simarine" 517 "NoLand Engineering" 518 "Transas USA" 529 "National Instruments Korea" 530 "National Marine Electronics Association" 532 "Onwa Marine" 540 "Webasto" 571 "Marinecraft (South Korea)" 573 "McMurdo Group aka Orolia" 578 "Advansea" 579 "KVH" 580 "San Jose Technology" 583 "Yacht Control" 586 "Suzuki Motor" 591 "US Coast Guard" 595 "Ship Module aka Customware" 600 "Aquatic AV" 605 "Aventics" 606 "Intellian" 612 "SamwonIT" 614 "Arlt Tecnologies" 637 "Bavaria Yachts" 641 "Diverse Yacht Services" 644 "Wema U.S.A dba KUS" 658 "Shenzhen Jiuzhou Himunication" 688 "Rockford" 699 "Harman International" 704 "JL Audio" 708 "Lars Thrane" 715 "Autonnic" 717 "Yacht Devices" 734 "REAP Systems" 735 "AEM Performance Electronics" 739 "LxNav" 741 "Littelfuse, Inc (formerly Carling Technologies)" 743 "DaeMyung" 744 "Woosung" 748 "ISOTTA IFRA srl" 773 "Clarion US" 776 "HMI Systems" 777 "Ocean Signal" 778 "Seakeeper" 781 "Poly Planar" 785 "Fischer Panda DE" 795 "Broyda Industries" 796 "Canadian Automotive" 797 "Tides Marine" 798 "Lumishore" 799 "Still Water Designs and Audio" 802 "BJ Technologies (Beneteau)" 803 "Gill Sensors" 811 "Blue Water Desalination" 815 "FLIR" 824 "Undheim Systems" 826 "Lewmar" 838 "TeamSurv" 844 "Fell Marine" 847 "Oceanvolt" 862 "Prospec" 868 "Data Panel" 890 "L3 Technologies" 894 "Rhodan Marine Systems" 896 "Nexfour Solutions" 905 "ASA Electronics" 909 "Marines Co (South Korea)" 911 "Nautic-on" 917 "Sentinel" 929 "JL Marine Systems" 930 "Ecotronix" 944 "Zontisa Marine" 951 "EXOR International" 962 "Timbolier Industries" 963 "TJC Micro" 968 "Cox Powertrain" 969 "Blue Seas" 981 "Kobelt Manufacturing" 992 "Blue Ocean IOT" 997 "Xenta Systems" 999 "Signal K" 1004 "Ultraflex" 1008 "Lintest SmartBoat" 1011 "Soundmax" 1020 "Team Italia Marine (Onyx Marine Automation s.r.l)" 1021 "Entratech" 1022 "ITC" 1029 "The Marine Guardian" 1047 "Sonic" 1051 "ProNav" 1053 "Vetus Maxwell INC." 1056 "Lithium Pros" 1059 "Boatrax" 1062 "Marol Co ltd" 1065 "CALYPSO Instruments" 1066 "Spot Zero Water" 1069 "Lithionics Battery" 1070 "Quick-teck Electronics" 1075 "Uniden America" 1083 "Nauticoncept" 1084 "Shadow-Caster LED lighting" 1085 "Wet Sounds" 1088 "E-T-A Circuit Breakers" 1092 "Scheiber" 1100 "Smart Yachts International Limited" 1109 "Dockmate" 1114 "Bobs Machine" 1118 "L3Harris ASV" 1119 "Balmar" 1120 "Elettromedia" 1127 "Electromaax" 1140 "Across Oceans Systems" 1145 "Kiwi Yachting" 1150 "BSB Artificial Intelligence" 1151 "Orca Technologies" 1154 "TBS Electronics" 1158 "Technoton Electroics" 1160 "MG Energy Systems" 1169 "Sea Machine Robotics" 1171 "Vista Manufacturing" 1183 "Zipwake" 1186 "Sailmon" 1192 "Airmoniq Pro Kft" 1194 "Sierra Marine" 1200 "Xinuo Information Technology (Xiamen)" 1218 "Septentrio" 1233 "NKE Marine Electronics" 1238 "SuperTrack Aps" 1239 "Honda Electronics" 1245 "Raritan Engineering" 1249 "Integrated Power Solutions AG" 1260 "Interactive Technologies" 1283 "LTG-Tech" 1299 "Energy Solutions (UK)" 1300 "WATT Fuel Cell" 1302 "Pro Mainer" 1305 "Dragonfly Energy" 1306 "Koden Electronics" 1311 "Humphree" 1316 "Hinkley Yachts" 1317 "Global Marine Management GmbH (GMM)" 1320 "Triskel Marine" 1330 "Warwick Control Technologies" 1331 "Dolphin Charger" 1337 "Barnacle Systems" 1348 "Radian IoT" 1353 "Ocean LED Marine" 1359 "BluNav" 1361 "OVA (Nantong Saiyang Electronics Co., Ltd)" 1368 "RAD Propulsion" 1369 "Electric Yacht" 1372 "Elco Motor Yachts" 1384 "Tecnoseal Foundry S.r.l" 1385 "Pro Charging Systems" 1389 "EVEX" 1398 "Gobius Sensor Technology" 1403 "Arco Marine" 1408 "Lenco Marine" 1413 "Naocontrol" 1417 "Revatek" 1438 "Aeolionics" 1439 "PredictWind" 1440 "Egis Mobile Electric" 1445 "Starboard Yacht Group" 1446 "Roswell Marine" 1451 "ePropulsion (Guangdong ePropulsion Technology Ltd.)" 1452 "Micro-Air" 1453 "Vital Battery" 1458 "Ride Controller" 1460 "Tocaro Blue" 1461 "Vanquish Yachts" 1471 "FT Technologies" 1478 "Alps Alpine" 1481 "E-Force Marine" 1482 "CMC Marine" 1483 "Nanjing Sandemarine Information Technology" 1850 "Teleflex Marine (SeaStar Solutions)" 1851 "Raymarine" 1852 "Navionics" 1853 "Japan Radio" 1854 "Northstar Technologies" 1855 "Furuno" 1856 "Trimble" 1857 "Simrad" 1858 "Litton" 1859 "Kvasar" 1860 "MMP" 1861 "Vector Cantech" 1862 "Yamaha Marine" 1863 "Faria Instruments" ;
VAL_ 2583632640 Industry_Code 0 "Global" 1 "Highway" 2 "Agriculture" 3 "Construction" 4 "Marine Industry" 5 "Industrial" ;
VAL_ 2583632640 Manufacturer_Code 69 "ARKS Enterprises" 78 "FW Murphy/Enovation Controls" 80 "Twin Disc" 85 "Kohler Power Systems" 88 "Hemisphere GPS" 135 "Airmar" 137 "Maretron" 140 "Lowrance" 144 "Mercury Marine" 147 "Nautibus Electronic" 148 "Blue Water Data" 154 "Westerbeke" 157 "ISSPRO" 161 "Offshore Systems (UK)" 163 "Evinrude/BRP" 165 "CPAC Systems" 168 "Xantrex Technology" 169 "Marlin Technologies" 172 "Yanmar Marine" 174 "Volvo Penta" 176 "Carling Technologies Inc. (Moritz Aerospace)" 185 "Beede Instruments" 192 "Floscan Instrument" 193 "Nobeltec" 198 "Mystic Valley Communications" 199 "Actia" 201 "Disenos Y Technologia" 211 "Digital Switching Systems" 215 "Xintex/Atena" 224 "EMMI NETWORK" 228 "ZF" 229 "Garmin" 233 "Yacht Monitoring Solutions" 235 "Sailormade Marine Telemetry/Tetra Technology" 243 "Eride" 257 "Honda Motor" 272 "Groco" 273 "Actisense" 274 "Amphenol LTW Technology" 275 "Navico" 283 "Hamilton Jet" 285 "Sea Recovery" 286 "Coelmo SRL Italy" 295 "BEP Marine" 304 "Empir Bus" 305 "NovAtel" 306 "Sleipner Motor" 307 "MBW Technologies" 315 "ICOM" 328 "Qwerty" 329 "Dief" 341 "Boening Automationstechnologie" 345 "Korean Maritime University" 351 "Thrane and Thrane" 355 "Mastervolt" 356 "Fischer Panda Generators" 358 "Victron Energy" 370 "Rolls Royce Marine" 373 "Electronic Design" 374 "Northern Lights" 378 "Glendinning" 381 "B & G" 384 "Rose Point Navigation Systems" 385 "Johnson Outdoors Marine Electronics Inc Geonav" 394 "Capi 2" 396 "Beyond Measure" 400 "Livorsi Marine" 404 "ComNav" 409 "Chetco" 419 "Fusion Electronics" 421 "Standard Horizon" 422 "True Heading" 426 "Egersund Marine Electronics" 427 "em-trak Marine Electronics" 431 "Tohatsu Co, JP" 437 "Digital Yacht" 438 "Comar Systems Limited" 440 "Cummins" 443 "VDO (aka Continental-Corporation)" 451 "Parker Hannifin aka Village Marine Tech" 459 "Alltek Marine Electronics" 460 "SAN GIORGIO S.E.I.N" 466 "Veethree Electronics & Marine" 470 "SI-TEX Marine Electronics" 471 "Sea Cross Marine" 475 "GME aka Standard Communications" 476 "Humminbird Marine Electronics" 478 "Ocean Sat" 481 "Chetco Digital Instruments" 493 "Watcheye" 499 "Lcj Capteurs" 502 "Attwood Marine" 503 "Naviop S.R.L." 504 "Vesper Marine" 510 "Marinesoft" 513 "Simarine" 517 "NoLand Engineering" 518 "Transas USA" 529 "National Instruments Korea" 530 "National Marine Electronics Association" 532 "Onwa Marine" 540 "Webasto" 571 "Marinecraft (South Korea)" 573 "McMurdo Group aka Orolia" 578 "Advansea" 579 "KVH" 580 "San Jose Technology" 583 "Yacht Control" 586 "Suzuki Motor" 591 "US Coast Guard" 595 "Ship Module aka Customware" 600 "Aquatic AV" 605 "Aventics" 606 "Intellian" 612 "SamwonIT" 614 "Arlt Tecnologies" 637 "Bavaria Yachts" 641 "Diverse Yacht Services" 644 "Wema U.S.A dba KUS" 658 "Shenzhen Jiuzhou Himunication" 688 "Rockford" 699 "Harman International" 704 "JL Audio" 708 "Lars Thrane" 715 "Autonnic" 717 "Yacht Devices" 734 "REAP Systems" 735 "AEM Performance Electronics" 739 "LxNav" 741 "Littelfuse, Inc (formerly Carling Technologies)" 743 "DaeMyung" 744 "Woosung" 748 "ISOTTA IFRA srl" 773 "Clarion US" 776 "HMI Systems" 777 "Ocean Signal" 778 "Seakeeper" 781 "Poly Planar" 785 "Fischer Panda DE" 795 "Broyda Industries" 796 "Canadian Automotive" 797 "Tides Marine" 798 "Lumishore" 799 "Still Water Designs and Audio" 802 "BJ Technologies (Beneteau)" 803 "Gill Sensors" 811 "Blue Water Desalination" 815 "FLIR" 824 "Undheim Systems" 826 "Lewmar" 838 "TeamSurv" 844 "Fell Marine" 847 "Oceanvolt" 862 "Prospec" 868 "Data Panel" 890 "L3 Technologies" 894 "Rhodan Marine Systems" 896 "Nexfour Solutions" 905 "ASA Electronics" 909 "Marines Co (South Korea)" 911 "Nautic-on" 917 "Sentinel" 929 "JL Marine Systems" 930 "Ecotronix" 944 "Zontisa Marine" 951 "EXOR International" 962 "Timbolier Industries" 963 "TJC Micro" 968 "Cox Powertrain" 969 "Blue Seas" 981 "Kobelt Manufacturing" 992 "Blue Ocean IOT" 997 "Xenta Systems" 999 "Signal K" 1004 "Ultraflex" 1008 "Lintest SmartBoat" 1011 "Soundmax" 1020 "Team Italia Marine (Onyx Marine Automation s.r.l)" 1021 "Entratech" 1022 "ITC" 1029 "The Marine Guardian" 1047 "Sonic" 1051 "ProNav" 1053 "Vetus Maxwell INC." 1056 "Lithium Pros" 1059 "Boatrax" 1062 "Marol Co ltd" 1065 "CALYPSO Instruments" 1066 "Spot Zero Water" 1069 "Lithionics Battery" 1070 "Quick-teck Electronics" 1075 "Uniden America" 1083 "Nauticoncept" 1084 "Shadow-Caster LED lighting" 1085 "Wet Sounds" 1088 "E-T-A Circuit Breakers" 1092 "Scheiber" 1100 "Smart Yachts International Limited" 1109 "Dockmate" 1114 "Bobs Machine" 1118 "L3Harris ASV" 1119 "Balmar" 1120 "Elettromedia" 1127 "Electromaax" 1140 "Across Oceans Systems" 1145 "Kiwi Yachting" 1150 "BSB Artificial Intelligence" 1151 "Orca Technologies" 1154 "TBS Electronics" 1158 "Technoton Electroics" 1160 "MG Energy Systems" 1169 "Sea Machine Robotics" 1171 "Vista Manufacturing" 1183 "Zipwake" 1186 "Sailmon" 1192 "Airmoniq Pro Kft" 1194 "Sierra Marine" 1200 "Xinuo Information Technology (Xiamen)" 1218 "Septentrio" 1233 "NKE Marine Electronics" 1238 "SuperTrack Aps" 1239 "Honda Electronics" 1245 "Raritan Engineering" 1249 "Integrated Power Solutions AG" 1260 "Interactive Technologies" 1283 "LTG-Tech" 1299 "Energy Solutions (UK)" 1300 "WATT Fuel Cell" 1302 "Pro Mainer" 1305 "Dragonfly Energy" 1306 "Koden Electronics" 1311 "Humphree" 1316 "Hinkley Yachts" 1317 "Global Marine Management GmbH (GMM)" 1320 "Triskel Marine" 1330 "Warwick Control Technologies" 1331 "Dolphin Charger" 1337 "Barnacle Systems" 1348 "Radian IoT" 1353 "Ocean LED Marine" 1359 "BluNav" 1361 "OVA (Nantong Saiyang Electronics Co., Ltd)" 1368 "RAD Propulsion" 1369 "Electric Yacht" 1372 "Elco Motor Yachts" 1384 "Tecnoseal Foundry S.r.l" 1385 "Pro Charging Systems" 1389 "EVEX" 1398 "Gobius Sensor Technology" 1403 "Arco Marine" 1408 "Lenco Marine" 1413 "Naocontrol" 1417 "Revatek" 1438 "Aeolionics" 1439 "PredictWind" 1440 "Egis Mobile Electric" 1445 "Starboard Yacht Group" 1446 "Roswell Marine" 1451 "ePropulsion (Guangdong ePropulsion Technology Ltd.)" 1452 "Micro-Air" 1453 "Vital Battery" 1458 "Ride Controller" 1460 "Tocaro Blue" 1461 "Vanquish Yachts" 1471 "FT Technologies" 1478 "Alps Alpine" 1481 "E-Force Marine" 1482 "CMC Marine" 1483 "Nanjing Sandemarine Information Technology" 1850 "Teleflex Marine (SeaStar Solutions)" 1851 "Raymarine" 1852 "Navionics" 1853 "Japan Radio" 1854 "Northstar Technologies" 1855 "Furuno" 1856 "Trimble" 1857 "Simrad" 1858 "Litton" 1859 "Kvasar" 1860 "MMP" 1861 "Vector Cantech" 1862 "Yamaha Marine" 1863 "Faria Instruments" ;
VAL_ 2583632640 Industry_Code 0 "Global" 1 "Highway" 2 "Agriculture" 3 "Construction" 4 "Marine Industry" 5 "Industrial" ;
VAL_ 2583632640 Manufacturer_Code 69 "ARKS Enterprises" 78 "FW Murphy/Enovation Controls" 80 "Twin Disc" 85 "Kohler Power Systems" 88 "Hemisphere GPS" 135 "Airmar" 137 "Maretron" 140 "Lowrance" 144 "Mercury Marine" 147 "Nautibus Electronic" 148 "Blue Water Data" 154 "Westerbeke" 157 "ISSPRO" 161 "Offshore Systems (UK)" 163 "Evinrude/BRP" 165 "CPAC Systems" 168 "Xantrex Technology" 169 "Marlin Technologies" 172 "Yanmar Marine" 174 "Volvo Penta" 176 "Carling Technologies Inc. (Moritz Aerospace)" 185 "Beede Instruments" 192 "Floscan Instrument" 193 "Nobeltec" 198 "Mystic Valley Communications" 199 "Actia" 201 "Disenos Y Technologia" 211 "Digital Switching Systems" 215 "Xintex/Atena" 224 "EMMI NETWORK" 228 "ZF" 229 "Garmin" 233 "Yacht Monitoring Solutions" 235 "Sailormade Marine Telemetry/Tetra Technology" 243 "Eride" 257 "Honda Motor" 272 "Groco" 273 "Actisense" 274 "Amphenol LTW Technology" 275 "Navico" 283 "Hamilton Jet" 285 "Sea Recovery" 286 "Coelmo SRL Italy" 295 "BEP Marine" 304 "Empir Bus" 305 "NovAtel" 306 "Sleipner Motor" 307 "MBW Technologies" 315 "ICOM" 328 "Qwerty" 329 "Dief" 341 "Boening Automationstechnologie" 345 "Korean Maritime University" 351 "Thrane and Thrane" 355 "Mastervolt" 356 "Fischer Panda Generators" 358 "Victron Energy" 370 "Rolls Royce Marine" 373 "Electronic Design" 374 "Northern Lights" 378 "Glendinning" 381 "B & G" 384 "Rose Point Navigation Systems" 385 "Johnson Outdoors Marine Electronics Inc Geonav" 394 "Capi 2" 396 "Beyond Measure" 400 "Livorsi Marine" 404 "ComNav" 409 "Chetco" 419 "Fusion Electronics" 421 "Standard Horizon" 422 "True Heading" 426 "Egersund Marine Electronics" 427 "em-trak Marine Electronics" 431 "Tohatsu Co, JP" 437 "Digital Yacht" 438 "Comar Systems Limited" 440 "Cummins" 443 "VDO (aka Continental-Corporation)" 451 "Parker Hannifin aka Village Marine Tech" 459 "Alltek Marine Electronics" 460 "SAN GIORGIO S.E.I.N" 466 "Veethree Electronics & Marine" 470 "SI-TEX Marine Electronics" 471 "Sea Cross Marine" 475 "GME aka Standard Communications" 476 "Humminbird Marine Electronics" 478 "Ocean Sat" 481 "Chetco Digital Instruments" 493 "Watcheye" 499 "Lcj Capteurs" 502 "Attwood Marine" 503 "Naviop S.R.L." 504 "Vesper Marine" 510 "Marinesoft" 513 "Simarine" 517 "NoLand Engineering" 518 "Transas USA" 529 "National Instruments Korea" 530 "National Marine Electronics Association" 532 "Onwa Marine" 540 "Webasto" 571 "Marinecraft (South Korea)" 573 "McMurdo Group aka Orolia" 578 "Advansea" 579 "KVH" 580 "San Jose Technology" 583 "Yacht Control" 586 "Suzuki Motor" 591 "US Coast Guard" 595 "Ship Module aka Customware" 600 "Aquatic AV" 605 "Aventics" 606 "Intellian" 612 "SamwonIT" 614 "Arlt Tecnologies" 637 "Bavaria Yachts" 641 "Diverse Yacht Services" 644 "Wema U.S.A dba KUS" 658 "Shenzhen Jiuzhou Himunication" 688 "Rockford" 699 "Harman International" 704 "JL Audio" 708 "Lars Thrane" 715 "Autonnic" 717 "Yacht Devices" 734 "REAP Systems" 735 "AEM Performance Electronics" 739 "LxNav" 741 "Littelfuse, Inc (formerly Carling Technologies)" 743 "DaeMyung" 744 "Woosung" 748 "ISOTTA IFRA srl" 773 "Clarion US" 776 "HMI Systems" 777 "Ocean Signal" 778 "Seakeeper" 781 "Poly Planar" 785 "Fischer Panda DE" 795 "Broyda Industries" 796 "Canadian Automotive" 797 "Tides Marine" 798 "Lumishore" 799 "Still Water Designs and Audio" 802 "BJ Technologies (Beneteau)" 803 "Gill Sensors" 811 "Blue Water Desalination" 815 "FLIR" 824 "Undheim Systems" 826 "Lewmar" 838 "TeamSurv" 844 "Fell Marine" 847 "Oceanvolt" 862 "Prospec" 868 "Data Panel" 890 "L3 Technologies" 894 "Rhodan Marine Systems" 896 "Nexfour Solutions" 905 "ASA Electronics" 909 "Marines Co (South Korea)" 911 "Nautic-on" 917 "Sentinel" 929 "JL Marine Systems" 930 "Ecotronix" 944 "Zontisa Marine" 951 "EXOR International" 962 "Timbolier Industries" 963 "TJC Micro" 968 "Cox Powertrain" 969 "Blue Seas" 981 "Kobelt Manufacturing" 992 "Blue Ocean IOT" 997 "Xenta Systems" 999 "Signal K" 1004 "Ultraflex" 1008 "Lintest SmartBoat" 1011 "Soundmax" 1020 "Team Italia Marine (Onyx Marine Automation s.r.l)" 1021 "Entratech" 1022 "ITC" 1029 "The Marine Guardian" 1047 "Sonic" 1051 "ProNav" 1053 "Vetus Maxwell INC." 1056 "Lithium Pros" 1059 "Boatrax" 1062 "Marol Co ltd" 1065 "CALYPSO Instruments" 1066 "Spot Zero Water" 1069 "Lithionics Battery" 1070 "Quick-teck Electronics" 1075 "Uniden America" 1083 "Nauticoncept" 1084 "Shadow-Caster LED lighting" 1085 "Wet Sounds" 1088 "E-T-A Circuit Breakers" 1092 "Scheiber" 1100 "Smart Yachts International Limited" 1109 "Dockmate" 1114 "Bobs Machine" 1118 "L3Harris ASV" 1119 "Balmar" 1120 "Elettromedia" 1127 "Electromaax" 1140 "Across Oceans Systems" 1145 "Kiwi Yachting" 1150 "BSB Artificial Intelligence" 1151 "Orca Technologies" 1154 "TBS Electronics" 1158 "Technoton Electroics" 1160 "MG Energy Systems" 1169 "Sea Machine Robotics" 1171 "Vista Manufacturing" 1183 "Zipwake" 1186 "Sailmon" 1192 "Airmoniq Pro Kft" 1194 "Sierra Marine" 1200 "Xinuo Information Technology (Xiamen)" 1218 "Septentrio" 1233 "NKE Marine Electronics" 1238 "SuperTrack Aps" 1239 "Honda Electronics" 1245 "Raritan Engineering" 1249 "Integrated Power Solutions AG" 1260 "Interactive Technologies" 1283 "LTG-Tech" 1299 "Energy Solutions (UK)" 1300 "WATT Fuel Cell" 1302 "Pro Mainer" 1305 "Dragonfly Energy" 1306 "Koden Electronics" 1311 "Humphree" 1316 "Hinkley Yachts" 1317 "Global Marine Management GmbH (GMM)" 1320 "Triskel Marine" 1330 "Warwick Control Technologies" 1331 "Dolphin Charger" 1337 "Barnacle Systems" 1348 "Radian IoT" 1353 "Ocean LED Marine" 1359 "BluNav" 1361 "OVA (Nantong Saiyang Electronics Co., Ltd)" 1368 "RAD Propulsion" 1369 "Electric Yacht" 1372 "Elco Motor Yachts" 1384 "Tecnoseal Foundry S.r.l" 1385 "Pro Charging Systems" 1389 "EVEX" 1398 "Gobius Sensor Technology" 1403 "Arco Marine" 1408 "Lenco Marine" 1413 "Naocontrol" 1417 "Revatek" 1438 "Aeolionics" 1439 "PredictWind" 1440 "Egis Mobile Electric" 1445 "Starboard Yacht Group" 1446 "Roswell Marine" 1451 "ePropulsion (Guangdong ePropulsion Technology Ltd.)" 1452 "Micro-Air" 1453 "Vital Battery" 1458 "Ride Controller" 1460 "Tocaro Blue" 1461 "Vanquish Yachts" 1471 "FT Technologies" 1478 "Alps Alpine" 1481 "E-Force Marine" 1482 "CMC Marine" 1483 "Nanjing Sandemarine Information Technology" 1850 "Teleflex Marine (SeaStar Solutions)" 1851 "Raymarine" 1852 "Navionics" 1853 "Japan Radio" 1854 "Northstar Technologies" 1855 "Furuno" 1856 "Trimble" 1857 "Simrad" 1858 "Litton" 1859 "Kvasar" 1860 "MMP" 1861 "Vector Cantech" 1862 "Yamaha Marine" 1863 "Faria Instruments" ;
VAL_ 2583632640 Industry_Code 0 "Global" 1 "Highway" 2 "Agriculture" 3 "Construction" 4 "Marine Industry" 5 "Industrial" ;
VAL_ 2583632896 Manufacturer_Code 69 "ARKS Enterprises" 78 "FW Murphy/Enovation Controls" 80 "Twin Disc" 85 "Kohler Power Systems" 88 "Hemisphere GPS" 135 "Airmar" 137 "Maretron" 140 "Lowrance" 144 "Mercury Marine" 147 "Nautibus Electronic" 148 "Blue Water Data" 154 "Westerbeke" 157 "ISSPRO" 161 "Offshore Systems (UK)" 163 "Evinrude/BRP" 165 "CPAC Systems" 168 "Xantrex Technology" 169 "Marlin Technologies" 172 "Yanmar Marine" 174 "Volvo Penta" 176 "Carling Technologies Inc. (Moritz Aerospace)" 185 "Beede Instruments" 192 "Floscan Instrument" 193 "Nobeltec" 198 "Mystic Valley Communications" 199 "Actia" 201 "Disenos Y Technologia" 211 "Digital Switching Systems" 215 "Xintex/Atena" 224 "EMMI NETWORK" 228 "ZF" 229 "Garmin" 233 "Yacht Monitoring Solutions" 235 "Sailormade Marine Telemetry/Tetra Technology" 243 "Eride" 257 "Honda Motor" 272 "Groco" 273 "Actisense" 274 "Amphenol LTW Technology" 275 "Navico" 283 "Hamilton Jet" 285 "Sea Recovery" 286 "Coelmo SRL Italy" 295 "BEP Marine" 304 "Empir Bus" 305 "NovAtel" 306 "Sleipner Motor" 307 "MBW Technologies" 315 "ICOM" 328 "Qwerty" 329 "Dief" 341 "Boening Automationstechnologie" 345 "Korean Maritime University" 351 "Thrane and Thrane" 355 "Mastervolt" 356 "Fischer Panda Generators" 358 "Victron Energy" 370 "Rolls Royce Marine" 373 "Electronic Design" 374 "Northern Lights" 378 "Glendinning" 381 "B & G" 384 "Rose Point Navigation Systems" 385 "Johnson Outdoors Marine Electronics Inc Geonav" 394 "Capi 2" 396 "Beyond Measure" 400 "Livorsi Marine" 404 "ComNav" 409 "Chetco" 419 "Fusion Electronics" 421 "Standard Horizon" 422 "True Heading" 426 "Egersund Marine Electronics" 427 "em-trak Marine Electronics" 431 "Tohatsu Co, JP" 437 "Digital Yacht" 438 "Comar Systems Limited" 440 "Cummins" 443 "VDO (aka Continental-Corporation)" 451 "Parker Hannifin aka Village Marine Tech" 459 "Alltek Marine Electronics" 460 "SAN GIORGIO S.E.I.N" 466 "Veethree Electronics & Marine" 470 "SI-TEX Marine Electronics" 471 "Sea Cross Marine" 475 "GME aka Standard Communications" 476 "Humminbird Marine Electronics" 478 "Ocean Sat" 481 "Chetco Digital Instruments" 493 "Watcheye" 499 "Lcj Capteurs" 502 "Attwood Marine" 503 "Naviop S.R.L." 504 "Vesper Marine" 510 "Marinesoft" 513 "Simarine" 517 "NoLand Engineering" 518 "Transas USA" 529 "National Instruments Korea" 530 "National Marine Electronics Association" 532 "Onwa Marine" 540 "Webasto" 571 "Marinecraft (South Korea)" 573 "McMurdo Group aka Orolia" 578 "Advansea" 579 "KVH" 580 "San Jose Technology" 583 "Yacht Control" 586 "Suzuki Motor" 591 "US Coast Guard" 595 "Ship Module aka Customware" 600 "Aquatic AV" 605 "Aventics" 606 "Intellian" 612 "SamwonIT" 614 "Arlt Tecnologies" 637 "Bavaria Yachts" 641 "Diverse Yacht Services" 644 "Wema U.S.A dba KUS" 658 "Shenzhen Jiuzhou Himunication" 688 "Rockford" 699 "Harman International" 704 "JL Audio" 708 "Lars Thrane" 715 "Autonnic" 717 "Yacht Devices" 734 "REAP Systems" 735 "AEM Performance Electronics" 739 "LxNav" 741 "Littelfuse, Inc (formerly Carling Technologies)" 743 "DaeMyung" 744 "Woosung" 748 "ISOTTA IFRA srl" 773 "Clarion US" 776 "HMI Systems" 777 "Ocean Signal" 778 "Seakeeper" 781 "Poly Planar" 785 "Fischer Panda DE" 795 "Broyda Industries" 796 "Canadian Automotive" 797 "Tides Marine" 798 "Lumishore" 799 "Still Water Designs and Audio" 802 "BJ Technologies (Beneteau)" 803 "Gill Sensors" 811 "Blue Water Desalination" 815 "FLIR" 824 "Undheim Systems" 826 "Lewmar" 838 "TeamSurv" 844 "Fell Marine" 847 "Oceanvolt" 862 "Prospec" 868 "Data Panel" 890 "L3 Technologies" 894 "Rhodan Marine Systems" 896 "Nexfour Solutions" 905 "ASA Electronics" 909 "Marines Co (South Korea)" 911 "Nautic-on" 917 "Sentinel" 929 "JL Marine Systems" 930 "Ecotronix" 944 "Zontisa Marine" 951 "EXOR International" 962 "Timbolier Industries" 963 "TJC Micro" 968 "Cox Powertrain" 969 "Blue Seas" 981 "Kobelt Manufacturing" 992 "Blue Ocean IOT" 997 "Xenta Systems" 999 "Signal K" 1004 "Ultraflex" 1008 "Lintest SmartBoat" 1011 "Soundmax" 1020 "Team Italia Marine (Onyx Marine Automation s.r.l)" 1021 "Entratech" 1022 "ITC" 1029 "The Marine Guardian" 1047 "Sonic" 1051 "ProNav" 1053 "Vetus Maxwell INC." 1056 "Lithium Pros" 1059 "Boatrax" 1062 "Marol Co ltd" 1065 "CALYPSO Instruments" 1066 "Spot Zero Water" 1069 "Lithionics Battery" 1070 "Quick-teck Electronics" 1075 "Uniden America" 1083 "Nauticoncept" 1084 "Shadow-Caster LED lighting" 1085 "Wet Sounds" 1088 "E-T-A Circuit Breakers" 1092 "Scheiber" 1100 "Smart Yachts International Limited" 1109 "Dockmate" 1114 "Bobs Machine" 1118 "L3Harris ASV" 1119 "Balmar" 1120 "Elettromedia" 1127 "Electromaax" 1140 "Across Oceans Systems" 1145 "Kiwi Yachting" 1150 "BSB Artificial Intelligence" 1151 "Orca Technologies" 1154 "TBS Electronics" 1158 "Technoton Electroics" 1160 "MG Energy Systems" 1169 "Sea Machine Robotics" 1171 "Vista Manufacturing" 1183 "Zipwake" 1186 "Sailmon" 1192 "Airmoniq Pro Kft" 1194 "Sierra Marine" 1200 "Xinuo Information Technology (Xiamen)" 1218 "Septentrio" 1233 "NKE Marine Electronics" 1238 "SuperTrack Aps" 1239 "Honda Electronics" 1245 "Raritan Engineering" 1249 "Integrated Power Solutions AG" 1260 "Interactive Technologies" 1283 "LTG-Tech" 1299 "Energy Solutions (UK)" 1300 "WATT Fuel Cell" 1302 "Pro Mainer" 1305 "Dragonfly Energy" 1306 "Koden Electronics" 1311 "Humphree" 1316 "Hinkley Yachts" 1317 "Global Marine Management GmbH (GMM)" 1320 "Triskel Marine" 1330 "Warwick Control Technologies" 1331 "Dolphin Charger" 1337 "Barnacle Systems" 1348 "Radian IoT" 1353 "Ocean LED Marine" 1359 "BluNav" 1361 "OVA (Nantong Saiyang Electronics Co., Ltd)" 1368 "RAD Propulsion" 1369 "Electric Yacht" 1372 "Elco Motor Yachts" 1384 "Tecnoseal Foundry S.r.l" 1385 "Pro Charging Systems" 1389 "EVEX" 1398 "Gobius Sensor Technology" 1403 "Arco Marine" 1408 "Lenco Marine" 1413 "Naocontrol" 1417 "Revatek" 1438 "Aeolionics" 1439 "PredictWind" 1440 "Egis Mobile Electric" 1445 "Starboard Yacht Group" 1446 "Roswell Marine" 1451 "ePropulsion (Guangdong ePropulsion Technology Ltd.)" 1452 "Micro-Air" 1453 "Vital Battery" 1458 "Ride Controller" 1460 "Tocaro Blue" 1461 "Vanquish Yachts" 1471 "FT Technologies" 1478 "Alps Alpine" 1481 "E-Force Marine" 1482 "CMC Marine" 1483 "Nanjing Sandemarine Information Technology" 1850 "Teleflex Marine (SeaStar Solutions)" 1851 "Raymarine" 1852 "Navionics" 1853 "Japan Radio" 1854 "Northstar Technologies" 1855 "Furuno" 1856 "Trimble" 1857 "Simrad" 1858 "Litton" 1859 "Kvasar" 1860 "MMP" 1861 "Vector Cantech" 1862 "Yamaha Marine" 1863 "Faria Instruments" ;
VAL_ 2583632896 Industry_Code 0 "Global" 1 "Highway" 2 "Agriculture" 3 "Construction" 4 "Marine Industry" 5 "Industrial" ;
VAL_ 2583633152 Manufacturer_Code 69 "ARKS Enterprises" 78 "FW Murphy/Enovation Controls" 80 "Twin Disc" 85 "Kohler Power Systems" 88 "Hemisphere GPS" 135 "Airmar" 137 "Maretron" 140 "Lowrance" 144 "Mercury Marine" 147 "Nautibus Electronic" 148 "Blue Water Data" 154 "Westerbeke" 157 "ISSPRO" 161 "Offshore Systems (UK)" 163 "Evinrude/BRP" 165 "CPAC Systems" 168 "Xantrex Technology" 169 "Marlin Technologies" 172 "Yanmar Marine" 174 "Volvo Penta" 176 "Carling Technologies Inc. (Moritz Aerospace)" 185 "Beede Instruments" 192 "Floscan Instrument" 193 "Nobeltec" 198 "Mystic Valley Communications" 199 "Actia" 201 "Disenos Y Technologia" 211 "Digital Switching Systems" 215 "Xintex/Atena" 224 "EMMI NETWORK" 228 "ZF" 229 "Garmin" 233 "Yacht Monitoring Solutions" 235 "Sailormade Marine Telemetry/Tetra Technology" 243 "Eride" 257 "Honda Motor" 272 "Groco" 273 "Actisense" 274 "Amphenol LTW Technology" 275 "Navico" 283 "Hamilton Jet" 285 "Sea Recovery" 286 "Coelmo SRL Italy" 295 "BEP Marine" 304 "Empir Bus" 305 "NovAtel" 306 "Sleipner Motor" 307 "MBW Technologies" 315 "ICOM" 328 "Qwerty" 329 "Dief" 341 "Boening Automationstechnologie" 345 "Korean Maritime University" 351 "Thrane and Thrane" 355 "Mastervolt" 356 "Fischer Panda Generators" 358 "Victron Energy" 370 "Rolls Royce Marine" 373 "Electronic Design" 374 "Northern Lights" 378 "Glendinning" 381 "B & G" 384 "Rose Point Navigation Systems" 385 "Johnson Outdoors Marine Electronics Inc Geonav" 394 "Capi 2" 396 "Beyond Measure" 400 "Livorsi Marine" 404 "ComNav" 409 "Chetco" 419 "Fusion Electronics" 421 "Standard Horizon" 422 "True Heading" 426 "Egersund Marine Electronics" 427 "em-trak Marine Electronics" 431 "Tohatsu Co, JP" 437 "Digital Yacht" 438 "Comar Systems Limited" 440 "Cummins" 443 "VDO (aka Continental-Corporation)" 451 "Parker Hannifin aka Village Marine Tech" 459 "Alltek Marine Electronics" 460 "SAN GIORGIO S.E.I.N" 466 "Veethree Electronics & Marine" 470 "SI-TEX Marine Electronics" 471 "Sea Cross Marine" 475 "GME aka Standard Communications" 476 "Humminbird Marine Electronics" 478 "Ocean Sat" 481 "Chetco Digital Instruments" 493 "Watcheye" 499 "Lcj Capteurs" 502 "Attwood Marine" 503 "Naviop S.R.L." 504 "Vesper Marine" 510 "Marinesoft" 513 "Simarine" 517 "NoLand Engineering" 518 "Transas USA" 529 "National Instruments Korea" 530 "National Marine Electronics Association" 532 "Onwa Marine" 540 "Webasto" 571 "Marinecraft (South Korea)" 573 "McMurdo Group aka Orolia" 578 "Advansea" 579 "KVH" 580 "San Jose Technology" 583 "Yacht Control" 586 "Suzuki Motor" 591 "US Coast Guard" 595 "Ship Module aka Customware" 600 "Aquatic AV" 605 "Aventics" 606 "Intellian" 612 "SamwonIT" 614 "Arlt Tecnologies" 637 "Bavaria Yachts" 641 "Diverse Yacht Services" 644 "Wema U.S.A dba KUS" 658 "Shenzhen Jiuzhou Himunication" 688 "Rockford" 699 "Harman International" 704 "JL Audio" 708 "Lars Thrane" 715 "Autonnic" 717 "Yacht Devices" 734 "REAP Systems" 735 "AEM Performance Electronics" 739 "LxNav" 741 "Littelfuse, Inc (formerly Carling Technologies)" 743 "DaeMyung" 744 "Woosung" 748 "ISOTTA IFRA srl" 773 "Clarion US" 776 "HMI Systems" 777 "Ocean Signal" 778 "Seakeeper" 781 "Poly Planar" 785 "Fischer Panda DE" 795 "Broyda Industries" 796 "Canadian Automotive" 797 "Tides Marine" 798 "Lumishore" 799 "Still Water Designs and Audio" 802 "BJ Technologies (Beneteau)" 803 "Gill Sensors" 811 "Blue Water Desalination" 815 "FLIR" 824 "Undheim Systems" 826 "Lewmar" 838 "TeamSurv" 844 "Fell Marine" 847 "Oceanvolt" 862 "Prospec" 868 "Data Panel" 890 "L3 Technologies" 894 "Rhodan Marine Systems" 896 "Nexfour Solutions" 905 "ASA Electronics" 909 "Marines Co (South Korea)" 911 "Nautic-on" 917 "Sentinel" 929 "JL Marine Systems" 930 "Ecotronix" 944 "Zontisa Marine" 951 "EXOR International" 962 "Timbolier Industries" 963 "TJC Micro" 968 "Cox Powertrain" 969 "Blue Seas" 981 "Kobelt Manufacturing" 992 "Blue Ocean IOT" 997 "Xenta Systems" 999 "Signal K" 1004 "Ultraflex" 1008 "Lintest SmartBoat" 1011 "Soundmax" 1020 "Team Italia Marine (Onyx Marine Automation s.r.l)" 1021 "Entratech" 1022 "ITC" 1029 "The Marine Guardian" 1047 "Sonic" 1051 "ProNav" 1053 "Vetus Maxwell INC." 1056 "Lithium Pros" 1059 "Boatrax" 1062 "Marol Co ltd" 1065 "CALYPSO Instruments" 1066 "Spot Zero Water" 1069 "Lithionics Battery" 1070 "Quick-teck Electronics" 1075 "Uniden America" 1083 "Nauticoncept" 1084 "Shadow-Caster LED lighting" 1085 "Wet Sounds" 1088 "E-T-A Circuit Breakers" 1092 "Scheiber" 1100 "Smart Yachts International Limited" 1109 "Dockmate" 1114 "Bobs Machine" 1118 "L3Harris ASV" 1119 "Balmar" 1120 "Elettromedia" 1127 "Electromaax" 1140 "Across Oceans Systems" 1145 "Kiwi Yachting" 1150 "BSB Artificial Intelligence" 1151 "Orca Technologies" 1154 "TBS Electronics" 1158 "Technoton Electroics" 1160 "MG Energy Systems" 1169 "Sea Machine Robotics" 1171 "Vista Manufacturing" 1183 "Zipwake" 1186 "Sailmon" 1192 "Airmoniq Pro Kft" 1194 "Sierra Marine" 1200 "Xinuo Information Technology (Xiamen)" 1218 "Septentrio" 1233 "NKE Marine Electronics" 1238 "SuperTrack Aps" 1239 "Honda Electronics" 1245 "Raritan Engineering" 1249 "Integrated Power Solutions AG" 1260 "Interactive Technologies" 1283 "LTG-Tech" 1299 "Energy Solutions (UK)" 1300 "WATT Fuel Cell" 1302 "Pro Mainer" 1305 "Dragonfly Energy" 1306 "Koden Electronics" 1311 "Humphree" 1316 "Hinkley Yachts" 1317 "Global Marine Management GmbH (GMM)" 1320 "Triskel Marine" 1330 "Warwick Control Technologies" 1331 "Dolphin Charger" 1337 "Barnacle Systems" 1348 "Radian IoT" 1353 "Ocean LED Marine" 1359 "BluNav" 1361 "OVA (Nantong Saiyang Electronics Co., Ltd)" 1368 "RAD Propulsion" 1369 "Electric Yacht" 1372 "Elco Motor Yachts" 1384 "Tecnoseal Foundry S.r.l" 1385 "Pro Charging Systems" 1389 "EVEX" 1398 "Gobius Sensor Technology" 1403 "Arco Marine" 1408 "Lenco Marine" 1413 "Naocontrol" 1417 "Revatek" 1438 "Aeolionics" 1439 "PredictWind" 1440 "Egis Mobile Electric" 1445 "Starboard Yacht Group" 1446 "Roswell Marine" 1451 "ePropulsion (Guangdong ePropulsion Technology Ltd.)" 1452 "Micro-Air" 1453 "Vital Battery" 1458 "Ride Controller" 1460 "Tocaro Blue" 1461 "Vanquish Yachts" 1471 "FT Technologies" 1478 "Alps Alpine" 1481 "E-Force Marine" 1482 "CMC Marine" 1483 "Nanjing Sandemarine Information Technology" 1850 "Teleflex Marine (SeaStar Solutions)" 1851 "Raymarine" 1852 "Navionics" 1853 "Japan Radio" 1854 "Northstar Technologies" 1855 "Furuno" 1856 "Trimble" 1857 "Simrad" 1858 "Litton" 1859 "Kvasar" 1860 "MMP" 1861 "Vector Cantech" 1862 "Yamaha Marine" 1863 "Faria Instruments" ;
VAL_ 2583633152 Industry_Code 0 "Global" 1 "Highway" 2 "Agriculture" 3 "Construction" 4 "Marine Industry" 5 "Industrial" ;
VAL_ 2583633152 Manufacturer_Code 69 "ARKS Enterprises" 78 "FW Murphy/Enovation Controls" 80 "Twin Disc" 85 "Kohler Power Systems" 88 "Hemisphere GPS" 135 "Airmar" 137 "Maretron" 140 "Lowrance" 144 "Mercury Marine" 147 "Nautibus Electronic" 148 "Blue Water Data" 154 "Westerbeke" 157 "ISSPRO" 161 "Offshore Systems (UK)" 163 "Evinrude/BRP" 165 "CPAC Systems" 168 "Xantrex Technology" 169 "Marlin Technologies" 172 "Yanmar Marine" 174 "Volvo Penta" 176 "Carling Technologies Inc. (Moritz Aerospace)" 185 "Beede Instruments" 192 "Floscan Instrument" 193 "Nobeltec" 198 "Mystic Valley Communications" 199 "Actia" 201 "Disenos Y Technologia" 211 "Digital Switching Systems" 215 "Xintex/Atena" 224 "EMMI NETWORK" 228 "ZF" 229 "Garmin" 233 "Yacht Monitoring Solutions" 235 "Sailormade Marine Telemetry/Tetra Technology" 243 "Eride" 257 "Honda Motor" 272 "Groco" 273 "Actisense" 274 "Amphenol LTW Technology" 275 "Navico" 283 "Hamilton Jet" 285 "Sea Recovery" 286 "Coelmo SRL Italy" 295 "BEP Marine" 304 "Empir Bus" 305 "NovAtel" 306 "Sleipner Motor" 307 "MBW Technologies" 315 "ICOM" 328 "Qwerty" 329 "Dief" 341 "Boening Automationstechnologie" 345 "Korean Maritime University" 351 "Thrane and Thrane" 355 "Mastervolt" 356 "Fischer Panda Generators" 358 "Victron Energy" 370 "Rolls Royce Marine" 373 "Electronic Design" 374 "Northern Lights" 378 "Glendinning" 381 "B & G" 384 "Rose Point Navigation Systems" 385 "Johnson Outdoors Marine Electronics Inc Geonav" 394 "Capi 2" 396 "Beyond Measure" 400 "Livorsi Marine" 404 "ComNav" 409 "Chetco" 419 "Fusion Electronics" 421 "Standard Horizon" 422 "True Heading" 426 "Egersund Marine Electronics" 427 "em-trak Marine Electronics" 431 "Tohatsu Co, JP" 437 "Digital Yacht" 438 "Comar Systems Limited" 440 "Cummins" 443 "VDO (aka Continental-Corporation)" 451 "Parker Hannifin aka Village Marine Tech" 459 "Alltek Marine Electronics" 460 "SAN GIORGIO S.E.I.N" 466 "Veethree Electronics & Marine" 470 "SI-TEX Marine Electronics" 471 "Sea Cross Marine" 475 "GME aka Standard Communications" 476 "Humminbird Marine Electronics" 478 "Ocean Sat" 481 "Chetco Digital Instruments" 493 "Watcheye" 499 "Lcj Capteurs" 502 "Attwood Marine" 503 "Naviop S.R.L." 504 "Vesper Marine" 510 "Marinesoft" 513 "Simarine" 517 "NoLand Engineering" 518 "Transas USA" 529 "National Instruments Korea" 530 "National Marine Electronics Association" 532 "Onwa Marine" 540 "Webasto" 571 "Marinecraft (South Korea)" 573 "McMurdo Group aka Orolia" 578 "Advansea" 579 "KVH" 580 "San Jose Technology" 583 "Yacht Control" 586 "Suzuki Motor" 591 "US Coast Guard" 595 "Ship Module aka Customware" 600 "Aquatic AV" 605 "Aventics" 606 "Intellian" 612 "SamwonIT" 614 "Arlt Tecnologies" 637 "Bavaria Yachts" 641 "Diverse Yacht Services" 644 "Wema U.S.A dba KUS" 658 "Shenzhen Jiuzhou Himunication" 688 "Rockford" 699 "Harman International" 704 "JL Audio" 708 "Lars Thrane" 715 "Autonnic" 717 "Yacht Devices" 734 "REAP Systems" 735 "AEM Performance Electronics" 739 "LxNav" 741 "Littelfuse, Inc (formerly Carling Technologies)" 743 "DaeMyung" 744 "Woosung" 748 "ISOTTA IFRA srl" 773 "Clarion US" 776 "HMI Systems" 777 "Ocean Signal" 778 "Seakeeper" 781 "Poly Planar" 785 "Fischer Panda DE" 795 "Broyda Industries" 796 "Canadian Automotive" 797 "Tides Marine" 798 "Lumishore" 799 "Still Water Designs and Audio" 802 "BJ Technologies (Beneteau)" 803 "Gill Sensors" 811 "Blue Water Desalination" 815 "FLIR" 824 "Undheim Systems" 826 "Lewmar" 838 "TeamSurv" 844 "Fell Marine" 847 "Oceanvolt" 862 "Prospec" 868 "Data Panel" 890 "L3 Technologies" 894 "Rhodan Marine Systems" 896 "Nexfour Solutions" 905 "ASA Electronics" 909 "Marines Co (South Korea)" 911 "Nautic-on" 917 "Sentinel" 929 "JL Marine Systems" 930 "Ecotronix" 944 "Zontisa Marine" 951 "EXOR International" 962 "Timbolier Industries" 963 "TJC Micro" 968 "Cox Powertrain" 969 "Blue Seas" 981 "Kobelt Manufacturing" 992 "Blue Ocean IOT" 997 "Xenta Systems" 999 "Signal K" 1004 "Ultraflex" 1008 "Lintest SmartBoat" 1011 "Soundmax" 1020 "Team Italia Marine (Onyx Marine Automation s.r.l)" 1021 "Entratech" 1022 "ITC" 1029 "The Marine Guardian" 1047 "Sonic" 1051 "ProNav" 1053 "Vetus Maxwell INC." 1056 "Lithium Pros" 1059 "Boatrax" 1062 "Marol Co ltd" 1065 "CALYPSO Instruments" 1066 "Spot Zero Water" 1069 "Lithionics Battery" 1070 "Quick-teck Electronics" 1075 "Uniden America" 1083 "Nauticoncept" 1084 "Shadow-Caster LED lighting" 1085 "Wet Sounds" 1088 "E-T-A Circuit Breakers" 1092 "Scheiber" 1100 "Smart Yachts International Limited" 1109 "Dockmate" 1114 "Bobs Machine" 1118 "L3Harris ASV" 1119 "Balmar" 1120 "Elettromedia" 1127 "Electromaax" 1140 "Across Oceans Systems" 1145 "Kiwi Yachting" 1150 "BSB Artificial Intelligence" 1151 "Orca Technologies" 1154 "TBS Electronics" 1158 "Technoton Electroics" 1160 "MG Energy Systems" 1169 "Sea Machine Robotics" 1171 "Vista Manufacturing" 1183 "Zipwake" 1186 "Sailmon" 1192 "Airmoniq Pro Kft" 1194 "Sierra Marine" 1200 "Xinuo Information Technology (Xiamen)" 1218 "Septentrio" 1233 "NKE Marine Electronics" 1238 "SuperTrack Aps" 1239 "Honda Electronics" 1245 "Raritan Engineering" 1249 "Integrated Power Solutions AG" 1260 "Interactive Technologies" 1283 "LTG-Tech" 1299 "Energy Solutions (UK)" 1300 "WATT Fuel Cell" 1302 "Pro Mainer" 1305 "Dragonfly Energy" 1306 "Koden Electronics" 1311 "Humphree" 1316 "Hinkley Yachts" 1317 "Global Marine Management GmbH (GMM)" 1320 "Triskel Marine" 1330 "Warwick Control Technologies" 1331 "Dolphin Charger" 1337 "Barnacle Systems" 1348 "Radian IoT" 1353 "Ocean LED Marine" 1359 "BluNav" 1361 "OVA (Nantong Saiyang Electronics Co., Ltd)" 1368 "RAD Propulsion" 1369 "Electric Yacht" 1372 "Elco Motor Yachts" 1384 "Tecnoseal Foundry S.r.l" 1385 "Pro Charging Systems" 1389 "EVEX" 1398 "Gobius Sensor Technology" 1403 "Arco Marine" 1408 "Lenco Marine" 1413 "Naocontrol" 1417 "Revatek" 1438 "Aeolionics" 1439 "PredictWind" 1440 "Egis Mobile Electric" 1445 "Starboard Yacht Group" 1446 "Roswell Marine" 1451 "ePropulsion (Guangdong ePropulsion Technology Ltd.)" 1452 "Micro-Air" 1453 "Vital Battery" 1458 "Ride Controller" 1460 "Tocaro Blue" 1461 "Vanquish Yachts" 1471 "FT Technologies" 1478 "Alps Alpine" 1481 "E-Force Marine" 1482 "CMC Marine" 1483 "Nanjing Sandemarine Information Technology" 1850 "Teleflex Marine (SeaStar Solutions)" 1851 "Raymarine" 1852 "Navionics" 1853 "Japan Radio" 1854 "Northstar Technologies" 1855 "Furuno" 1856 "Trimble" 1857 "Simrad" 1858 "Litton" 1859 "Kvasar" 1860 "MMP" 1861 "Vector Cantech" 1862 "Yamaha Marine" 1863 "Faria Instruments" ;
VAL_ 2583633152 Industry_Code 0 "Global" 1 "Highway" 2 "Agriculture" 3 "Construction" 4 "Marine Industry" 5 "Industrial" ;
VAL_ 2583633152 Manufacturer_Code 69 "ARKS Enterprises" 78 "FW Murphy/Enovation Controls" 80 "Twin Disc" 85 "Kohler Power Systems" 88 "Hemisphere GPS" 135 "Airmar" 137 "Maretron" 140 "Lowrance" 144 "Mercury Marine" 147 "Nautibus Electronic" 148 "Blue Water Data" 154 "Westerbeke" 157 "ISSPRO" 161 "Offshore Systems (UK)" 163 "Evinrude/BRP" 165 "CPAC Systems" 168 "Xantrex Technology" 169 "Marlin Technologies" 172 "Yanmar Marine" 174 "Volvo Penta" 176 "Carling Technologies Inc. (Moritz Aerospace)" 185 "Beede Instruments" 192 "Floscan Instrument" 193 "Nobeltec" 198 "Mystic Valley Communications" 199 "Actia" 201 "Disenos Y Technologia" 211 "Digital Switching Systems" 215 "Xintex/Atena" 224 "EMMI NETWORK" 228 "ZF" 229 "Garmin" 233 "Yacht Monitoring Solutions" 235 "Sailormade Marine Telemetry/Tetra Technology" 243 "Eride" 257 "Honda Motor" 272 "Groco" 273 "Actisense" 274 "Amphenol LTW Technology" 275 "Navico" 283 "Hamilton Jet" 285 "Sea Recovery" 286 "Coelmo SRL Italy" 295 "BEP Marine" 304 "Empir Bus" 305 "NovAtel" 306 "Sleipner Motor" 307 "MBW Technologies" 315 "ICOM" 328 "Qwerty" 329 "Dief" 341 "Boening Automationstechnologie" 345 "Korean Maritime University" 351 "Thrane and Thrane" 355 "Mastervolt" 356 "Fischer Panda Generators" 358 "Victron Energy" 370 "Rolls Royce Marine" 373 "Electronic Design" 374 "Northern Lights" 378 "Glendinning" 381 "B & G" 384 "Rose Point Navigation Systems" 385 "Johnson Outdoors Marine Electronics Inc Geonav" 394 "Capi 2" 396 "Beyond Measure" 400 "Livorsi Marine" 404 "ComNav" 409 "Chetco" 419 "Fusion Electronics" 421 "Standard Horizon" 422 "True Heading" 426 "Egersund Marine Electronics" 427 "em-trak Marine Electronics" 431 "Tohatsu Co, JP" 437 "Digital Yacht" 438 "Comar Systems Limited" 440 "Cummins" 443 "VDO (aka Continental-Corporation)" 451 "Parker Hannifin aka Village Marine Tech" 459 "Alltek Marine Electronics" 460 "SAN GIORGIO S.E.I.N" 466 "Veethree Electronics & Marine" 470 "SI-TEX Marine Electronics" 471 "Sea Cross Marine" 475 "GME aka Standard Communications" 476 "Humminbird Marine Electronics" 478 "Ocean Sat" 481 "Chetco Digital Instruments" 493 "Watcheye" 499 "Lcj Capteurs" 502 "Attwood Marine" 503 "Naviop S.R.L." 504 "Vesper Marine" 510 "Marinesoft" 513 "Simarine" 517 "NoLand Engineering" 518 "Transas USA" 529 "National Instruments Korea" 530 "National Marine Electronics Association" 532 "Onwa Marine" 540 "Webasto" 571 "Marinecraft (South Korea)" 573 "McMurdo Group aka Orolia" 578 "Advansea" 579 "KVH" 580 "San Jose Technology" 583 "Yacht Control" 586 "Suzuki Motor" 591 "US Coast Guard" 595 "Ship Module aka Customware" 600 "Aquatic AV" 605 "Aventics" 606 "Intellian" 612 "SamwonIT" 614 "Arlt Tecnologies" 637 "Bavaria Yachts" 641 "Diverse Yacht Services" 644 "Wema U.S.A dba KUS" 658 "Shenzhen Jiuzhou Himunication" 688 "Rockford" 699 "Harman International" 704 "JL Audio" 708 "Lars Thrane" 715 "Autonnic" 717 "Yacht Devices" 734 "REAP Systems" 735 "AEM Performance Electronics" 739 "LxNav" 741 "Littelfuse, Inc (formerly Carling Technologies)" 743 "DaeMyung" 744 "Woosung" 748 "ISOTTA IFRA srl" 773 "Clarion US" 776 "HMI Systems" 777 "Ocean Signal" 778 "Seakeeper" 781 "Poly Planar" 785 "Fischer Panda DE" 795 "Broyda Industries" 796 "Canadian Automotive" 797 "Tides Marine" 798 "Lumishore" 799 "Still Water Designs and Audio" 802 "BJ Technologies (Beneteau)" 803 "Gill Sensors" 811 "Blue Water Desalination" 815 "FLIR" 824 "Undheim Systems" 826 "Lewmar" 838 "TeamSurv" 844 "Fell Marine" 847 "Oceanvolt" 862 "Prospec" 868 "Data Panel" 890 "L3 Technologies" 894 "Rhodan Marine Systems" 896 "Nexfour Solutions" 905 "ASA Electronics" 909 "Marines Co (South Korea)" 911 "Nautic-on" 917 "Sentinel" 929 "JL Marine Systems" 930 "Ecotronix" 944 "Zontisa Marine" 951 "EXOR International" 962 "Timbolier Industries" 963 "TJC Micro" 968 "Cox Powertrain" 969 "Blue Seas" 981 "Kobelt Manufacturing" 992 "Blue Ocean IOT" 997 "Xenta Systems" 999 "Signal K" 1004 "Ultraflex" 1008 "Lintest SmartBoat" 1011 "Soundmax" 1020 "Team Italia Marine (Onyx Marine Automation s.r.l)" 1021 "Entratech" 1022 "ITC" 1029 "The Marine Guardian" 1047 "Sonic" 1051 "ProNav" 1053 "Vetus Maxwell INC." 1056 "Lithium Pros" 1059 "Boatrax" 1062 "Marol Co ltd" 1065 "CALYPSO Instruments" 1066 "Spot Zero Water" 1069 "Lithionics Battery" 1070 "Quick-teck Electronics" 1075 "Uniden America" 1083 "Nauticoncept" 1084 "Shadow-Caster LED lighting" 1085 "Wet Sounds" 1088 "E-T-A Circuit Breakers" 1092 "Scheiber" 1100 "Smart Yachts International Limited" 1109 "Dockmate" 1114 "Bobs Machine" 1118 "L3Harris ASV" 1119 "Balmar" 1120 "Elettromedia" 1127 "Electromaax" 1140 "Across Oceans Systems" 1145 "Kiwi Yachting" 1150 "BSB Artificial Intelligence" 1151 "Orca Technologies" 1154 "TBS Electronics" 1158 "Technoton Electroics" 1160 "MG Energy Systems" 1169 "Sea Machine Robotics" 1171 "Vista Manufacturing" 1183 "Zipwake" 1186 "Sailmon" 1192 "Airmoniq Pro Kft" 1194 "Sierra Marine" 1200 "Xinuo Information Technology (Xiamen)" 1218 "Septentrio" 1233 "NKE Marine Electronics" 1238 "SuperTrack Aps" 1239 "Honda Electronics" 1245 "Raritan Engineering" 1249 "Integrated Power Solutions AG" 1260 "Interactive Technologies" 1283 "LTG-Tech" 1299 "Energy Solutions (UK)" 1300 "WATT Fuel Cell" 1302 "Pro Mainer" 1305 "Dragonfly Energy" 1306 "Koden Electronics" 1311 "Humphree" 1316 "Hinkley Yachts" 1317 "Global Marine Management GmbH (GMM)" 1320 "Triskel Marine" 1330 "Warwick Control Technologies" 1331 "Dolphin Charger" 1337 "Barnacle Systems" 1348 "Radian IoT" 1353 "Ocean LED Marine" 1359 "BluNav" 1361 "OVA (Nantong Saiyang Electronics Co., Ltd)" 1368 "RAD Propulsion" 1369 "Electric Yacht" 1372 "Elco Motor Yachts" 1384 "Tecnoseal Foundry S.r.l" 1385 "Pro Charging Systems" 1389 "EVEX" 1398 "Gobius Sensor Technology" 1403 "Arco Marine" 1408 "Lenco Marine" 1413 "Naocontrol" 1417 "Revatek" 1438 "Aeolionics" 1439 "PredictWind" 1440 "Egis Mobile Electric" 1445 "Starboard Yacht Group" 1446 "Roswell Marine" 1451 "ePropulsion (Guangdong ePropulsion Technology Ltd.)" 1452 "Micro-Air" 1453 "Vital Battery" 1458 "Ride Controller" 1460 "Tocaro Blue" 1461 "Vanquish Yachts" 1471 "FT Technologies" 1478 "Alps Alpine" 1481 "E-Force Marine" 1482 "CMC Marine" 1483 "Nanjing Sandemarine Information Technology" 1850 "Teleflex Marine (SeaStar Solutions)" 1851 "Raymarine" 1852 "Navionics" 1853 "Japan Radio" 1854 "Northstar Technologies" 1855 "Furuno" 1856 "Trimble" 1857 "Simrad" 1858 "Litton" 1859 "Kvasar" 1860 "MMP" 1861 "Vector Cantech" 1862 "Yamaha Marine" 1863 "Faria Instruments" ;
VAL_ 2583633152 Industry_Code 0 "Global" 1 "Highway" 2 "Agriculture" 3 "Construction" 4 "Marine Industry" 5 "Industrial" ;
VAL_ 2583633152 Network_Group 0 "None" 1 "Default" 2 "Group 1" 3 "Group 2" 4 "Group 3" 5 "Group 4" 6 "Group 5" 7 "Group 6" ;
VAL_ 2583633152 Operation 0 "Read" 1 "Set" 2 "Reply" ;
CM_ SG_ 2583632384 Name "STRING field: decode bytes as ASCII (0x00/@/0xFF = terminator); canboat type: STRING_FIX";
CM_ SG_ 2583632384 Vendor_ID "STRING field: decode bytes as ASCII (0x00/@/0xFF = terminator); canboat type: STRING_FIX";
CM_ SG_ 2583632384 Callsign "STRING field: decode bytes as ASCII (0x00/@/0xFF = terminator); canboat type: STRING_FIX";

BA_DEF_ BO_ "GenMsgCycleTime" INT 0 60000;
BA_DEF_ BO_ "ProtocolType" STRING;

BA_DEF_ BO_ "J1939PGN" INT 0 262143;
BA_ "J1939PGN" BO_ 2583631104 130837;
BA_ "GenMsgCycleTime" BO_ 2583631104 15000;
BA_ "J1939PGN" BO_ 2583631104 130837;
BA_ "J1939PGN" BO_ 2583631104 130837;
BA_ "J1939PGN" BO_ 2583631360 130838;
BA_ "J1939PGN" BO_ 2583631360 130838;
BA_ "J1939PGN" BO_ 2583631360 130838;
BA_ "J1939PGN" BO_ 2583631616 130839;
BA_ "J1939PGN" BO_ 2583631872 130840;
BA_ "J1939PGN" BO_ 2382305280 130840;
BA_ "J1939PGN" BO_ 2583632128 130841;
BA_ "J1939PGN" BO_ 2583632384 130842;
BA_ "J1939PGN" BO_ 2583632384 130842;
BA_ "J1939PGN" BO_ 2583632384 130842;
BA_ "J1939PGN" BO_ 2583632384 130842;
BA_ "J1939PGN" BO_ 2583632384 130842;
BA_ "J1939PGN" BO_ 2583632640 130843;
BA_ "GenMsgCycleTime" BO_ 2583632640 100;
BA_ "J1939PGN" BO_ 2583632640 130843;
BA_ "J1939PGN" BO_ 2583632640 130843;
BA_ "J1939PGN" BO_ 2583632896 130844;
BA_ "J1939PGN" BO_ 2583633152 130845;
BA_ "J1939PGN" BO_ 2583633152 130845;
BA_ "J1939PGN" BO_ 2583633152 130845;
